VERSION ""

NS_ :

BS_:

BU_: SIDHigh IC HMIIOM ECUspare8

BO_ 2671902706 TesterFuncDiagMsg_Disp: 8 HMIIOM
 SG_ FuncDiagDataTester : 0|64@1+ (1,0) [0|0] ""  IC,SIDHigh

BO_ 2549448703 SIDHigh_TIPSITP_SIDHB_Down_H: 8 SIDHigh
 SG_ TIPSITP_SIDHeartbeat_Down_H : 0|64@1+ (1,0) [0|0] ""  HMIIOM

BO_ 2532663295 SIDHigh_TIPSITP_SIDData_Down_H5: 8 SIDHigh
 SG_ TIPSITP_SIDData_Down_H5 : 0|64@1+ (1,0) [0|0] ""  HMIIOM

BO_ 2532597759 SIDHigh_TIPSITP_SIDData_Down_H4: 8 SIDHigh
 SG_ TIPSITP_SIDData_Down_H4 : 0|64@1+ (1,0) [0|0] ""  HMIIOM

BO_ 2532532223 SIDHigh_TIPSITP_SIDData_Down_H3: 8 SIDHigh
 SG_ TIPSITP_SIDData_Down_H3 : 0|64@1+ (1,0) [0|0] ""  HMIIOM

BO_ 2532466687 SIDHigh_TIPSITP_SIDData_Down_H2: 8 SIDHigh
 SG_ TIPSITP_SIDData_Down_H2 : 0|64@1+ (1,0) [0|0] ""  HMIIOM

BO_ 2532401151 SIDHigh_TIPSITP_SIDData_Down_H1: 8 SIDHigh
 SG_ TIPSITP_SIDData_Down_H1 : 0|64@1+ (1,0) [0|0] ""  HMIIOM

BO_ 2515959807 SIDHigh_TIPSITP_SIDCtrl_Down_H: 8 SIDHigh
 SG_ TIPSITP_SIDCtrl_Down_H : 0|64@1+ (1,0) [0|0] ""  HMIIOM

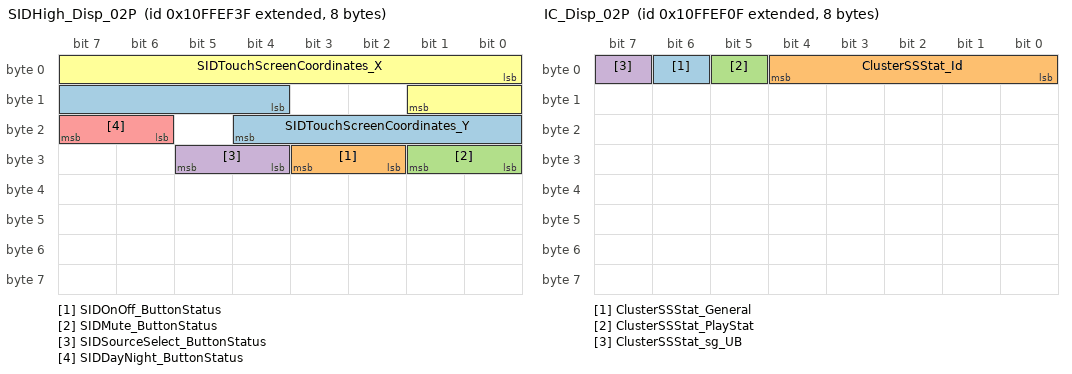
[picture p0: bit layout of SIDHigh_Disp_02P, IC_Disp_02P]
BO_ 2432692031 SIDHigh_Disp_02P: 8 SIDHigh
 SG_ SIDTouchScreenCoordinates_Y : 12|9@1+ (1,0) [0|511] ""  HMIIOM
 SG_ SIDOnOff_ButtonStatus : 26|2@1+ (1,0) [0|0] ""  HMIIOM
 SG_ SIDMute_ButtonStatus : 24|2@1+ (1,0) [0|0] ""  HMIIOM
 SG_ SIDSourceSelect_ButtonStatus : 28|2@1+ (1,0) [0|0] ""  HMIIOM
 SG_ SIDDayNight_ButtonStatus : 22|2@1+ (1,0) [0|0] ""  HMIIOM
 SG_ SIDTouchScreenCoordinates_X : 0|10@1+ (1,0) [0|1023] ""  HMIIOM

BO_ 2671833698 PhysDiagRespMsg_F2_62_Disp: 8 SIDHigh
 SG_ PhysDiagRespSig_F2_62 : 0|64@1+ (1,0) [0|0] ""  HMIIOM

BO_ 2671833697 PhysDiagRespMsg_F2_61_Disp: 8 IC
 SG_ PhysDiagRespSig_F2_61 : 0|64@1+ (1,0) [0|0] ""  HMIIOM

BO_ 2671796978 PhysDiagReqMsg_62_F2_Disp: 8 HMIIOM
 SG_ PhysDiagReqSig_62_F2 : 0|64@1+ (1,0) [0|0] ""  SIDHigh

BO_ 2671796722 PhysDiagReqMsg_61_F2_Disp: 8 HMIIOM
 SG_ PhysDiagReqSig_61_F2 : 0|64@1+ (1,0) [0|0] ""  IC

BO_ 2633990242 NmAsr_SIDHigh_Disp: 1 SIDHigh

BO_ 2633990241 NmAsr_IC_Disp: 1 IC

BO_ 2633990240 NmAsr_HMIIOM_Disp: 1 HMIIOM

BO_ 2671902708 IntTesterTGW2FuncDiagMsg_Disp: 8 HMIIOM
 SG_ FuncDiagDataIntTesterTGW2 : 0|64@1+ (1,0) [0|0] ""  SIDHigh,IC

BO_ 2549579775 IC_TIPSITP_SIDHeartbeat_Down_L: 8 IC
 SG_ TIPSITP_SIDHeartbeat_Down_L : 0|64@1+ (1,0) [0|0] ""  HMIIOM

BO_ 2532409343 IC_TIPSITP_SIDData_Down_L1: 8 IC
 SG_ TIPSITP_SIDData_Down_L1 : 0|64@1+ (1,0) [0|0] ""  HMIIOM

BO_ 2532671487 IC_TIPSITP_SIDDATA_Down_L5: 8 IC
 SG_ TIPSITP_SIDData_Down_L5 : 0|64@1+ (1,0) [0|0] ""  HMIIOM

BO_ 2532605951 IC_TIPSITP_SIDDATA_Down_L4: 8 IC
 SG_ TIPSITP_SIDData_Down_L4 : 0|64@1+ (1,0) [0|0] ""  HMIIOM

BO_ 2532540415 IC_TIPSITP_SIDDATA_Down_L3: 8 IC
 SG_ TIPSITP_SIDData_Down_L3 : 0|64@1+ (1,0) [0|0] ""  HMIIOM

BO_ 2532474879 IC_TIPSITP_SIDDATA_Down_L2: 8 IC
 SG_ TIPSITP_SIDData_Down_L2 : 0|64@1+ (1,0) [0|0] ""  HMIIOM

BO_ 2516090879 IC_TIPSITP_SIDCtrl_Down_L: 8 IC
 SG_ TIPSITP_SIDCtrl_Down_L : 0|64@1+ (1,0) [0|0] ""  HMIIOM

BO_ 2549907455 IC_TIPSITP_FDCHeartbeat_Down: 8 IC
 SG_ TIPSITP_FDCHeartbeat_Down : 0|64@1+ (1,0) [0|0] ""  HMIIOM

BO_ 2533195775 IC_TIPSITP_FDCData_Down: 8 IC
 SG_ TIPSITP_FDCData_Down : 0|64@1+ (1,0) [0|0] ""  HMIIOM

BO_ 2516221951 IC_TIPSITP_FDCCtrl_Down: 8 IC
 SG_ TIPSITP_FDCCtrl_Down : 0|64@1+ (1,0) [0|0] ""  HMIIOM

BO_ 2549841919 IC_TIPSITP_DIDHeartbeat_Down: 8 IC
 SG_ TIPSITP_DIDHeartbeat_Down : 0|64@1+ (1,0) [0|0] ""  HMIIOM

BO_ 2533130249 IC_TIPSITP_DIDData_Down6: 8 IC
 SG_ TIPSITP_DIDData_Down6 : 0|64@1+ (1,0) [0|0] ""  HMIIOM

BO_ 2533130247 IC_TIPSITP_DIDData_Down5: 8 IC
 SG_ TIPSITP_DIDData_Down5 : 0|64@1+ (1,0) [0|0] ""  HMIIOM

BO_ 2533130245 IC_TIPSITP_DIDData_Down4: 8 IC
 SG_ TIPSITP_DIDData_Down4 : 0|64@1+ (1,0) [0|0] ""  HMIIOM

BO_ 2533130243 IC_TIPSITP_DIDData_Down3: 8 IC
 SG_ TIPSITP_DIDData_Down3 : 0|64@1+ (1,0) [0|0] ""  HMIIOM

BO_ 2533130241 IC_TIPSITP_DIDData_Down2: 8 IC
 SG_ TIPSITP_DIDData_Down2 : 0|64@1+ (1,0) [0|0] ""  HMIIOM

BO_ 2533130239 IC_TIPSITP_DIDData_Down1: 8 IC
 SG_ TIPSITP_DIDData_Down1 : 0|64@1+ (1,0) [0|0] ""  HMIIOM

BO_ 2516156415 IC_TIPSITP_DIDCtrl_Down: 8 IC
 SG_ TIPSITP_DIDCtrl_Down : 0|64@1+ (1,0) [0|0] ""  HMIIOM

BO_ 2432691983 IC_Disp_02P: 8 IC
 SG_ ClusterSSStat_General : 6|1@1+ (1,0) [0|0] ""  HMIIOM
 SG_ ClusterSSStat_Id : 0|5@1+ (1,0) [0|31] ""  HMIIOM
 SG_ ClusterSSStat_PlayStat : 5|1@1+ (1,0) [0|0] ""  HMIIOM
 SG_ ClusterSSStat_sg_UB : 7|1@1+ (1,0) [0|0] ""  HMIIOM

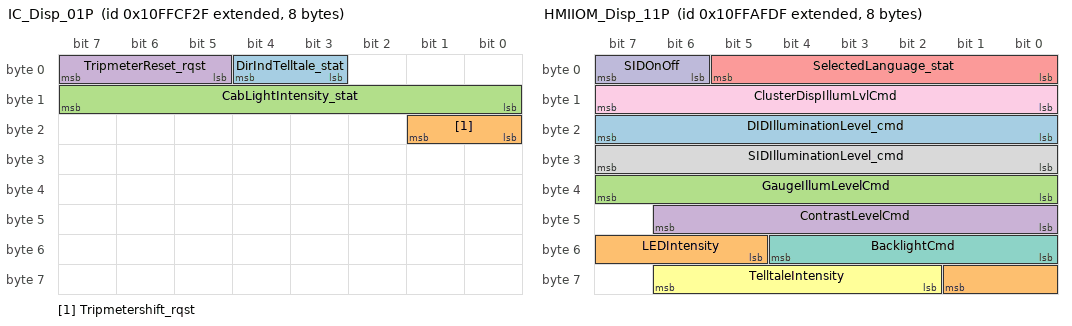
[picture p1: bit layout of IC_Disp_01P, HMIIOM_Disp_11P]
BO_ 2432683823 IC_Disp_01P: 8 IC
 SG_ DirIndTelltale_stat : 3|2@1+ (1,0) [0|0] ""  HMIIOM
 SG_ Tripmetershift_rqst : 16|2@1+ (1,0) [0|0] ""  HMIIOM
 SG_ CabLightIntensity_stat : 8|8@1+ (0.4,0) [0|102] "Percent"  HMIIOM
 SG_ TripmeterReset_rqst : 5|3@1+ (1,0) [0|0] ""  HMIIOM

BO_ 2549252095 HMIIOM_TIPSITP_SIDHeartbeat_Up: 8 HMIIOM
 SG_ TIPSITP_SIDHeartbeat_Up : 0|64@1+ (1,0) [0|0] ""  SIDHigh,IC

BO_ 2532655103 HMIIOM_TIPSITP_SIDData_Up5: 8 HMIIOM
 SG_ TIPSITP_SIDData_Up5 : 0|64@1+ (1,0) [0|0] ""  IC,SIDHigh

BO_ 2532589567 HMIIOM_TIPSITP_SIDData_Up4: 8 HMIIOM
 SG_ TIPSITP_SIDData_Up4 : 0|64@1+ (1,0) [0|0] ""  IC,SIDHigh

BO_ 2532524031 HMIIOM_TIPSITP_SIDData_Up3: 8 HMIIOM
 SG_ TIPSITP_SIDData_Up3 : 0|64@1+ (1,0) [0|0] ""  IC,SIDHigh

BO_ 2532458495 HMIIOM_TIPSITP_SIDData_Up2: 8 HMIIOM
 SG_ TIPSITP_SIDData_Up2 : 0|64@1+ (1,0) [0|0] ""  IC,SIDHigh

BO_ 2532392959 HMIIOM_TIPSITP_SIDData_Up1: 8 HMIIOM
 SG_ TIPSITP_SIDData_Up1 : 0|64@1+ (1,0) [0|0] ""  SIDHigh,IC

BO_ 2515808255 HMIIOM_TIPSITP_SIDCtrl_Up: 8 HMIIOM
 SG_ TIPSITP_SIDCtrl_Up : 0|64@1+ (1,0) [0|0] ""  IC,SIDHigh

BO_ 2549317631 HMIIOM_TIPSITP_FDCHeartbeat_Up: 8 HMIIOM
 SG_ TIPSITP_FDCHeartbeat_Up : 0|64@1+ (1,0) [0|0] ""  IC

BO_ 2533105665 HMIIOM_TIPSITP_FDCData_Up: 8 HMIIOM
 SG_ TIPSITP_FDCData_Up : 0|64@1+ (1,0) [0|0] ""  IC

BO_ 2515828735 HMIIOM_TIPSITP_FDCCtrl_Up: 8 HMIIOM
 SG_ TIPSITP_FDCCtrl_Up : 0|64@1+ (1,0) [0|0] ""  IC

BO_ 2549186559 HMIIOM_TIPSITP_DIDHeartbeat_Up: 8 HMIIOM
 SG_ TIPSITP_DIDHeartbeat_Up : 0|64@1+ (1,0) [0|0] ""  IC

BO_ 2532974598 HMIIOM_TIPSITP_DIDData_Up6: 8 HMIIOM
 SG_ TIPSITP_DIDData_Up6 : 0|64@1+ (1,0) [0|0] ""  IC

BO_ 2532974597 HMIIOM_TIPSITP_DIDData_Up5: 8 HMIIOM
 SG_ TIPSITP_DIDData_Up5 : 0|64@1+ (1,0) [0|0] ""  IC

BO_ 2532974596 HMIIOM_TIPSITP_DIDData_Up4: 8 HMIIOM
 SG_ TIPSITP_DIDData_Up4 : 0|64@1+ (1,0) [0|0] ""  IC

BO_ 2532974595 HMIIOM_TIPSITP_DIDData_Up3: 8 HMIIOM
 SG_ TIPSITP_DIDData_Up3 : 0|64@1+ (1,0) [0|0] ""  IC

BO_ 2532974594 HMIIOM_TIPSITP_DIDData_Up2: 8 HMIIOM
 SG_ TIPSITP_DIDData_Up2 : 0|64@1+ (1,0) [0|0] ""  IC

BO_ 2532974593 HMIIOM_TIPSITP_DIDData_Up1: 8 HMIIOM
 SG_ TIPSITP_DIDData_Up1 : 0|64@1+ (1,0) [0|0] ""  IC

BO_ 2515763199 HMIIOM_TIPSITP_DIDCtrl_Up: 8 HMIIOM
 SG_ TIPSITP_DIDCtrl_Up : 0|64@1+ (1,0) [0|0] ""  IC

BO_ 2449452895 HMIIOM_Disp_12P: 8 HMIIOM
 SG_ PresVal_DrivingMode : 0|24@1+ (1,0) [0|0] ""  IC

BO_ 2432675807 HMIIOM_Disp_11P: 8 HMIIOM
 SG_ DIDIlluminationLevel_cmd : 16|8@1+ (1,0) [0|255] "Percent"  IC
 SG_ LEDIntensity : 53|5@1+ (1,0) [0|0] ""  IC
 SG_ GaugeIllumLevelCmd : 32|8@1+ (1,0) [0|255] "Percent"  IC
 SG_ ContrastLevelCmd : 40|7@1+ (1,0) [0|127] "Percent"  IC
 SG_ SelectedLanguage_stat : 0|6@1+ (1,0) [0|0] ""  IC,SIDHigh
 SG_ TelltaleIntensity : 58|5@1+ (1,0) [0|0] ""  IC
 SG_ BacklightCmd : 48|5@1+ (1,0) [0|0] ""  IC,SIDHigh
 SG_ SIDIlluminationLevel_cmd : 24|8@1+ (1,0) [0|255] "Percent"  SIDHigh,IC
 SG_ ClusterDispIllumLvlCmd : 8|8@1+ (1,0) [0|255] "Percent"  IC
 SG_ SIDOnOff : 6|2@1+ (1,0) [0|0] ""  SIDHigh

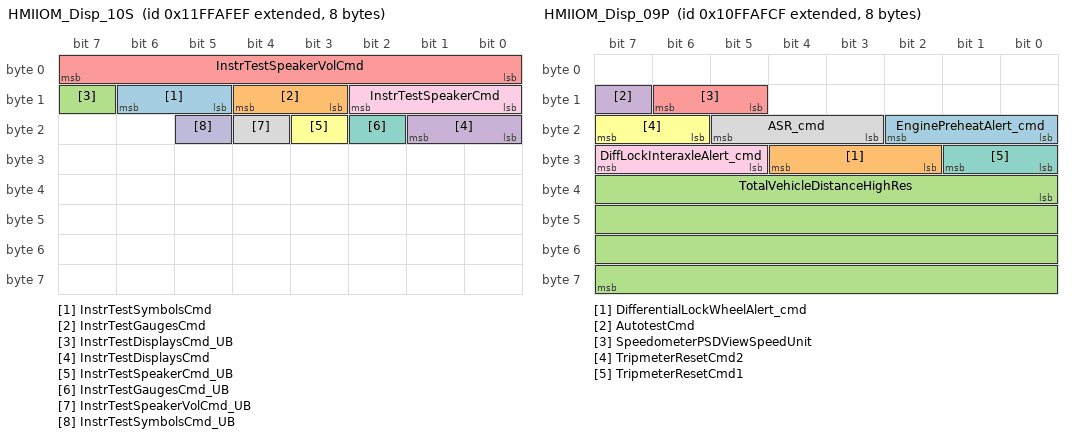
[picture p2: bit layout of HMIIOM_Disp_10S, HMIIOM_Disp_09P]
BO_ 2449453039 HMIIOM_Disp_10S: 8 HMIIOM
 SG_ InstrTestSymbolsCmd : 13|2@1+ (1,0) [0|0] ""  IC
 SG_ InstrTestGaugesCmd : 11|2@1+ (1,0) [0|0] ""  IC
 SG_ InstrTestDisplaysCmd_UB : 15|1@1+ (1,0) [0|1] ""  IC,SIDHigh
 SG_ InstrTestDisplaysCmd : 16|2@1+ (1,0) [0|0] ""  IC,SIDHigh
 SG_ InstrTestSpeakerVolCmd : 0|8@1+ (1,0) [0|255] ""  IC
 SG_ InstrTestSpeakerCmd_UB : 19|1@1+ (1,0) [0|1] ""  IC
 SG_ InstrTestGaugesCmd_UB : 18|1@1+ (1,0) [0|1] ""  IC
 SG_ InstrTestSpeakerVolCmd_UB : 20|1@1+ (1,0) [0|1] ""  IC
 SG_ InstrTestSpeakerCmd : 8|3@1+ (1,0) [0|0] ""  IC
 SG_ InstrTestSymbolsCmd_UB : 21|1@1+ (1,0) [0|1] ""  IC

BO_ 2432675791 HMIIOM_Disp_09P: 8 HMIIOM
 SG_ EnginePreheatAlert_cmd : 16|3@1+ (1,0) [0|0] ""  IC
 SG_ DifferentialLockWheelAlert_cmd : 26|3@1+ (1,0) [0|0] ""  IC
 SG_ TotalVehicleDistanceHighRes : 32|32@1+ (5,0) [0|21474836475] "m"  IC,SIDHigh
 SG_ AutotestCmd : 15|1@1+ (1,0) [0|0] ""  IC
 SG_ SpeedometerPSDViewSpeedUnit : 13|2@1+ (1,0) [0|0] ""  IC
 SG_ TripmeterResetCmd2 : 22|2@1+ (1,0) [0|0] ""  IC
 SG_ TripmeterResetCmd1 : 24|2@1+ (1,0) [0|0] ""  IC
 SG_ ASR_cmd : 19|3@1+ (1,0) [0|0] ""  IC
 SG_ DiffLockInteraxleAlert_cmd : 29|3@1+ (1,0) [0|0] ""  IC

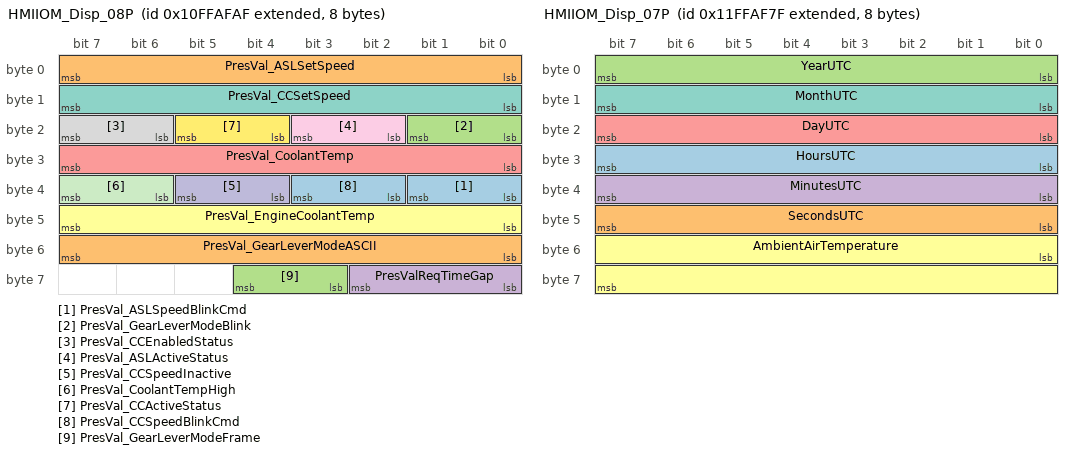
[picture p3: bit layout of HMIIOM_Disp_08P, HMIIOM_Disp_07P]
BO_ 2432675759 HMIIOM_Disp_08P: 8 HMIIOM
 SG_ PresVal_ASLSpeedBlinkCmd : 32|2@1+ (1,0) [0|0] ""  IC
 SG_ PresVal_ASLSetSpeed : 0|8@1+ (1,0) [0|255] "NotApplicable"  IC
 SG_ PresVal_GearLeverModeBlink : 16|2@1+ (1,0) [0|0] ""  IC
 SG_ PresValReqTimeGap : 56|3@1+ (1,0) [0|0] ""  IC
 SG_ PresVal_CoolantTemp : 24|8@1+ (1,-40) [-40|215] "DegreeC"  IC
 SG_ PresVal_EngineCoolantTemp : 40|8@1+ (0.4,0) [0|102] "Percent"  IC
 SG_ PresVal_CCSetSpeed : 8|8@1+ (1,0) [0|255] "NotApplicable"  IC
 SG_ PresVal_CCEnabledStatus : 22|2@1+ (1,0) [0|0] ""  IC
 SG_ PresVal_ASLActiveStatus : 18|2@1+ (1,0) [0|0] ""  IC
 SG_ PresVal_CCSpeedInactive : 36|2@1+ (1,0) [0|0] ""  IC
 SG_ PresVal_CoolantTempHigh : 38|2@1+ (1,0) [0|0] ""  IC
 SG_ PresVal_CCActiveStatus : 20|2@1+ (1,0) [0|0] ""  IC
 SG_ PresVal_CCSpeedBlinkCmd : 34|2@1+ (1,0) [0|0] ""  IC
 SG_ PresVal_GearLeverModeASCII : 48|8@1+ (1,0) [0|0] ""  IC
 SG_ PresVal_GearLeverModeFrame : 59|2@1+ (1,0) [0|0] ""  IC

BO_ 2449452927 HMIIOM_Disp_07P: 8 HMIIOM
 SG_ HoursUTC : 24|8@1+ (1,0) [0|255] "h"  SIDHigh,IC
 SG_ SecondsUTC : 40|8@1+ (0.25,0) [0|63.75] "s"  IC,SIDHigh
 SG_ YearUTC : 0|8@1+ (1,1985) [1985|2240] "Years"  SIDHigh,IC
 SG_ MinutesUTC : 32|8@1+ (1,0) [0|255] "min"  IC,SIDHigh
 SG_ DayUTC : 16|8@1+ (0.25,0) [0|63.75] "Days"  IC,SIDHigh
 SG_ AmbientAirTemperature : 48|16@1+ (0.03125,-273) [-273|1774.96875] "DegreeC"  IC,SIDHigh
 SG_ MonthUTC : 8|8@1+ (1,0) [0|255] "Months"  SIDHigh,IC

BO_ 2449452879 HMIIOM_Disp_06P: 8 HMIIOM
 SG_ PresVal_HighResTotalVehDist : 32|32@1+ (0.1,0) [0|429496729.5] ""  IC
 SG_ PresVal_HighResolutionTripDist : 0|32@1+ (0.1,0) [0|429496729.5] ""  IC

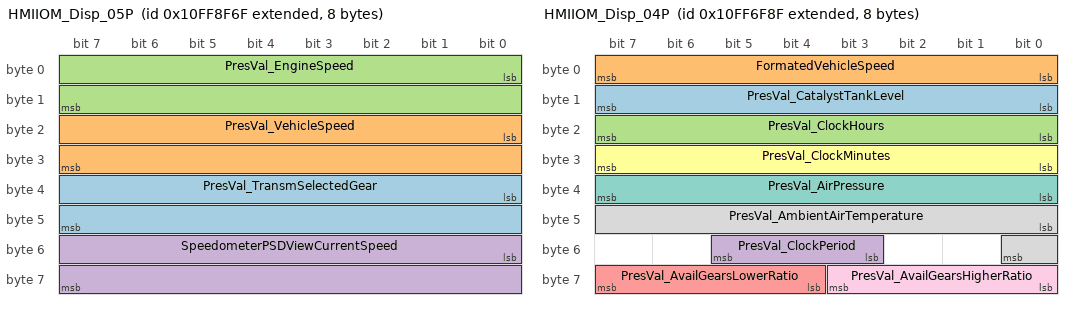
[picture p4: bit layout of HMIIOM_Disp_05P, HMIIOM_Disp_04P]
BO_ 2432667503 HMIIOM_Disp_05P: 8 HMIIOM
 SG_ PresVal_TransmSelectedGear : 32|16@1+ (1,0) [0|0] ""  IC
 SG_ PresVal_VehicleSpeed : 16|16@1+ (0.00390625,0) [0|255.99609375] "NotApplicable"  IC
 SG_ PresVal_EngineSpeed : 0|16@1+ (0.125,0) [0|8191.875] "rpm"  IC
 SG_ SpeedometerPSDViewCurrentSpeed : 48|16@1+ (0.00390625,0) [0|255.99609375] "NotApplicable"  IC

BO_ 2432659343 HMIIOM_Disp_04P: 8 HMIIOM
 SG_ PresVal_CatalystTankLevel : 8|8@1+ (0.4,0) [0|102] "Percent"  IC
 SG_ FormatedVehicleSpeed : 0|8@1+ (1,0) [0|255] "NotApplicable"  IC
 SG_ PresVal_ClockHours : 16|8@1+ (1,0) [0|255] "h"  IC
 SG_ PresVal_ClockPeriod : 51|3@1+ (1,0) [0|0] ""  IC
 SG_ PresVal_AvailGearsLowerRatio : 60|4@1+ (1,0) [0|15] "Count"  IC
 SG_ PresVal_ClockMinutes : 24|8@1+ (1,0) [0|255] "min"  IC
 SG_ PresVal_AirPressure : 32|8@1+ (8,0) [0|2040] "kPa"  IC
 SG_ PresVal_AmbientAirTemperature : 40|9@1+ (0.5,-60) [-60|195.5] "NotApplicable"  IC
 SG_ PresVal_AvailGearsHigherRatio : 56|4@1+ (1,0) [0|15] "Count"  IC

BO_ 2432651183 HMIIOM_Disp_03P: 8 HMIIOM
 SG_ PresVal_OdometerUnit : 8|2@1+ (1,0) [0|0] ""  IC
 SG_ ZoningBandsActiveBlueLEDRange2 : 47|3@1+ (1,0) [0|0] ""  IC
 SG_ ZoningBandsActiveBlueLEDRange1 : 26|3@1+ (1,0) [0|0] ""  IC
 SG_ PresVal_LowFuelLevelWrn_stat : 14|2@1+ (1,0) [0|0] ""  IC
 SG_ LCDFormattedVehSpdBlink_cmd : 29|2@1+ (1,0) [0|0] ""  IC
 SG_ PresVal_ACCReducedMode : 4|2@1+ (1,0) [0|0] ""  IC
 SG_ PresVal_FuelLevel : 56|8@1+ (0.4,0) [0|102] "Percent"  IC
 SG_ PresVal_AuxiliaryBrakesActivat : 20|2@1+ (1,0) [0|0] ""  IC
 SG_ PresVal_AmbientAirTempUnit : 24|2@1+ (1,0) [0|0] ""  IC
 SG_ PresVal_TargetDetected : 10|2@1+ (1,0) [0|0] ""  IC
 SG_ SeatBeltReminderAlert_cmd : 38|3@1+ (1,0) [0|0] ""  IC
 SG_ PresVal_CrossCountryStatus : 2|2@1+ (1,0) [0|0] ""  IC
 SG_ PresVal_TripmeterChoice : 16|2@1+ (1,0) [0|0] ""  IC
 SG_ ZoningBandsActiveGreenLEDRng2 : 44|3@1+ (1,0) [0|0] ""  IC
 SG_ SIDPresentationMode : 50|4@1+ (1,0) [0|0] ""  SIDHigh
 SG_ VehicleSpeedLCDSpeedUnitCmd : 22|2@1+ (1,0) [0|0] ""  IC
 SG_ PresVal_CatalystTankLevelLow : 18|2@1+ (1,0) [0|0] ""  IC
 SG_ PresVal_ACCStatus : 12|2@1+ (1,0) [0|0] ""  IC
 SG_ PresVal_AuxiliaryBrakesPos : 32|3@1+ (1,0) [0|0] ""  IC
 SG_ PresVal_EngSpdCtrlStatus : 54|2@1+ (1,0) [0|0] ""  IC
 SG_ ZoningBandsActiveRedLEDRange1 : 35|3@1+ (1,0) [0|0] ""  IC
 SG_ PresVal_LowAmbientTempWarning : 0|2@1+ (1,0) [0|0] ""  IC
 SG_ ZoningBandsActiveGreenLEDRng1 : 41|3@1+ (1,0) [0|0] ""  IC

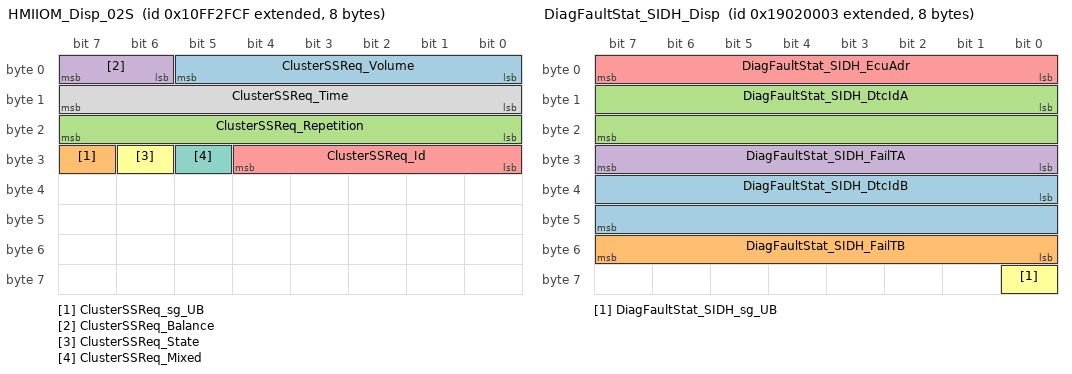
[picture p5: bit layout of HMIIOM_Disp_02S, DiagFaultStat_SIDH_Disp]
BO_ 2432643023 HMIIOM_Disp_02S: 8 HMIIOM
 SG_ ClusterSSReq_Volume : 0|6@1+ (1,0) [0|63] ""  IC
 SG_ ClusterSSReq_sg_UB : 31|1@1+ (1,0) [0|0] ""  IC
 SG_ ClusterSSReq_Repetition : 16|8@1+ (1,0) [0|255] ""  IC
 SG_ ClusterSSReq_Balance : 6|2@1+ (1,0) [0|0] ""  IC
 SG_ ClusterSSReq_Id : 24|5@1+ (1,0) [0|31] ""  IC
 SG_ ClusterSSReq_State : 30|1@1+ (1,0) [0|0] ""  IC
 SG_ ClusterSSReq_Mixed : 29|1@1+ (1,0) [0|0] ""  IC
 SG_ ClusterSSReq_Time : 8|8@1+ (0.1,0) [0|25.5] "s"  IC

BO_ 2432634863 HMIIOM_Disp_01P: 8 HMIIOM
 SG_ DippedBeamAlert_cmd : 15|3@1+ (1,0) [0|0] ""  IC
 SG_ VehicleMode : 54|4@1+ (1,0) [0|0] ""  IC,SIDHigh
 SG_ LiftAxle1Alert_cmd : 6|3@1+ (1,0) [0|0] ""  IC
 SG_ DirIndicatorRtTrailerAlert_cmd : 18|3@1+ (1,0) [0|0] ""  IC
 SG_ FogLightFrontAlert_cmd : 45|3@1+ (1,0) [0|0] ""  IC
 SG_ LiftAxle2Alert_cmd : 0|3@1+ (1,0) [0|0] ""  IC
 SG_ ExtraSpotLampsAlert_cmd : 24|3@1+ (1,0) [0|0] ""  IC
 SG_ AdBlueLevelLowAlert_cmd : 3|3@1+ (1,0) [0|0] ""  IC
 SG_ DirIndicatorLtTrailerAlert_cmd : 42|3@1+ (1,0) [0|0] ""  IC
 SG_ EngineMalFunctionAlert_cmd : 39|3@1+ (1,0) [0|0] ""  IC
 SG_ FuelLevelLowAlert_cmd : 36|3@1+ (1,0) [0|0] ""  IC
 SG_ PosLightAlert_cmd : 48|3@1+ (1,0) [0|0] ""  IC
 SG_ MainBeamAlert_cmd : 12|3@1+ (1,0) [0|0] ""  IC
 SG_ DirIndicatorRightAlert_cmd : 9|3@1+ (1,0) [0|0] ""  IC
 SG_ ParkBrakeAlert_cmd : 21|3@1+ (1,0) [0|0] ""  IC
 SG_ FogLightRearAlert_cmd : 30|3@1+ (1,0) [0|0] ""  IC
 SG_ DirIndicatorLeftAlert_cmd : 27|3@1+ (1,0) [0|0] ""  IC
 SG_ CheckAlert_cmd : 33|3@1+ (1,0) [0|0] ""  IC
 SG_ StopAlert_cmd : 51|3@1+ (1,0) [0|0] ""  IC
 SG_ VehicleMode_UB : 58|1@1+ (1,0) [0|0] ""  IC,SIDHigh

BO_ 2671964770 DiagUUDTRespMsg1_F2_62_Disp: 8 SIDHigh
 SG_ DiagUUDTRespSig_F2_62 : 0|64@1+ (1,0) [0|0] ""  HMIIOM

BO_ 2671964769 DiagUUDTRespMsg1_F2_61_Disp: 8 IC
 SG_ DiagUUDTRespSig_F2_61 : 0|64@1+ (1,0) [0|0] ""  HMIIOM

BO_ 2671834210 DiagRespMsgIntTGW2_F4_62_Disp: 8 SIDHigh
 SG_ InternalTesterDiagSig_F4_62 : 0|64@1+ (1,0) [0|0] ""  HMIIOM

BO_ 2671834209 DiagRespMsgIntTGW2_F4_61_Disp: 8 IC
 SG_ InternalTesterDiagSig_F4_61 : 0|64@1+ (1,0) [0|0] ""  HMIIOM

BO_ 2671833954 DiagRespMsgIntHMIIOM_F3_62_Disp: 8 SIDHigh
 SG_ InternalTesterDiagSig_F3_62 : 0|64@1+ (1,0) [0|0] ""  HMIIOM

BO_ 2671833953 DiagRespMsgIntHMIIOM_F3_61_Disp: 8 IC
 SG_ InternalTesterDiagSig_F3_61 : 0|64@1+ (1,0) [0|0] ""  HMIIOM

BO_ 2671796980 DiagReqMsgIntTGW2_62_F4_Disp: 8 HMIIOM
 SG_ InternalTesterDiagSig_62_F4 : 0|64@1+ (1,0) [0|0] ""  SIDHigh

BO_ 2671796724 DiagReqMsgIntTGW2_61_F4_Disp: 8 HMIIOM
 SG_ InternalTesterDiagSig_61_F4 : 0|64@1+ (1,0) [0|0] ""  IC

BO_ 2671796979 DiagReqMsgIntHMIIOM_62_F3_Disp: 8 HMIIOM
 SG_ InternalTesterDiagSig_62_F3 : 0|64@1+ (1,0) [0|0] ""  SIDHigh

BO_ 2671796723 DiagReqMsgIntHMIIOM_61_F3_Disp: 8 HMIIOM
 SG_ InternalTesterDiagSig_61_F3 : 0|64@1+ (1,0) [0|0] ""  IC

BO_ 2567045123 DiagFaultStat_SIDH_Disp: 8 SIDHigh
 SG_ DiagFaultStat_SIDH_DtcIdB : 32|16@1+ (1,0) [0|65535] ""  HMIIOM
 SG_ DiagFaultStat_SIDH_FailTB : 48|8@1+ (1,0) [0|255] ""  HMIIOM
 SG_ DiagFaultStat_SIDH_DtcIdA : 8|16@1+ (1,0) [0|65535] ""  HMIIOM
 SG_ DiagFaultStat_SIDH_FailTA : 24|8@1+ (1,0) [0|255] ""  HMIIOM
 SG_ DiagFaultStat_SIDH_EcuAdr : 0|8@1+ (1,0) [0|255] ""  HMIIOM
 SG_ DiagFaultStat_SIDH_sg_UB : 56|1@1+ (1,0) [0|0] ""  HMIIOM

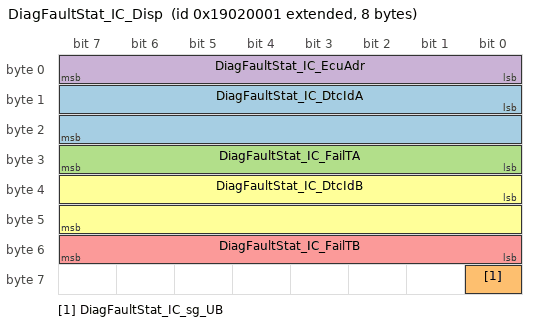
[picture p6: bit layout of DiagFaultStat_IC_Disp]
BO_ 2567045121 DiagFaultStat_IC_Disp: 8 IC
 SG_ DiagFaultStat_IC_DtcIdA : 8|16@1+ (1,0) [0|65535] ""  HMIIOM
 SG_ DiagFaultStat_IC_sg_UB : 56|1@1+ (1,0) [0|0] ""  HMIIOM
 SG_ DiagFaultStat_IC_FailTA : 24|8@1+ (1,0) [0|255] ""  HMIIOM
 SG_ DiagFaultStat_IC_EcuAdr : 0|8@1+ (1,0) [0|255] ""  HMIIOM
 SG_ DiagFaultStat_IC_FailTB : 48|8@1+ (1,0) [0|255] ""  HMIIOM
 SG_ DiagFaultStat_IC_DtcIdB : 32|16@1+ (1,0) [0|65535] ""  HMIIOM

BO_ 2634020450 Debug6_SID_Display: 8 SIDHigh
 SG_ Debug_6_SID : 0|64@1+ (1,0) [0|0] "" Vector__XXX

BO_ 2634020449 Debug6_IC_Display: 8 IC
 SG_ Debug_6_IC : 0|64@1+ (1,0) [0|0] "" Vector__XXX

BO_ 2634020194 Debug5_SID_Display: 8 SIDHigh
 SG_ Debug_5_SID : 0|64@1+ (1,0) [0|0] "" Vector__XXX

BO_ 2634020193 Debug5_IC_Display: 8 IC
 SG_ Debug_5_IC : 0|64@1+ (1,0) [0|0] "" Vector__XXX

BO_ 2634019938 Debug4_SID_Display: 8 SIDHigh
 SG_ Debug_4_SID : 0|64@1+ (1,0) [0|0] "" Vector__XXX

BO_ 2634019937 Debug4_IC_Display: 8 IC
 SG_ Debug_4_IC : 0|64@1+ (1,0) [0|0] "" Vector__XXX

BO_ 2634019682 Debug3_SID_Display: 8 SIDHigh
 SG_ Debug_3_SID : 0|64@1+ (1,0) [0|0] "" Vector__XXX

BO_ 2634019681 Debug3_IC_Display: 8 IC
 SG_ Debug_3_IC : 0|64@1+ (1,0) [0|0] "" Vector__XXX

BO_ 2634019426 Debug2_SID_Display: 8 SIDHigh
 SG_ Debug_2_SID : 0|64@1+ (1,0) [0|0] "" Vector__XXX

BO_ 2634019425 Debug2_IC_Display: 8 IC
 SG_ Debug_2_IC : 0|64@1+ (1,0) [0|0] "" Vector__XXX

BO_ 2634019170 Debug1_SID_Display: 8 Vector__XXX
 SG_ Debug_1_SID : 0|64@1+ (1,0) [0|0] ""  SIDHigh

BO_ 2634019169 Debug1_IC_Display: 8 Vector__XXX
 SG_ Debug_1_IC : 0|64@1+ (1,0) [0|0] ""  IC

BO_ 2633994289 AnmMsg_SIDHigh_DisplaySubnet: 4 SIDHigh
 SG_ AnmSig_SIDHigh_DisplaySubnet : 0|32@1+ (1,0) [0|4294967295] ""  ECUspare8,HMIIOM,IC

BO_ 2633994288 AnmMsg_IC_DisplaySubnet: 4 IC
 SG_ AnmSig_IC_DisplaySubnet : 0|32@1+ (1,0) [0|4294967295] ""  HMIIOM,ECUspare8,SIDHigh

BO_ 2633994287 AnmMsg_HMIIOM_DisplaySubnet: 4 HMIIOM
 SG_ AnmSig_HMIIOM_DisplaySubnet : 0|32@1+ (1,0) [0|4294967295] ""  IC,SIDHigh,ECUspare8

BO_ 2633994322 AnmMsg_ECUspare8_DisplaySubnet: 4 ECUspare8
 SG_ AnmSig_ECUspare8_DisplaySubnet : 0|32@1+ (1,0) [0|4294967295] ""  IC,HMIIOM,SIDHigh

CM_ "COM_MATRIX_1.1.1";
CM_ SG_ 2432683823 CabLightIntensity_stat "254 Error ; 255 Not available";
CM_ SG_ 2432675807 DIDIlluminationLevel_cmd "254 Error ; 255 Not available";
CM_ SG_ 2432675807 SIDIlluminationLevel_cmd "254 Error ; 255 Not available";
CM_ SG_ 2432675791 TotalVehicleDistanceHighRes "4261412864 - 4278190079 Error ; 4278190080 - 4294967295 Not available";
CM_ SG_ 2432675759 PresVal_ASLSetSpeed "254 Error ; 255 Not available";
CM_ SG_ 2432675759 PresVal_CoolantTemp "254 Error ; 255 Not available";
CM_ SG_ 2432675759 PresVal_EngineCoolantTemp "254 Error ; 255 Not available";
CM_ SG_ 2432675759 PresVal_CCSetSpeed "254 Error ; 255 Not available";
CM_ SG_ 2449452927 HoursUTC "254 Error ; 255 Not available";
CM_ SG_ 2449452927 SecondsUTC "254 Error ; 255 Not available";
CM_ SG_ 2449452927 YearUTC "254 Error ; 255 Not available";
CM_ SG_ 2449452927 MinutesUTC "254 Error ; 255 Not available";
CM_ SG_ 2449452927 DayUTC "254 Error ; 255 Not available";
CM_ SG_ 2449452927 AmbientAirTemperature "65024 - 65279 Error ; 65280 - 65535 Not available";
CM_ SG_ 2449452927 MonthUTC "254 Error ; 255 Not available";
CM_ SG_ 2449452879 PresVal_HighResTotalVehDist "4261412864 - 4278190079 Error ; 4278190080 - 4294967295 Not available";
CM_ SG_ 2449452879 PresVal_HighResolutionTripDist "4261412864 - 4278190079 Error ; 4278190080 - 4294967295 Not available";
CM_ SG_ 2432667503 PresVal_VehicleSpeed "65024 - 65279 Error ; 65280 - 65535 Not available";
CM_ SG_ 2432667503 PresVal_EngineSpeed "65024 - 65279 Error ; 65280 - 65535 Not available";
CM_ SG_ 2432659343 PresVal_CatalystTankLevel "254 Error ; 255 Not available";
CM_ SG_ 2432659343 FormatedVehicleSpeed "254 Error ; 255 Not available";
CM_ SG_ 2432659343 PresVal_AirPressure "254 Error ; 255 Not available";
CM_ SG_ 2432659343 PresVal_AmbientAirTemperature "510 Error ; 511 Not available";
CM_ SG_ 2432651183 PresVal_FuelLevel "254 Error ; 255 Not available";
BA_DEF_ BO_  "GenMsgStartDelayTime" INT 0 0;
BA_DEF_ BO_  "GenMsgDelayTime" INT 0 0;
BA_DEF_ BO_  "GenMsgCycleTime" INT 0 0;
BA_DEF_ BO_  "GenMsgSendType" ENUM  "Cyclic","NotUsed","NotUsed","NotUsed","NotUsed","NotUsed","NotUsed","IfActive","NoMsgSendType","NotUsed";
BA_DEF_ SG_  "GenSigStartValue" INT 0 0;
BA_DEF_ SG_  "GenSigCycleTimeActive" INT 0 0;
BA_DEF_ SG_  "GenSigCycleTime" INT 0 0;
BA_DEF_ SG_  "GenSigSendType" ENUM  "Cyclic","OnWrite","OnWriteWithRepetition","OnChange","OnChangeWithRepetition","IfActive","IfActiveWithRepetition","NoSigSendType","NotUsed","NotUsed","NotUsed","NotUsed","NotUsed";
BA_DEF_  "Baudrate" INT 0 1000000;
BA_DEF_  "BusType" STRING ;
BA_DEF_  "NmType" STRING ;
BA_DEF_  "Manufacturer" STRING ;
BA_DEF_  "VersionYear" INT 0 99;
BA_DEF_  "VersionNumber" INT 0 99;
BA_DEF_  "VersionMonth" INT 1 12;
BA_DEF_  "VersionDay" INT 1 31;
BA_DEF_ BO_  "VFrameFormat" ENUM  "StandardCAN","ExtendedCAN","reserved","J1939PG";
BA_DEF_ BU_  "TpOwnSystemEcuNumber" HEX 0 255;
BA_DEF_ SG_  "SigType" ENUM  "Default","Range","RangeSigned","ASCII","Discrete","Control","ReferencePGN","DTC","StringDelimiter","StringLength","StringLengthControl";
BA_DEF_ SG_  "SeToolVersion_SIGNAL" STRING ;
BA_DEF_ SG_  "SeToolUniqueID_SIGNAL" STRING ;
BA_DEF_ SG_  "SeToolName_SIGNAL" STRING ;
BA_DEF_ SG_  "SeToolItemID_SIGNAL" STRING ;
BA_DEF_ SG_  "SeToolAncestorID_SIGNAL" STRING ;
BA_DEF_ BU_  "NmStationAddress" INT 0 255;
BA_DEF_  "NmAsrWaitBusSleepTime" INT 0 65535;
BA_DEF_  "NmAsrTimeoutTime" INT 0 65535;
BA_DEF_  "NmAsrRepeatMessageTime" INT 0 65535;
BA_DEF_ BU_  "NmAsrNodeIdentifier" HEX 0 253;
BA_DEF_ BU_  "NmAsrNode" ENUM  "No","Yes";
BA_DEF_  "NmAsrMessageCount" INT 1 256;
BA_DEF_ BO_  "NmAsrMessage" ENUM  "No","Yes";
BA_DEF_  "NmAsrCanMsgCycleTime" INT 0 65535;
BA_DEF_  "NmAsrBaseAddress" HEX 0 536870911;
BA_DEF_ SG_  "NeedsUpdateBit" ENUM  "No","Yes";
BA_DEF_ SG_  "MmAnSignal" ENUM  "No","Yes";
BA_DEF_ SG_  "GenSigMaxLatency" INT 0 65535;
BA_DEF_ SG_  "GenSigILSupport" ENUM  "Yes","No";
BA_DEF_ BO_  "GenMsgRequestable" INT 0 1;
BA_DEF_ BO_  "GenMsgILSupport" ENUM  "No","Yes";
BA_DEF_ BU_  "DiagnosticClientAddress" HEX 0 255;
BA_DEF_ BO_  "DiagUUDTResponse" ENUM  "No","Yes";
BA_DEF_ BO_  "DiagState" ENUM  "No","Yes";
BA_DEF_ BU_  "DiagRole" ENUM  "None","OBDTester","ExternalTester","InternalTester";
BA_DEF_ BO_  "DiagResponse" ENUM  "No","Yes";
BA_DEF_ BO_  "DiagRequest" ENUM  "No","Yes";
BA_DEF_ BO_  "DiagConnection" HEX 0 65535;
BA_DEF_  "DBName" STRING ;
BA_DEF_ BO_  "CanTpSTmin" INT 0 255;
BA_DEF_ BO_  "CanTpFcFrameId" HEX 0 2147483647;
BA_DEF_ BO_  "CanTpBs" INT 0 255;
BA_DEF_REL_ BU_SG_REL_  "GenSigTimeoutTime" INT 0 65535;
BA_DEF_REL_ BU_SG_REL_  "GenSigFirstTimeoutTime" INT 0 65535;
BA_DEF_DEF_  "GenMsgStartDelayTime" 0;
BA_DEF_DEF_  "GenMsgDelayTime" 0;
BA_DEF_DEF_  "GenMsgCycleTime" 0;
BA_DEF_DEF_  "GenMsgSendType" "Cyclic";
BA_DEF_DEF_  "GenSigStartValue" 0;
BA_DEF_DEF_  "GenSigCycleTimeActive" 0;
BA_DEF_DEF_  "GenSigCycleTime" 0;
BA_DEF_DEF_  "GenSigSendType" "Cyclic";
BA_DEF_DEF_  "Baudrate" 500000;
BA_DEF_DEF_  "BusType" "";
BA_DEF_DEF_  "NmType" "";
BA_DEF_DEF_  "Manufacturer" "VOLVO_AB";
BA_DEF_DEF_  "VersionYear" 0;
BA_DEF_DEF_  "VersionNumber" 0;
BA_DEF_DEF_  "VersionMonth" 1;
BA_DEF_DEF_  "VersionDay" 1;
BA_DEF_DEF_  "VFrameFormat" "ExtendedCAN";
BA_DEF_DEF_  "TpOwnSystemEcuNumber" 0;
BA_DEF_DEF_  "SigType" "Default";
BA_DEF_DEF_  "SeToolVersion_SIGNAL" "";
BA_DEF_DEF_  "SeToolUniqueID_SIGNAL" "";
BA_DEF_DEF_  "SeToolName_SIGNAL" "";
BA_DEF_DEF_  "SeToolItemID_SIGNAL" "";
BA_DEF_DEF_  "SeToolAncestorID_SIGNAL" "";
BA_DEF_DEF_  "NmStationAddress" 254;
BA_DEF_DEF_  "NmAsrWaitBusSleepTime" 750;
BA_DEF_DEF_  "NmAsrTimeoutTime" 5000;
BA_DEF_DEF_  "NmAsrRepeatMessageTime" 300;
BA_DEF_DEF_  "NmAsrNodeIdentifier" 0;
BA_DEF_DEF_  "NmAsrNode" "Yes";
BA_DEF_DEF_  "NmAsrMessageCount" 256;
BA_DEF_DEF_  "NmAsrMessage" "No";
BA_DEF_DEF_  "NmAsrCanMsgCycleTime" 200;
BA_DEF_DEF_  "NmAsrBaseAddress" 486506496;
BA_DEF_DEF_  "NeedsUpdateBit" "No";
BA_DEF_DEF_  "MmAnSignal" "No";
BA_DEF_DEF_  "GenSigMaxLatency" 0;
BA_DEF_DEF_  "GenSigILSupport" "Yes";
BA_DEF_DEF_  "GenMsgRequestable" 1;
BA_DEF_DEF_  "GenMsgILSupport" "Yes";
BA_DEF_DEF_  "DiagnosticClientAddress" 0;
BA_DEF_DEF_  "DiagUUDTResponse" "No";
BA_DEF_DEF_  "DiagState" "No";
BA_DEF_DEF_  "DiagRole" "None";
BA_DEF_DEF_  "DiagResponse" "No";
BA_DEF_DEF_  "DiagRequest" "No";
BA_DEF_DEF_  "DiagConnection" 0;
BA_DEF_DEF_  "DBName" "";
BA_DEF_DEF_  "CanTpSTmin" 0;
BA_DEF_DEF_  "CanTpFcFrameId" 2147483647;
BA_DEF_DEF_  "CanTpBs" 255;
BA_DEF_DEF_REL_ "GenSigTimeoutTime" 0;
BA_DEF_DEF_REL_ "GenSigFirstTimeoutTime" 0;
BA_ "VersionYear" 11;
BA_ "VersionNumber" 1;
BA_ "VersionMonth" 9;
BA_ "VersionDay" 30;
BA_ "BusType" "CAN";
BA_ "NmType" "NmAsr";
BA_ "DBName" "DisplaySubnet";
BA_ "NmAsrNodeIdentifier" BU_ SIDHigh 98;
BA_ "TpOwnSystemEcuNumber" BU_ SIDHigh 98;
BA_ "NmAsrNodeIdentifier" BU_ IC 97;
BA_ "TpOwnSystemEcuNumber" BU_ IC 97;
BA_ "NmAsrNodeIdentifier" BU_ HMIIOM 96;
BA_ "TpOwnSystemEcuNumber" BU_ HMIIOM 96;
BA_ "DiagnosticClientAddress" BU_ HMIIOM 243;
BA_ "DiagRole" BU_ HMIIOM 3;
BA_ "GenMsgSendType" BO_ 2671902706 8;
BA_ "GenMsgILSupport" BO_ 2671902706 0;
BA_ "DiagState" BO_ 2671902706 1;
BA_ "DiagConnection" BO_ 2671902706 62049;
BA_ "GenMsgSendType" BO_ 2549448703 8;
BA_ "GenMsgSendType" BO_ 2532663295 8;
BA_ "GenMsgSendType" BO_ 2532597759 8;
BA_ "GenMsgSendType" BO_ 2532532223 8;
BA_ "GenMsgSendType" BO_ 2532466687 8;
BA_ "GenMsgSendType" BO_ 2532401151 8;
BA_ "GenMsgSendType" BO_ 2515959807 8;
BA_ "GenMsgCycleTime" BO_ 2432692031 30;
BA_ "GenMsgSendType" BO_ 2671833698 8;
BA_ "GenMsgILSupport" BO_ 2671833698 0;
BA_ "DiagResponse" BO_ 2671833698 1;
BA_ "DiagConnection" BO_ 2671833698 62050;
BA_ "GenMsgSendType" BO_ 2671833697 8;
BA_ "GenMsgILSupport" BO_ 2671833697 0;
BA_ "DiagResponse" BO_ 2671833697 1;
BA_ "DiagConnection" BO_ 2671833697 62049;
BA_ "GenMsgSendType" BO_ 2671796978 8;
BA_ "GenMsgILSupport" BO_ 2671796978 0;
BA_ "DiagRequest" BO_ 2671796978 1;
BA_ "DiagConnection" BO_ 2671796978 62050;
BA_ "GenMsgSendType" BO_ 2671796722 8;
BA_ "GenMsgILSupport" BO_ 2671796722 0;
BA_ "DiagRequest" BO_ 2671796722 1;
BA_ "DiagConnection" BO_ 2671796722 62049;
BA_ "GenMsgSendType" BO_ 2633990242 8;
BA_ "NmAsrMessage" BO_ 2633990242 1;
BA_ "GenMsgILSupport" BO_ 2633990242 0;
BA_ "GenMsgSendType" BO_ 2633990241 8;
BA_ "NmAsrMessage" BO_ 2633990241 1;
BA_ "GenMsgILSupport" BO_ 2633990241 0;
BA_ "GenMsgSendType" BO_ 2633990240 8;
BA_ "NmAsrMessage" BO_ 2633990240 1;
BA_ "GenMsgILSupport" BO_ 2633990240 0;
BA_ "GenMsgSendType" BO_ 2671902708 8;
BA_ "GenMsgILSupport" BO_ 2671902708 0;
BA_ "DiagState" BO_ 2671902708 1;
BA_ "DiagConnection" BO_ 2671902708 62719;
BA_ "GenMsgSendType" BO_ 2549579775 8;
BA_ "GenMsgSendType" BO_ 2532409343 8;
BA_ "GenMsgSendType" BO_ 2532671487 8;
BA_ "GenMsgSendType" BO_ 2532605951 8;
BA_ "GenMsgSendType" BO_ 2532540415 8;
BA_ "GenMsgSendType" BO_ 2532474879 8;
BA_ "GenMsgSendType" BO_ 2516090879 8;
BA_ "GenMsgSendType" BO_ 2549907455 8;
BA_ "GenMsgSendType" BO_ 2533195775 8;
BA_ "GenMsgSendType" BO_ 2516221951 8;
BA_ "GenMsgSendType" BO_ 2549841919 8;
BA_ "GenMsgSendType" BO_ 2533130249 8;
BA_ "GenMsgSendType" BO_ 2533130247 8;
BA_ "GenMsgSendType" BO_ 2533130245 8;
BA_ "GenMsgSendType" BO_ 2533130243 8;
BA_ "GenMsgSendType" BO_ 2533130241 8;
BA_ "GenMsgSendType" BO_ 2533130239 8;
BA_ "GenMsgSendType" BO_ 2516156415 8;
BA_ "GenMsgDelayTime" BO_ 2432691983 30;
BA_ "GenMsgCycleTime" BO_ 2432691983 200;
BA_ "GenMsgCycleTime" BO_ 2432683823 35;
BA_ "GenMsgSendType" BO_ 2549252095 8;
BA_ "GenMsgSendType" BO_ 2532655103 8;
BA_ "GenMsgSendType" BO_ 2532589567 8;
BA_ "GenMsgSendType" BO_ 2532524031 8;
BA_ "GenMsgSendType" BO_ 2532458495 8;
BA_ "GenMsgSendType" BO_ 2532392959 8;
BA_ "GenMsgSendType" BO_ 2515808255 8;
BA_ "GenMsgSendType" BO_ 2549317631 8;
BA_ "GenMsgSendType" BO_ 2533105665 8;
BA_ "GenMsgSendType" BO_ 2515828735 8;
BA_ "GenMsgSendType" BO_ 2549186559 8;
BA_ "GenMsgSendType" BO_ 2532974598 8;
BA_ "GenMsgSendType" BO_ 2532974597 8;
BA_ "GenMsgSendType" BO_ 2532974596 8;
BA_ "GenMsgSendType" BO_ 2532974595 8;
BA_ "GenMsgSendType" BO_ 2532974594 8;
BA_ "GenMsgSendType" BO_ 2532974593 8;
BA_ "GenMsgSendType" BO_ 2515763199 8;
BA_ "GenMsgCycleTime" BO_ 2449452895 100;
BA_ "GenMsgStartDelayTime" BO_ 2432675807 30;
BA_ "GenMsgCycleTime" BO_ 2432675807 50;
BA_ "GenMsgDelayTime" BO_ 2449453039 50;
BA_ "GenMsgSendType" BO_ 2449453039 8;
BA_ "GenMsgStartDelayTime" BO_ 2432675791 10;
BA_ "GenMsgCycleTime" BO_ 2432675791 60;
BA_ "GenMsgStartDelayTime" BO_ 2432675759 45;
BA_ "GenMsgCycleTime" BO_ 2432675759 30;
BA_ "GenMsgStartDelayTime" BO_ 2449452927 20;
BA_ "GenMsgCycleTime" BO_ 2449452927 100;
BA_ "GenMsgStartDelayTime" BO_ 2449452879 35;
BA_ "GenMsgCycleTime" BO_ 2449452879 100;
BA_ "GenMsgStartDelayTime" BO_ 2432667503 25;
BA_ "GenMsgCycleTime" BO_ 2432667503 30;
BA_ "GenMsgStartDelayTime" BO_ 2432659343 15;
BA_ "GenMsgCycleTime" BO_ 2432659343 30;
BA_ "GenMsgStartDelayTime" BO_ 2432651183 5;
BA_ "GenMsgCycleTime" BO_ 2432651183 30;
BA_ "GenMsgDelayTime" BO_ 2432643023 30;
BA_ "GenMsgSendType" BO_ 2432643023 8;
BA_ "GenMsgCycleTime" BO_ 2432634863 10;
BA_ "GenMsgSendType" BO_ 2671964770 8;
BA_ "GenMsgILSupport" BO_ 2671964770 0;
BA_ "DiagUUDTResponse" BO_ 2671964770 1;
BA_ "DiagConnection" BO_ 2671964770 62050;
BA_ "GenMsgSendType" BO_ 2671964769 8;
BA_ "GenMsgILSupport" BO_ 2671964769 0;
BA_ "DiagUUDTResponse" BO_ 2671964769 1;
BA_ "DiagConnection" BO_ 2671964769 62049;
BA_ "GenMsgSendType" BO_ 2671834210 8;
BA_ "GenMsgILSupport" BO_ 2671834210 0;
BA_ "DiagResponse" BO_ 2671834210 1;
BA_ "DiagConnection" BO_ 2671834210 62562;
BA_ "GenMsgSendType" BO_ 2671834209 8;
BA_ "GenMsgILSupport" BO_ 2671834209 0;
BA_ "DiagResponse" BO_ 2671834209 1;
BA_ "DiagConnection" BO_ 2671834209 62561;
BA_ "GenMsgSendType" BO_ 2671833954 8;
BA_ "GenMsgILSupport" BO_ 2671833954 0;
BA_ "DiagResponse" BO_ 2671833954 1;
BA_ "DiagConnection" BO_ 2671833954 62306;
BA_ "GenMsgSendType" BO_ 2671833953 8;
BA_ "GenMsgILSupport" BO_ 2671833953 0;
BA_ "DiagResponse" BO_ 2671833953 1;
BA_ "DiagConnection" BO_ 2671833953 62305;
BA_ "GenMsgSendType" BO_ 2671796980 8;
BA_ "GenMsgILSupport" BO_ 2671796980 0;
BA_ "DiagRequest" BO_ 2671796980 1;
BA_ "DiagConnection" BO_ 2671796980 62562;
BA_ "GenMsgSendType" BO_ 2671796724 8;
BA_ "GenMsgILSupport" BO_ 2671796724 0;
BA_ "DiagRequest" BO_ 2671796724 1;
BA_ "DiagConnection" BO_ 2671796724 62561;
BA_ "GenMsgSendType" BO_ 2671796979 8;
BA_ "GenMsgILSupport" BO_ 2671796979 0;
BA_ "DiagRequest" BO_ 2671796979 1;
BA_ "DiagConnection" BO_ 2671796979 62306;
BA_ "GenMsgSendType" BO_ 2671796723 8;
BA_ "GenMsgILSupport" BO_ 2671796723 0;
BA_ "DiagRequest" BO_ 2671796723 1;
BA_ "DiagConnection" BO_ 2671796723 62305;
BA_ "GenMsgDelayTime" BO_ 2567045123 90;
BA_ "GenMsgCycleTime" BO_ 2567045123 1000;
BA_ "GenMsgDelayTime" BO_ 2567045121 90;
BA_ "GenMsgCycleTime" BO_ 2567045121 1000;
BA_ "GenMsgStartDelayTime" BO_ 2634020450 50;
BA_ "GenMsgDelayTime" BO_ 2634020450 50;
BA_ "GenMsgSendType" BO_ 2634020450 8;
BA_ "GenMsgStartDelayTime" BO_ 2634020449 50;
BA_ "GenMsgDelayTime" BO_ 2634020449 50;
BA_ "GenMsgSendType" BO_ 2634020449 8;
BA_ "GenMsgStartDelayTime" BO_ 2634020194 50;
BA_ "GenMsgDelayTime" BO_ 2634020194 50;
BA_ "GenMsgSendType" BO_ 2634020194 8;
BA_ "GenMsgStartDelayTime" BO_ 2634020193 50;
BA_ "GenMsgDelayTime" BO_ 2634020193 50;
BA_ "GenMsgSendType" BO_ 2634020193 8;
BA_ "GenMsgStartDelayTime" BO_ 2634019938 50;
BA_ "GenMsgDelayTime" BO_ 2634019938 50;
BA_ "GenMsgSendType" BO_ 2634019938 8;
BA_ "GenMsgStartDelayTime" BO_ 2634019937 50;
BA_ "GenMsgDelayTime" BO_ 2634019937 50;
BA_ "GenMsgSendType" BO_ 2634019937 8;
BA_ "GenMsgStartDelayTime" BO_ 2634019682 50;
BA_ "GenMsgDelayTime" BO_ 2634019682 50;
BA_ "GenMsgSendType" BO_ 2634019682 8;
BA_ "GenMsgStartDelayTime" BO_ 2634019681 50;
BA_ "GenMsgDelayTime" BO_ 2634019681 50;
BA_ "GenMsgSendType" BO_ 2634019681 8;
BA_ "GenMsgStartDelayTime" BO_ 2634019426 50;
BA_ "GenMsgDelayTime" BO_ 2634019426 50;
BA_ "GenMsgSendType" BO_ 2634019426 8;
BA_ "GenMsgStartDelayTime" BO_ 2634019425 50;
BA_ "GenMsgDelayTime" BO_ 2634019425 50;
BA_ "GenMsgSendType" BO_ 2634019425 8;
BA_ "GenMsgCycleTime" BO_ 2633994289 100;
BA_ "GenMsgCycleTime" BO_ 2633994288 100;
BA_ "GenMsgStartDelayTime" BO_ 2633994287 10;
BA_ "GenMsgCycleTime" BO_ 2633994287 100;
BA_ "GenMsgCycleTime" BO_ 2633994322 100;
BA_ "GenSigSendType" SG_ 2671902706 FuncDiagDataTester 7;
BA_ "SeToolVersion_SIGNAL" SG_ 2549448703 TIPSITP_SIDHeartbeat_Down_H "2";
BA_ "SeToolName_SIGNAL" SG_ 2549448703 TIPSITP_SIDHeartbeat_Down_H "TIPSITP_SIDHeartbeat_Down_H";
BA_ "SeToolItemID_SIGNAL" SG_ 2549448703 TIPSITP_SIDHeartbeat_Down_H "x0000001D04328124";
BA_ "SeToolAncestorID_SIGNAL" SG_ 2549448703 TIPSITP_SIDHeartbeat_Down_H "x0000001D042961CC";
BA_ "GenSigMaxLatency" SG_ 2549448703 TIPSITP_SIDHeartbeat_Down_H 501;
BA_ "GenSigCycleTimeActive" SG_ 2549448703 TIPSITP_SIDHeartbeat_Down_H 100;
BA_ "GenSigCycleTime" SG_ 2549448703 TIPSITP_SIDHeartbeat_Down_H 100;
BA_ "GenSigSendType" SG_ 2549448703 TIPSITP_SIDHeartbeat_Down_H 1;
BA_ "GenSigSendType" SG_ 2532663295 TIPSITP_SIDData_Down_H5 1;
BA_ "GenSigSendType" SG_ 2532597759 TIPSITP_SIDData_Down_H4 1;
BA_ "GenSigSendType" SG_ 2532532223 TIPSITP_SIDData_Down_H3 1;
BA_ "GenSigSendType" SG_ 2532466687 TIPSITP_SIDData_Down_H2 1;
BA_ "SeToolVersion_SIGNAL" SG_ 2532401151 TIPSITP_SIDData_Down_H1 "2";
BA_ "SeToolName_SIGNAL" SG_ 2532401151 TIPSITP_SIDData_Down_H1 "TIPSITP_SIDData_Down_H";
BA_ "SeToolItemID_SIGNAL" SG_ 2532401151 TIPSITP_SIDData_Down_H1 "x0000001D0432810F";
BA_ "SeToolAncestorID_SIGNAL" SG_ 2532401151 TIPSITP_SIDData_Down_H1 "x0000001D042961D4";
BA_ "GenSigMaxLatency" SG_ 2532401151 TIPSITP_SIDData_Down_H1 501;
BA_ "GenSigCycleTimeActive" SG_ 2532401151 TIPSITP_SIDData_Down_H1 100;
BA_ "GenSigCycleTime" SG_ 2532401151 TIPSITP_SIDData_Down_H1 100;
BA_ "GenSigSendType" SG_ 2532401151 TIPSITP_SIDData_Down_H1 1;
BA_ "SeToolVersion_SIGNAL" SG_ 2515959807 TIPSITP_SIDCtrl_Down_H "2";
BA_ "SeToolName_SIGNAL" SG_ 2515959807 TIPSITP_SIDCtrl_Down_H "TIPSITP_SIDCtrl_Down_H";
BA_ "SeToolItemID_SIGNAL" SG_ 2515959807 TIPSITP_SIDCtrl_Down_H "x0000001D04328106";
BA_ "SeToolAncestorID_SIGNAL" SG_ 2515959807 TIPSITP_SIDCtrl_Down_H "x0000001D042606FB";
BA_ "GenSigMaxLatency" SG_ 2515959807 TIPSITP_SIDCtrl_Down_H 501;
BA_ "GenSigCycleTimeActive" SG_ 2515959807 TIPSITP_SIDCtrl_Down_H 100;
BA_ "GenSigCycleTime" SG_ 2515959807 TIPSITP_SIDCtrl_Down_H 100;
BA_ "GenSigSendType" SG_ 2515959807 TIPSITP_SIDCtrl_Down_H 1;
BA_ "GenSigStartValue" SG_ 2432692031 SIDTouchScreenCoordinates_Y 511;
BA_ "GenSigCycleTimeActive" SG_ 2432692031 SIDTouchScreenCoordinates_Y 100;
BA_ "GenSigCycleTime" SG_ 2432692031 SIDTouchScreenCoordinates_Y 100;
BA_ "GenSigStartValue" SG_ 2432692031 SIDOnOff_ButtonStatus 3;
BA_ "GenSigCycleTimeActive" SG_ 2432692031 SIDOnOff_ButtonStatus 100;
BA_ "GenSigCycleTime" SG_ 2432692031 SIDOnOff_ButtonStatus 100;
BA_ "GenSigStartValue" SG_ 2432692031 SIDMute_ButtonStatus 3;
BA_ "GenSigCycleTimeActive" SG_ 2432692031 SIDMute_ButtonStatus 100;
BA_ "GenSigCycleTime" SG_ 2432692031 SIDMute_ButtonStatus 100;
BA_ "GenSigStartValue" SG_ 2432692031 SIDSourceSelect_ButtonStatus 3;
BA_ "GenSigCycleTimeActive" SG_ 2432692031 SIDSourceSelect_ButtonStatus 100;
BA_ "GenSigCycleTime" SG_ 2432692031 SIDSourceSelect_ButtonStatus 100;
BA_ "GenSigStartValue" SG_ 2432692031 SIDDayNight_ButtonStatus 3;
BA_ "GenSigCycleTimeActive" SG_ 2432692031 SIDDayNight_ButtonStatus 100;
BA_ "GenSigCycleTime" SG_ 2432692031 SIDDayNight_ButtonStatus 100;
BA_ "GenSigStartValue" SG_ 2432692031 SIDTouchScreenCoordinates_X 1023;
BA_ "GenSigCycleTimeActive" SG_ 2432692031 SIDTouchScreenCoordinates_X 100;
BA_ "GenSigCycleTime" SG_ 2432692031 SIDTouchScreenCoordinates_X 100;
BA_ "GenSigSendType" SG_ 2671833698 PhysDiagRespSig_F2_62 7;
BA_ "GenSigSendType" SG_ 2671833697 PhysDiagRespSig_F2_61 7;
BA_ "GenSigSendType" SG_ 2671796978 PhysDiagReqSig_62_F2 7;
BA_ "GenSigSendType" SG_ 2671796722 PhysDiagReqSig_61_F2 7;
BA_ "GenSigSendType" SG_ 2671902708 FuncDiagDataIntTesterTGW2 7;
BA_ "SeToolVersion_SIGNAL" SG_ 2549579775 TIPSITP_SIDHeartbeat_Down_L "2";
BA_ "SeToolName_SIGNAL" SG_ 2549579775 TIPSITP_SIDHeartbeat_Down_L "TIPSITP_SIDHeartbeat_Down_L";
BA_ "SeToolItemID_SIGNAL" SG_ 2549579775 TIPSITP_SIDHeartbeat_Down_L "x0000001D04328124";
BA_ "SeToolAncestorID_SIGNAL" SG_ 2549579775 TIPSITP_SIDHeartbeat_Down_L "x0000001D042961CC";
BA_ "GenSigMaxLatency" SG_ 2549579775 TIPSITP_SIDHeartbeat_Down_L 501;
BA_ "GenSigCycleTimeActive" SG_ 2549579775 TIPSITP_SIDHeartbeat_Down_L 100;
BA_ "GenSigCycleTime" SG_ 2549579775 TIPSITP_SIDHeartbeat_Down_L 100;
BA_ "GenSigSendType" SG_ 2549579775 TIPSITP_SIDHeartbeat_Down_L 1;
BA_ "SeToolVersion_SIGNAL" SG_ 2532409343 TIPSITP_SIDData_Down_L1 "2";
BA_ "SeToolName_SIGNAL" SG_ 2532409343 TIPSITP_SIDData_Down_L1 "TIPSITP_SIDData_Down_L";
BA_ "SeToolItemID_SIGNAL" SG_ 2532409343 TIPSITP_SIDData_Down_L1 "x0000001D0432810F";
BA_ "SeToolAncestorID_SIGNAL" SG_ 2532409343 TIPSITP_SIDData_Down_L1 "x0000001D042961D4";
BA_ "GenSigMaxLatency" SG_ 2532409343 TIPSITP_SIDData_Down_L1 501;
BA_ "GenSigCycleTimeActive" SG_ 2532409343 TIPSITP_SIDData_Down_L1 100;
BA_ "GenSigCycleTime" SG_ 2532409343 TIPSITP_SIDData_Down_L1 100;
BA_ "GenSigSendType" SG_ 2532409343 TIPSITP_SIDData_Down_L1 1;
BA_ "GenSigSendType" SG_ 2532671487 TIPSITP_SIDData_Down_L5 1;
BA_ "GenSigSendType" SG_ 2532605951 TIPSITP_SIDData_Down_L4 1;
BA_ "GenSigSendType" SG_ 2532540415 TIPSITP_SIDData_Down_L3 1;
BA_ "GenSigSendType" SG_ 2532474879 TIPSITP_SIDData_Down_L2 1;
BA_ "SeToolVersion_SIGNAL" SG_ 2516090879 TIPSITP_SIDCtrl_Down_L "2";
BA_ "SeToolName_SIGNAL" SG_ 2516090879 TIPSITP_SIDCtrl_Down_L "TIPSITP_SIDCtrl_Down_L";
BA_ "SeToolItemID_SIGNAL" SG_ 2516090879 TIPSITP_SIDCtrl_Down_L "x0000001D04328106";
BA_ "SeToolAncestorID_SIGNAL" SG_ 2516090879 TIPSITP_SIDCtrl_Down_L "x0000001D042606FB";
BA_ "GenSigMaxLatency" SG_ 2516090879 TIPSITP_SIDCtrl_Down_L 501;
BA_ "GenSigCycleTimeActive" SG_ 2516090879 TIPSITP_SIDCtrl_Down_L 100;
BA_ "GenSigCycleTime" SG_ 2516090879 TIPSITP_SIDCtrl_Down_L 100;
BA_ "GenSigSendType" SG_ 2516090879 TIPSITP_SIDCtrl_Down_L 1;
BA_ "GenSigCycleTimeActive" SG_ 2549907455 TIPSITP_FDCHeartbeat_Down 100;
BA_ "GenSigCycleTime" SG_ 2549907455 TIPSITP_FDCHeartbeat_Down 100;
BA_ "GenSigSendType" SG_ 2549907455 TIPSITP_FDCHeartbeat_Down 1;
BA_ "GenSigCycleTimeActive" SG_ 2533195775 TIPSITP_FDCData_Down 100;
BA_ "GenSigCycleTime" SG_ 2533195775 TIPSITP_FDCData_Down 100;
BA_ "GenSigSendType" SG_ 2533195775 TIPSITP_FDCData_Down 1;
BA_ "GenSigCycleTimeActive" SG_ 2516221951 TIPSITP_FDCCtrl_Down 100;
BA_ "GenSigCycleTime" SG_ 2516221951 TIPSITP_FDCCtrl_Down 100;
BA_ "GenSigSendType" SG_ 2516221951 TIPSITP_FDCCtrl_Down 1;
BA_ "SeToolVersion_SIGNAL" SG_ 2549841919 TIPSITP_DIDHeartbeat_Down "1";
BA_ "SeToolName_SIGNAL" SG_ 2549841919 TIPSITP_DIDHeartbeat_Down "TIPSITP_DIDHeartbeat_Down";
BA_ "SeToolItemID_SIGNAL" SG_ 2549841919 TIPSITP_DIDHeartbeat_Down "x0000001D04296439";
BA_ "SeToolAncestorID_SIGNAL" SG_ 2549841919 TIPSITP_DIDHeartbeat_Down "x0000001D04296439";
BA_ "GenSigMaxLatency" SG_ 2549841919 TIPSITP_DIDHeartbeat_Down 501;
BA_ "GenSigCycleTimeActive" SG_ 2549841919 TIPSITP_DIDHeartbeat_Down 100;
BA_ "GenSigCycleTime" SG_ 2549841919 TIPSITP_DIDHeartbeat_Down 100;
BA_ "GenSigSendType" SG_ 2549841919 TIPSITP_DIDHeartbeat_Down 1;
BA_ "GenSigSendType" SG_ 2533130249 TIPSITP_DIDData_Down6 1;
BA_ "GenSigCycleTimeActive" SG_ 2533130247 TIPSITP_DIDData_Down5 100;
BA_ "GenSigCycleTime" SG_ 2533130247 TIPSITP_DIDData_Down5 100;
BA_ "GenSigSendType" SG_ 2533130247 TIPSITP_DIDData_Down5 1;
BA_ "GenSigCycleTimeActive" SG_ 2533130245 TIPSITP_DIDData_Down4 100;
BA_ "GenSigCycleTime" SG_ 2533130245 TIPSITP_DIDData_Down4 100;
BA_ "GenSigSendType" SG_ 2533130245 TIPSITP_DIDData_Down4 1;
BA_ "GenSigCycleTimeActive" SG_ 2533130243 TIPSITP_DIDData_Down3 100;
BA_ "GenSigCycleTime" SG_ 2533130243 TIPSITP_DIDData_Down3 100;
BA_ "GenSigSendType" SG_ 2533130243 TIPSITP_DIDData_Down3 1;
BA_ "GenSigCycleTimeActive" SG_ 2533130241 TIPSITP_DIDData_Down2 100;
BA_ "GenSigCycleTime" SG_ 2533130241 TIPSITP_DIDData_Down2 100;
BA_ "GenSigSendType" SG_ 2533130241 TIPSITP_DIDData_Down2 1;
BA_ "GenSigCycleTimeActive" SG_ 2533130239 TIPSITP_DIDData_Down1 100;
BA_ "GenSigCycleTime" SG_ 2533130239 TIPSITP_DIDData_Down1 100;
BA_ "GenSigSendType" SG_ 2533130239 TIPSITP_DIDData_Down1 1;
BA_ "SeToolVersion_SIGNAL" SG_ 2516156415 TIPSITP_DIDCtrl_Down "1";
BA_ "SeToolName_SIGNAL" SG_ 2516156415 TIPSITP_DIDCtrl_Down "TIPSITP_DIDCtrl_Down";
BA_ "SeToolItemID_SIGNAL" SG_ 2516156415 TIPSITP_DIDCtrl_Down "x0000001D04296431";
BA_ "SeToolAncestorID_SIGNAL" SG_ 2516156415 TIPSITP_DIDCtrl_Down "x0000001D04296431";
BA_ "GenSigMaxLatency" SG_ 2516156415 TIPSITP_DIDCtrl_Down 501;
BA_ "GenSigCycleTimeActive" SG_ 2516156415 TIPSITP_DIDCtrl_Down 100;
BA_ "GenSigCycleTime" SG_ 2516156415 TIPSITP_DIDCtrl_Down 100;
BA_ "GenSigSendType" SG_ 2516156415 TIPSITP_DIDCtrl_Down 1;
BA_ "NeedsUpdateBit" SG_ 2432691983 ClusterSSStat_General 1;
BA_ "GenSigMaxLatency" SG_ 2432691983 ClusterSSStat_General 31;
BA_ "GenSigSendType" SG_ 2432691983 ClusterSSStat_General 1;
BA_ "NeedsUpdateBit" SG_ 2432691983 ClusterSSStat_Id 1;
BA_ "GenSigMaxLatency" SG_ 2432691983 ClusterSSStat_Id 31;
BA_ "GenSigSendType" SG_ 2432691983 ClusterSSStat_Id 1;
BA_ "NeedsUpdateBit" SG_ 2432691983 ClusterSSStat_PlayStat 1;
BA_ "GenSigMaxLatency" SG_ 2432691983 ClusterSSStat_PlayStat 31;
BA_ "GenSigSendType" SG_ 2432691983 ClusterSSStat_PlayStat 1;
BA_ "GenSigMaxLatency" SG_ 2432691983 ClusterSSStat_sg_UB 31;
BA_ "GenSigSendType" SG_ 2432691983 ClusterSSStat_sg_UB 7;
BA_ "GenSigStartValue" SG_ 2432683823 DirIndTelltale_stat 3;
BA_ "GenSigCycleTimeActive" SG_ 2432683823 DirIndTelltale_stat 100;
BA_ "GenSigCycleTime" SG_ 2432683823 DirIndTelltale_stat 100;
BA_ "SeToolVersion_SIGNAL" SG_ 2432683823 Tripmetershift_rqst "3";
BA_ "SeToolName_SIGNAL" SG_ 2432683823 Tripmetershift_rqst "Tripmetershift_rqst";
BA_ "SeToolItemID_SIGNAL" SG_ 2432683823 Tripmetershift_rqst "x0000001D0435825E";
BA_ "SeToolAncestorID_SIGNAL" SG_ 2432683823 Tripmetershift_rqst "x0000001D041E8DA0";
BA_ "GenSigMaxLatency" SG_ 2432683823 Tripmetershift_rqst 41;
BA_ "GenSigStartValue" SG_ 2432683823 Tripmetershift_rqst 3;
BA_ "GenSigCycleTimeActive" SG_ 2432683823 Tripmetershift_rqst 100;
BA_ "GenSigCycleTime" SG_ 2432683823 Tripmetershift_rqst 100;
BA_ "SeToolVersion_SIGNAL" SG_ 2432683823 CabLightIntensity_stat "2";
BA_ "SeToolName_SIGNAL" SG_ 2432683823 CabLightIntensity_stat "LightSensor_Data";
BA_ "SeToolItemID_SIGNAL" SG_ 2432683823 CabLightIntensity_stat "x0000001D0433F018";
BA_ "SeToolAncestorID_SIGNAL" SG_ 2432683823 CabLightIntensity_stat "x0000001D041AFE81";
BA_ "GenSigStartValue" SG_ 2432683823 CabLightIntensity_stat 255;
BA_ "GenSigCycleTimeActive" SG_ 2432683823 CabLightIntensity_stat 100;
BA_ "GenSigCycleTime" SG_ 2432683823 CabLightIntensity_stat 100;
BA_ "SeToolVersion_SIGNAL" SG_ 2432683823 TripmeterReset_rqst "3";
BA_ "SeToolName_SIGNAL" SG_ 2432683823 TripmeterReset_rqst "TripmeterReset_rqst";
BA_ "SeToolItemID_SIGNAL" SG_ 2432683823 TripmeterReset_rqst "x0000001D0435826E";
BA_ "SeToolAncestorID_SIGNAL" SG_ 2432683823 TripmeterReset_rqst "x0000001D04172B22";
BA_ "GenSigMaxLatency" SG_ 2432683823 TripmeterReset_rqst 41;
BA_ "GenSigStartValue" SG_ 2432683823 TripmeterReset_rqst 7;
BA_ "GenSigCycleTimeActive" SG_ 2432683823 TripmeterReset_rqst 100;
BA_ "GenSigCycleTime" SG_ 2432683823 TripmeterReset_rqst 100;
BA_ "SeToolVersion_SIGNAL" SG_ 2549252095 TIPSITP_SIDHeartbeat_Up "1";
BA_ "SeToolName_SIGNAL" SG_ 2549252095 TIPSITP_SIDHeartbeat_Up "TIPSITP_SIDHeartbeat_Up";
BA_ "SeToolItemID_SIGNAL" SG_ 2549252095 TIPSITP_SIDHeartbeat_Up "x0000001D042961D6";
BA_ "SeToolAncestorID_SIGNAL" SG_ 2549252095 TIPSITP_SIDHeartbeat_Up "x0000001D042961D6";
BA_ "GenSigMaxLatency" SG_ 2549252095 TIPSITP_SIDHeartbeat_Up 501;
BA_ "GenSigCycleTimeActive" SG_ 2549252095 TIPSITP_SIDHeartbeat_Up 100;
BA_ "GenSigCycleTime" SG_ 2549252095 TIPSITP_SIDHeartbeat_Up 100;
BA_ "GenSigSendType" SG_ 2549252095 TIPSITP_SIDHeartbeat_Up 1;
BA_ "GenSigSendType" SG_ 2532655103 TIPSITP_SIDData_Up5 1;
BA_ "GenSigSendType" SG_ 2532589567 TIPSITP_SIDData_Up4 1;
BA_ "GenSigSendType" SG_ 2532524031 TIPSITP_SIDData_Up3 1;
BA_ "GenSigSendType" SG_ 2532458495 TIPSITP_SIDData_Up2 1;
BA_ "SeToolVersion_SIGNAL" SG_ 2532392959 TIPSITP_SIDData_Up1 "1";
BA_ "SeToolName_SIGNAL" SG_ 2532392959 TIPSITP_SIDData_Up1 "TIPSITP_SIDData_Up";
BA_ "SeToolItemID_SIGNAL" SG_ 2532392959 TIPSITP_SIDData_Up1 "x0000001D042961CE";
BA_ "SeToolAncestorID_SIGNAL" SG_ 2532392959 TIPSITP_SIDData_Up1 "x0000001D042961CE";
BA_ "GenSigMaxLatency" SG_ 2532392959 TIPSITP_SIDData_Up1 501;
BA_ "GenSigCycleTimeActive" SG_ 2532392959 TIPSITP_SIDData_Up1 100;
BA_ "GenSigCycleTime" SG_ 2532392959 TIPSITP_SIDData_Up1 100;
BA_ "GenSigSendType" SG_ 2532392959 TIPSITP_SIDData_Up1 1;
BA_ "SeToolVersion_SIGNAL" SG_ 2515808255 TIPSITP_SIDCtrl_Up "1";
BA_ "SeToolName_SIGNAL" SG_ 2515808255 TIPSITP_SIDCtrl_Up "TIPSITP_SIDCtrl_Up";
BA_ "SeToolItemID_SIGNAL" SG_ 2515808255 TIPSITP_SIDCtrl_Up "x0000001D042606F8";
BA_ "SeToolAncestorID_SIGNAL" SG_ 2515808255 TIPSITP_SIDCtrl_Up "x0000001D042606F8";
BA_ "GenSigMaxLatency" SG_ 2515808255 TIPSITP_SIDCtrl_Up 501;
BA_ "GenSigCycleTimeActive" SG_ 2515808255 TIPSITP_SIDCtrl_Up 100;
BA_ "GenSigCycleTime" SG_ 2515808255 TIPSITP_SIDCtrl_Up 100;
BA_ "GenSigSendType" SG_ 2515808255 TIPSITP_SIDCtrl_Up 1;
BA_ "GenSigCycleTimeActive" SG_ 2549317631 TIPSITP_FDCHeartbeat_Up 100;
BA_ "GenSigCycleTime" SG_ 2549317631 TIPSITP_FDCHeartbeat_Up 100;
BA_ "GenSigSendType" SG_ 2549317631 TIPSITP_FDCHeartbeat_Up 1;
BA_ "GenSigCycleTimeActive" SG_ 2533105665 TIPSITP_FDCData_Up 100;
BA_ "GenSigCycleTime" SG_ 2533105665 TIPSITP_FDCData_Up 100;
BA_ "GenSigSendType" SG_ 2533105665 TIPSITP_FDCData_Up 1;
BA_ "GenSigCycleTimeActive" SG_ 2515828735 TIPSITP_FDCCtrl_Up 100;
BA_ "GenSigCycleTime" SG_ 2515828735 TIPSITP_FDCCtrl_Up 100;
BA_ "GenSigSendType" SG_ 2515828735 TIPSITP_FDCCtrl_Up 1;
BA_ "SeToolVersion_SIGNAL" SG_ 2549186559 TIPSITP_DIDHeartbeat_Up "1";
BA_ "SeToolName_SIGNAL" SG_ 2549186559 TIPSITP_DIDHeartbeat_Up "TIPSITP_DIDHeartbeat_Up";
BA_ "SeToolItemID_SIGNAL" SG_ 2549186559 TIPSITP_DIDHeartbeat_Up "x0000001D0429643B";
BA_ "SeToolAncestorID_SIGNAL" SG_ 2549186559 TIPSITP_DIDHeartbeat_Up "x0000001D0429643B";
BA_ "GenSigMaxLatency" SG_ 2549186559 TIPSITP_DIDHeartbeat_Up 501;
BA_ "GenSigCycleTimeActive" SG_ 2549186559 TIPSITP_DIDHeartbeat_Up 100;
BA_ "GenSigCycleTime" SG_ 2549186559 TIPSITP_DIDHeartbeat_Up 100;
BA_ "GenSigSendType" SG_ 2549186559 TIPSITP_DIDHeartbeat_Up 1;
BA_ "GenSigSendType" SG_ 2532974598 TIPSITP_DIDData_Up6 1;
BA_ "GenSigCycleTimeActive" SG_ 2532974597 TIPSITP_DIDData_Up5 100;
BA_ "GenSigCycleTime" SG_ 2532974597 TIPSITP_DIDData_Up5 100;
BA_ "GenSigSendType" SG_ 2532974597 TIPSITP_DIDData_Up5 1;
BA_ "GenSigCycleTimeActive" SG_ 2532974596 TIPSITP_DIDData_Up4 100;
BA_ "GenSigCycleTime" SG_ 2532974596 TIPSITP_DIDData_Up4 100;
BA_ "GenSigSendType" SG_ 2532974596 TIPSITP_DIDData_Up4 1;
BA_ "GenSigCycleTimeActive" SG_ 2532974595 TIPSITP_DIDData_Up3 100;
BA_ "GenSigCycleTime" SG_ 2532974595 TIPSITP_DIDData_Up3 100;
BA_ "GenSigSendType" SG_ 2532974595 TIPSITP_DIDData_Up3 1;
BA_ "GenSigCycleTimeActive" SG_ 2532974594 TIPSITP_DIDData_Up2 100;
BA_ "GenSigCycleTime" SG_ 2532974594 TIPSITP_DIDData_Up2 100;
BA_ "GenSigSendType" SG_ 2532974594 TIPSITP_DIDData_Up2 1;
BA_ "GenSigCycleTimeActive" SG_ 2532974593 TIPSITP_DIDData_Up1 100;
BA_ "GenSigCycleTime" SG_ 2532974593 TIPSITP_DIDData_Up1 100;
BA_ "GenSigSendType" SG_ 2532974593 TIPSITP_DIDData_Up1 1;
BA_ "SeToolVersion_SIGNAL" SG_ 2515763199 TIPSITP_DIDCtrl_Up "1";
BA_ "SeToolName_SIGNAL" SG_ 2515763199 TIPSITP_DIDCtrl_Up "TIPSITP_DIDCtrl_Up";
BA_ "SeToolItemID_SIGNAL" SG_ 2515763199 TIPSITP_DIDCtrl_Up "x0000001D04296433";
BA_ "SeToolAncestorID_SIGNAL" SG_ 2515763199 TIPSITP_DIDCtrl_Up "x0000001D04296433";
BA_ "GenSigMaxLatency" SG_ 2515763199 TIPSITP_DIDCtrl_Up 501;
BA_ "GenSigCycleTimeActive" SG_ 2515763199 TIPSITP_DIDCtrl_Up 100;
BA_ "GenSigCycleTime" SG_ 2515763199 TIPSITP_DIDCtrl_Up 100;
BA_ "GenSigSendType" SG_ 2515763199 TIPSITP_DIDCtrl_Up 1;
BA_ "GenSigCycleTimeActive" SG_ 2449452895 PresVal_DrivingMode 100;
BA_ "GenSigCycleTime" SG_ 2449452895 PresVal_DrivingMode 100;
BA_ "GenSigStartValue" SG_ 2432675807 DIDIlluminationLevel_cmd 255;
BA_ "GenSigCycleTimeActive" SG_ 2432675807 DIDIlluminationLevel_cmd 100;
BA_ "GenSigCycleTime" SG_ 2432675807 DIDIlluminationLevel_cmd 100;
BA_ "GenSigCycleTimeActive" SG_ 2432675807 LEDIntensity 100;
BA_ "GenSigCycleTime" SG_ 2432675807 LEDIntensity 100;
BA_ "GenSigCycleTimeActive" SG_ 2432675807 GaugeIllumLevelCmd 100;
BA_ "GenSigCycleTime" SG_ 2432675807 GaugeIllumLevelCmd 100;
BA_ "GenSigStartValue" SG_ 2432675807 ContrastLevelCmd 127;
BA_ "GenSigCycleTimeActive" SG_ 2432675807 ContrastLevelCmd 100;
BA_ "GenSigCycleTime" SG_ 2432675807 ContrastLevelCmd 100;
BA_ "GenSigStartValue" SG_ 2432675807 SelectedLanguage_stat 63;
BA_ "GenSigCycleTimeActive" SG_ 2432675807 SelectedLanguage_stat 100;
BA_ "GenSigCycleTime" SG_ 2432675807 SelectedLanguage_stat 100;
BA_ "GenSigCycleTimeActive" SG_ 2432675807 TelltaleIntensity 100;
BA_ "GenSigCycleTime" SG_ 2432675807 TelltaleIntensity 100;
BA_ "SeToolVersion_SIGNAL" SG_ 2432675807 BacklightCmd "2";
BA_ "SeToolName_SIGNAL" SG_ 2432675807 BacklightCmd "BacklightCmd";
BA_ "SeToolItemID_SIGNAL" SG_ 2432675807 BacklightCmd "x0000001D043A84D3";
BA_ "SeToolAncestorID_SIGNAL" SG_ 2432675807 BacklightCmd "x0000001D0439DDD1";
BA_ "GenSigCycleTimeActive" SG_ 2432675807 BacklightCmd 100;
BA_ "GenSigCycleTime" SG_ 2432675807 BacklightCmd 100;
BA_ "GenSigStartValue" SG_ 2432675807 SIDIlluminationLevel_cmd 255;
BA_ "GenSigCycleTimeActive" SG_ 2432675807 SIDIlluminationLevel_cmd 100;
BA_ "GenSigCycleTime" SG_ 2432675807 SIDIlluminationLevel_cmd 100;
BA_ "GenSigCycleTimeActive" SG_ 2432675807 ClusterDispIllumLvlCmd 100;
BA_ "GenSigCycleTime" SG_ 2432675807 ClusterDispIllumLvlCmd 100;
BA_ "GenSigStartValue" SG_ 2432675807 SIDOnOff 3;
BA_ "GenSigCycleTimeActive" SG_ 2432675807 SIDOnOff 100;
BA_ "GenSigCycleTime" SG_ 2432675807 SIDOnOff 100;
BA_ "NeedsUpdateBit" SG_ 2449453039 InstrTestSymbolsCmd 1;
BA_ "GenSigStartValue" SG_ 2449453039 InstrTestSymbolsCmd 3;
BA_ "GenSigCycleTimeActive" SG_ 2449453039 InstrTestSymbolsCmd 100;
BA_ "GenSigCycleTime" SG_ 2449453039 InstrTestSymbolsCmd 100;
BA_ "GenSigSendType" SG_ 2449453039 InstrTestSymbolsCmd 1;
BA_ "NeedsUpdateBit" SG_ 2449453039 InstrTestGaugesCmd 1;
BA_ "GenSigStartValue" SG_ 2449453039 InstrTestGaugesCmd 3;
BA_ "GenSigCycleTimeActive" SG_ 2449453039 InstrTestGaugesCmd 100;
BA_ "GenSigCycleTime" SG_ 2449453039 InstrTestGaugesCmd 100;
BA_ "GenSigSendType" SG_ 2449453039 InstrTestGaugesCmd 1;
BA_ "GenSigSendType" SG_ 2449453039 InstrTestDisplaysCmd_UB 7;
BA_ "NeedsUpdateBit" SG_ 2449453039 InstrTestDisplaysCmd 1;
BA_ "GenSigStartValue" SG_ 2449453039 InstrTestDisplaysCmd 3;
BA_ "GenSigCycleTimeActive" SG_ 2449453039 InstrTestDisplaysCmd 100;
BA_ "GenSigCycleTime" SG_ 2449453039 InstrTestDisplaysCmd 100;
BA_ "GenSigSendType" SG_ 2449453039 InstrTestDisplaysCmd 1;
BA_ "NeedsUpdateBit" SG_ 2449453039 InstrTestSpeakerVolCmd 1;
BA_ "GenSigCycleTimeActive" SG_ 2449453039 InstrTestSpeakerVolCmd 100;
BA_ "GenSigCycleTime" SG_ 2449453039 InstrTestSpeakerVolCmd 100;
BA_ "GenSigSendType" SG_ 2449453039 InstrTestSpeakerVolCmd 1;
BA_ "GenSigSendType" SG_ 2449453039 InstrTestSpeakerCmd_UB 7;
BA_ "GenSigSendType" SG_ 2449453039 InstrTestGaugesCmd_UB 7;
BA_ "GenSigSendType" SG_ 2449453039 InstrTestSpeakerVolCmd_UB 7;
BA_ "NeedsUpdateBit" SG_ 2449453039 InstrTestSpeakerCmd 1;
BA_ "GenSigStartValue" SG_ 2449453039 InstrTestSpeakerCmd 7;
BA_ "GenSigCycleTimeActive" SG_ 2449453039 InstrTestSpeakerCmd 100;
BA_ "GenSigCycleTime" SG_ 2449453039 InstrTestSpeakerCmd 100;
BA_ "GenSigSendType" SG_ 2449453039 InstrTestSpeakerCmd 1;
BA_ "GenSigSendType" SG_ 2449453039 InstrTestSymbolsCmd_UB 7;
BA_ "GenSigStartValue" SG_ 2432675791 EnginePreheatAlert_cmd 7;
BA_ "GenSigCycleTimeActive" SG_ 2432675791 EnginePreheatAlert_cmd 100;
BA_ "GenSigCycleTime" SG_ 2432675791 EnginePreheatAlert_cmd 100;
BA_ "GenSigStartValue" SG_ 2432675791 DifferentialLockWheelAlert_cmd 7;
BA_ "GenSigCycleTimeActive" SG_ 2432675791 DifferentialLockWheelAlert_cmd 100;
BA_ "GenSigCycleTime" SG_ 2432675791 DifferentialLockWheelAlert_cmd 100;
BA_ "SeToolVersion_SIGNAL" SG_ 2432675791 TotalVehicleDistanceHighRes "1";
BA_ "SeToolName_SIGNAL" SG_ 2432675791 TotalVehicleDistanceHighRes "HighResolutionTotalVehicleDistance";
BA_ "SeToolItemID_SIGNAL" SG_ 2432675791 TotalVehicleDistanceHighRes "x0000001D04109E2B";
BA_ "SeToolAncestorID_SIGNAL" SG_ 2432675791 TotalVehicleDistanceHighRes "x0000001D04109E2B";
BA_ "GenSigStartValue" SG_ 2432675791 TotalVehicleDistanceHighRes 4294967295;
BA_ "GenSigCycleTimeActive" SG_ 2432675791 TotalVehicleDistanceHighRes 100;
BA_ "GenSigCycleTime" SG_ 2432675791 TotalVehicleDistanceHighRes 100;
BA_ "GenSigCycleTimeActive" SG_ 2432675791 AutotestCmd 100;
BA_ "GenSigCycleTime" SG_ 2432675791 AutotestCmd 100;
BA_ "GenSigStartValue" SG_ 2432675791 SpeedometerPSDViewSpeedUnit 3;
BA_ "GenSigCycleTimeActive" SG_ 2432675791 SpeedometerPSDViewSpeedUnit 100;
BA_ "GenSigCycleTime" SG_ 2432675791 SpeedometerPSDViewSpeedUnit 100;
BA_ "GenSigStartValue" SG_ 2432675791 TripmeterResetCmd2 3;
BA_ "GenSigCycleTimeActive" SG_ 2432675791 TripmeterResetCmd2 100;
BA_ "GenSigCycleTime" SG_ 2432675791 TripmeterResetCmd2 100;
BA_ "GenSigStartValue" SG_ 2432675791 TripmeterResetCmd1 3;
BA_ "GenSigCycleTimeActive" SG_ 2432675791 TripmeterResetCmd1 100;
BA_ "GenSigCycleTime" SG_ 2432675791 TripmeterResetCmd1 100;
BA_ "GenSigStartValue" SG_ 2432675791 ASR_cmd 7;
BA_ "GenSigCycleTimeActive" SG_ 2432675791 ASR_cmd 100;
BA_ "GenSigCycleTime" SG_ 2432675791 ASR_cmd 100;
BA_ "GenSigStartValue" SG_ 2432675791 DiffLockInteraxleAlert_cmd 7;
BA_ "GenSigCycleTimeActive" SG_ 2432675791 DiffLockInteraxleAlert_cmd 100;
BA_ "GenSigCycleTime" SG_ 2432675791 DiffLockInteraxleAlert_cmd 100;
BA_ "GenSigStartValue" SG_ 2432675759 PresVal_ASLSpeedBlinkCmd 3;
BA_ "GenSigCycleTimeActive" SG_ 2432675759 PresVal_ASLSpeedBlinkCmd 100;
BA_ "GenSigCycleTime" SG_ 2432675759 PresVal_ASLSpeedBlinkCmd 100;
BA_ "GenSigStartValue" SG_ 2432675759 PresVal_ASLSetSpeed 255;
BA_ "GenSigCycleTimeActive" SG_ 2432675759 PresVal_ASLSetSpeed 100;
BA_ "GenSigCycleTime" SG_ 2432675759 PresVal_ASLSetSpeed 100;
BA_ "GenSigStartValue" SG_ 2432675759 PresVal_GearLeverModeBlink 3;
BA_ "GenSigCycleTimeActive" SG_ 2432675759 PresVal_GearLeverModeBlink 100;
BA_ "GenSigCycleTime" SG_ 2432675759 PresVal_GearLeverModeBlink 100;
BA_ "GenSigStartValue" SG_ 2432675759 PresValReqTimeGap 7;
BA_ "GenSigCycleTimeActive" SG_ 2432675759 PresValReqTimeGap 100;
BA_ "GenSigCycleTime" SG_ 2432675759 PresValReqTimeGap 100;
BA_ "GenSigStartValue" SG_ 2432675759 PresVal_CoolantTemp 255;
BA_ "GenSigCycleTimeActive" SG_ 2432675759 PresVal_CoolantTemp 100;
BA_ "GenSigCycleTime" SG_ 2432675759 PresVal_CoolantTemp 100;
BA_ "GenSigStartValue" SG_ 2432675759 PresVal_EngineCoolantTemp 255;
BA_ "GenSigCycleTimeActive" SG_ 2432675759 PresVal_EngineCoolantTemp 100;
BA_ "GenSigCycleTime" SG_ 2432675759 PresVal_EngineCoolantTemp 100;
BA_ "GenSigStartValue" SG_ 2432675759 PresVal_CCSetSpeed 255;
BA_ "GenSigCycleTimeActive" SG_ 2432675759 PresVal_CCSetSpeed 100;
BA_ "GenSigCycleTime" SG_ 2432675759 PresVal_CCSetSpeed 100;
BA_ "GenSigStartValue" SG_ 2432675759 PresVal_CCEnabledStatus 3;
BA_ "GenSigCycleTimeActive" SG_ 2432675759 PresVal_CCEnabledStatus 100;
BA_ "GenSigCycleTime" SG_ 2432675759 PresVal_CCEnabledStatus 100;
BA_ "GenSigStartValue" SG_ 2432675759 PresVal_ASLActiveStatus 3;
BA_ "GenSigCycleTimeActive" SG_ 2432675759 PresVal_ASLActiveStatus 100;
BA_ "GenSigCycleTime" SG_ 2432675759 PresVal_ASLActiveStatus 100;
BA_ "GenSigStartValue" SG_ 2432675759 PresVal_CCSpeedInactive 3;
BA_ "GenSigCycleTimeActive" SG_ 2432675759 PresVal_CCSpeedInactive 100;
BA_ "GenSigCycleTime" SG_ 2432675759 PresVal_CCSpeedInactive 100;
BA_ "GenSigStartValue" SG_ 2432675759 PresVal_CoolantTempHigh 3;
BA_ "GenSigCycleTimeActive" SG_ 2432675759 PresVal_CoolantTempHigh 100;
BA_ "GenSigCycleTime" SG_ 2432675759 PresVal_CoolantTempHigh 100;
BA_ "GenSigStartValue" SG_ 2432675759 PresVal_CCActiveStatus 3;
BA_ "GenSigCycleTimeActive" SG_ 2432675759 PresVal_CCActiveStatus 100;
BA_ "GenSigCycleTime" SG_ 2432675759 PresVal_CCActiveStatus 100;
BA_ "GenSigStartValue" SG_ 2432675759 PresVal_CCSpeedBlinkCmd 3;
BA_ "GenSigCycleTimeActive" SG_ 2432675759 PresVal_CCSpeedBlinkCmd 100;
BA_ "GenSigCycleTime" SG_ 2432675759 PresVal_CCSpeedBlinkCmd 100;
BA_ "GenSigCycleTimeActive" SG_ 2432675759 PresVal_GearLeverModeASCII 100;
BA_ "GenSigCycleTime" SG_ 2432675759 PresVal_GearLeverModeASCII 100;
BA_ "GenSigStartValue" SG_ 2432675759 PresVal_GearLeverModeFrame 3;
BA_ "GenSigCycleTimeActive" SG_ 2432675759 PresVal_GearLeverModeFrame 100;
BA_ "GenSigCycleTime" SG_ 2432675759 PresVal_GearLeverModeFrame 100;
BA_ "SeToolVersion_SIGNAL" SG_ 2449452927 HoursUTC "2";
BA_ "SeToolName_SIGNAL" SG_ 2449452927 HoursUTC "HoursUTC";
BA_ "SeToolItemID_SIGNAL" SG_ 2449452927 HoursUTC "x0000001D041EBD20";
BA_ "SeToolAncestorID_SIGNAL" SG_ 2449452927 HoursUTC "x0000001D0412FAC2";
BA_ "GenSigStartValue" SG_ 2449452927 HoursUTC 255;
BA_ "GenSigCycleTimeActive" SG_ 2449452927 HoursUTC 100;
BA_ "GenSigCycleTime" SG_ 2449452927 HoursUTC 100;
BA_ "SeToolVersion_SIGNAL" SG_ 2449452927 SecondsUTC "2";
BA_ "SeToolName_SIGNAL" SG_ 2449452927 SecondsUTC "SecondsUTC";
BA_ "SeToolItemID_SIGNAL" SG_ 2449452927 SecondsUTC "x0000001D041EBD32";
BA_ "SeToolAncestorID_SIGNAL" SG_ 2449452927 SecondsUTC "x0000001D0412FABE";
BA_ "GenSigStartValue" SG_ 2449452927 SecondsUTC 255;
BA_ "GenSigCycleTimeActive" SG_ 2449452927 SecondsUTC 100;
BA_ "GenSigCycleTime" SG_ 2449452927 SecondsUTC 100;
BA_ "SeToolVersion_SIGNAL" SG_ 2449452927 YearUTC "2";
BA_ "SeToolName_SIGNAL" SG_ 2449452927 YearUTC "YearUTC";
BA_ "SeToolItemID_SIGNAL" SG_ 2449452927 YearUTC "x0000001D041EBCEF";
BA_ "SeToolAncestorID_SIGNAL" SG_ 2449452927 YearUTC "x0000001D0412FACB";
BA_ "GenSigStartValue" SG_ 2449452927 YearUTC 255;
BA_ "GenSigCycleTimeActive" SG_ 2449452927 YearUTC 100;
BA_ "GenSigCycleTime" SG_ 2449452927 YearUTC 100;
BA_ "SeToolVersion_SIGNAL" SG_ 2449452927 MinutesUTC "2";
BA_ "SeToolName_SIGNAL" SG_ 2449452927 MinutesUTC "MinutesUTC";
BA_ "SeToolItemID_SIGNAL" SG_ 2449452927 MinutesUTC "x0000001D041EBD29";
BA_ "SeToolAncestorID_SIGNAL" SG_ 2449452927 MinutesUTC "x0000001D0412FAC0";
BA_ "GenSigStartValue" SG_ 2449452927 MinutesUTC 255;
BA_ "GenSigCycleTimeActive" SG_ 2449452927 MinutesUTC 100;
BA_ "GenSigCycleTime" SG_ 2449452927 MinutesUTC 100;
BA_ "SeToolVersion_SIGNAL" SG_ 2449452927 DayUTC "2";
BA_ "SeToolName_SIGNAL" SG_ 2449452927 DayUTC "DayUTC";
BA_ "SeToolItemID_SIGNAL" SG_ 2449452927 DayUTC "x0000001D041EBD81";
BA_ "SeToolAncestorID_SIGNAL" SG_ 2449452927 DayUTC "x0000001D0412FAC4";
BA_ "GenSigStartValue" SG_ 2449452927 DayUTC 255;
BA_ "GenSigCycleTimeActive" SG_ 2449452927 DayUTC 100;
BA_ "GenSigCycleTime" SG_ 2449452927 DayUTC 100;
BA_ "SeToolVersion_SIGNAL" SG_ 2449452927 AmbientAirTemperature "1";
BA_ "SeToolName_SIGNAL" SG_ 2449452927 AmbientAirTemperature "AmbientAirTemperature";
BA_ "SeToolItemID_SIGNAL" SG_ 2449452927 AmbientAirTemperature "x0000001D040FEBC8";
BA_ "SeToolAncestorID_SIGNAL" SG_ 2449452927 AmbientAirTemperature "x0000001D040FEBC8";
BA_ "GenSigStartValue" SG_ 2449452927 AmbientAirTemperature 65535;
BA_ "GenSigCycleTimeActive" SG_ 2449452927 AmbientAirTemperature 100;
BA_ "GenSigCycleTime" SG_ 2449452927 AmbientAirTemperature 100;
BA_ "SeToolVersion_SIGNAL" SG_ 2449452927 MonthUTC "2";
BA_ "SeToolName_SIGNAL" SG_ 2449452927 MonthUTC "MonthUTC";
BA_ "SeToolItemID_SIGNAL" SG_ 2449452927 MonthUTC "x0000001D041EBD16";
BA_ "SeToolAncestorID_SIGNAL" SG_ 2449452927 MonthUTC "x0000001D0412FAC9";
BA_ "GenSigStartValue" SG_ 2449452927 MonthUTC 255;
BA_ "GenSigCycleTimeActive" SG_ 2449452927 MonthUTC 100;
BA_ "GenSigCycleTime" SG_ 2449452927 MonthUTC 100;
BA_ "SeToolVersion_SIGNAL" SG_ 2449452879 PresVal_HighResTotalVehDist "2";
BA_ "SeToolName_SIGNAL" SG_ 2449452879 PresVal_HighResTotalVehDist "PresVal_HighResolutionTotalVehicleDistance";
BA_ "SeToolItemID_SIGNAL" SG_ 2449452879 PresVal_HighResTotalVehDist "x0000001D042983FF";
BA_ "SeToolAncestorID_SIGNAL" SG_ 2449452879 PresVal_HighResTotalVehDist "x0000001D041F9D1F";
BA_ "GenSigMaxLatency" SG_ 2449452879 PresVal_HighResTotalVehDist 41;
BA_ "GenSigStartValue" SG_ 2449452879 PresVal_HighResTotalVehDist 4294967295;
BA_ "GenSigCycleTimeActive" SG_ 2449452879 PresVal_HighResTotalVehDist 100;
BA_ "GenSigCycleTime" SG_ 2449452879 PresVal_HighResTotalVehDist 100;
BA_ "SeToolVersion_SIGNAL" SG_ 2449452879 PresVal_HighResolutionTripDist "1";
BA_ "SeToolName_SIGNAL" SG_ 2449452879 PresVal_HighResolutionTripDist "PresVal_HighResolutionTripDistance";
BA_ "SeToolItemID_SIGNAL" SG_ 2449452879 PresVal_HighResolutionTripDist "x0000001D042C8E0C";
BA_ "SeToolAncestorID_SIGNAL" SG_ 2449452879 PresVal_HighResolutionTripDist "x0000001D042C8E0C";
BA_ "GenSigMaxLatency" SG_ 2449452879 PresVal_HighResolutionTripDist 41;
BA_ "GenSigStartValue" SG_ 2449452879 PresVal_HighResolutionTripDist 4294967295;
BA_ "GenSigCycleTimeActive" SG_ 2449452879 PresVal_HighResolutionTripDist 100;
BA_ "GenSigCycleTime" SG_ 2449452879 PresVal_HighResolutionTripDist 100;
BA_ "SeToolVersion_SIGNAL" SG_ 2432667503 PresVal_TransmSelectedGear "2";
BA_ "SeToolName_SIGNAL" SG_ 2432667503 PresVal_TransmSelectedGear "PresVal_TransmissionSelectedGear";
BA_ "SeToolItemID_SIGNAL" SG_ 2432667503 PresVal_TransmSelectedGear "x0000001D0429523C";
BA_ "SeToolAncestorID_SIGNAL" SG_ 2432667503 PresVal_TransmSelectedGear "x0000001D041FA095";
BA_ "GenSigMaxLatency" SG_ 2432667503 PresVal_TransmSelectedGear 41;
BA_ "GenSigCycleTimeActive" SG_ 2432667503 PresVal_TransmSelectedGear 100;
BA_ "GenSigCycleTime" SG_ 2432667503 PresVal_TransmSelectedGear 100;
BA_ "SeToolVersion_SIGNAL" SG_ 2432667503 PresVal_VehicleSpeed "3";
BA_ "SeToolName_SIGNAL" SG_ 2432667503 PresVal_VehicleSpeed "PresVal_VehicleSpeed";
BA_ "SeToolItemID_SIGNAL" SG_ 2432667503 PresVal_VehicleSpeed "x0000001D0428F077";
BA_ "SeToolAncestorID_SIGNAL" SG_ 2432667503 PresVal_VehicleSpeed "x0000001D0419A44C";
BA_ "GenSigMaxLatency" SG_ 2432667503 PresVal_VehicleSpeed 41;
BA_ "GenSigStartValue" SG_ 2432667503 PresVal_VehicleSpeed 65535;
BA_ "GenSigCycleTimeActive" SG_ 2432667503 PresVal_VehicleSpeed 100;
BA_ "GenSigCycleTime" SG_ 2432667503 PresVal_VehicleSpeed 100;
BA_ "SeToolVersion_SIGNAL" SG_ 2432667503 PresVal_EngineSpeed "3";
BA_ "SeToolName_SIGNAL" SG_ 2432667503 PresVal_EngineSpeed "PresVal_EngineSpeed";
BA_ "SeToolItemID_SIGNAL" SG_ 2432667503 PresVal_EngineSpeed "x0000001D0428F074";
BA_ "SeToolAncestorID_SIGNAL" SG_ 2432667503 PresVal_EngineSpeed "x0000001D0419A3C4";
BA_ "GenSigMaxLatency" SG_ 2432667503 PresVal_EngineSpeed 41;
BA_ "GenSigStartValue" SG_ 2432667503 PresVal_EngineSpeed 65535;
BA_ "GenSigCycleTimeActive" SG_ 2432667503 PresVal_EngineSpeed 100;
BA_ "GenSigCycleTime" SG_ 2432667503 PresVal_EngineSpeed 100;
BA_ "GenSigStartValue" SG_ 2432667503 SpeedometerPSDViewCurrentSpeed 65535;
BA_ "GenSigCycleTimeActive" SG_ 2432667503 SpeedometerPSDViewCurrentSpeed 100;
BA_ "GenSigCycleTime" SG_ 2432667503 SpeedometerPSDViewCurrentSpeed 100;
BA_ "SeToolVersion_SIGNAL" SG_ 2432659343 PresVal_CatalystTankLevel "3";
BA_ "SeToolName_SIGNAL" SG_ 2432659343 PresVal_CatalystTankLevel "PresVal_CatalystTankLevel";
BA_ "SeToolItemID_SIGNAL" SG_ 2432659343 PresVal_CatalystTankLevel "x0000001D0429C4F9";
BA_ "SeToolAncestorID_SIGNAL" SG_ 2432659343 PresVal_CatalystTankLevel "x0000001D041F9D24";
BA_ "GenSigMaxLatency" SG_ 2432659343 PresVal_CatalystTankLevel 41;
BA_ "GenSigStartValue" SG_ 2432659343 PresVal_CatalystTankLevel 255;
BA_ "GenSigCycleTimeActive" SG_ 2432659343 PresVal_CatalystTankLevel 100;
BA_ "GenSigCycleTime" SG_ 2432659343 PresVal_CatalystTankLevel 100;
BA_ "SeToolVersion_SIGNAL" SG_ 2432659343 FormatedVehicleSpeed "5";
BA_ "SeToolName_SIGNAL" SG_ 2432659343 FormatedVehicleSpeed "FormatedVehicleSpeed";
BA_ "SeToolItemID_SIGNAL" SG_ 2432659343 FormatedVehicleSpeed "x0000001D0430212D";
BA_ "SeToolAncestorID_SIGNAL" SG_ 2432659343 FormatedVehicleSpeed "x0000001D04172345";
BA_ "GenSigMaxLatency" SG_ 2432659343 FormatedVehicleSpeed 41;
BA_ "GenSigStartValue" SG_ 2432659343 FormatedVehicleSpeed 255;
BA_ "GenSigCycleTimeActive" SG_ 2432659343 FormatedVehicleSpeed 100;
BA_ "GenSigCycleTime" SG_ 2432659343 FormatedVehicleSpeed 100;
BA_ "GenSigCycleTimeActive" SG_ 2432659343 PresVal_ClockHours 100;
BA_ "GenSigCycleTime" SG_ 2432659343 PresVal_ClockHours 100;
BA_ "GenSigStartValue" SG_ 2432659343 PresVal_ClockPeriod 7;
BA_ "GenSigCycleTimeActive" SG_ 2432659343 PresVal_ClockPeriod 100;
BA_ "GenSigCycleTime" SG_ 2432659343 PresVal_ClockPeriod 100;
BA_ "GenSigStartValue" SG_ 2432659343 PresVal_AvailGearsLowerRatio 15;
BA_ "GenSigCycleTimeActive" SG_ 2432659343 PresVal_AvailGearsLowerRatio 100;
BA_ "GenSigCycleTime" SG_ 2432659343 PresVal_AvailGearsLowerRatio 100;
BA_ "GenSigCycleTimeActive" SG_ 2432659343 PresVal_ClockMinutes 100;
BA_ "GenSigCycleTime" SG_ 2432659343 PresVal_ClockMinutes 100;
BA_ "SeToolVersion_SIGNAL" SG_ 2432659343 PresVal_AirPressure "1";
BA_ "SeToolName_SIGNAL" SG_ 2432659343 PresVal_AirPressure "PresVal_AirPressure";
BA_ "SeToolItemID_SIGNAL" SG_ 2432659343 PresVal_AirPressure "x0000001D04282742";
BA_ "SeToolAncestorID_SIGNAL" SG_ 2432659343 PresVal_AirPressure "x0000001D04282742";
BA_ "GenSigMaxLatency" SG_ 2432659343 PresVal_AirPressure 41;
BA_ "GenSigStartValue" SG_ 2432659343 PresVal_AirPressure 255;
BA_ "GenSigCycleTimeActive" SG_ 2432659343 PresVal_AirPressure 100;
BA_ "GenSigCycleTime" SG_ 2432659343 PresVal_AirPressure 100;
BA_ "SeToolVersion_SIGNAL" SG_ 2432659343 PresVal_AmbientAirTemperature "4";
BA_ "SeToolName_SIGNAL" SG_ 2432659343 PresVal_AmbientAirTemperature "PresVal_AmbientAirTemperature";
BA_ "SeToolItemID_SIGNAL" SG_ 2432659343 PresVal_AmbientAirTemperature "x0000001D043E931E";
BA_ "SeToolAncestorID_SIGNAL" SG_ 2432659343 PresVal_AmbientAirTemperature "x0000001D041F9D1D";
BA_ "GenSigMaxLatency" SG_ 2432659343 PresVal_AmbientAirTemperature 41;
BA_ "GenSigStartValue" SG_ 2432659343 PresVal_AmbientAirTemperature 511;
BA_ "GenSigCycleTimeActive" SG_ 2432659343 PresVal_AmbientAirTemperature 100;
BA_ "GenSigCycleTime" SG_ 2432659343 PresVal_AmbientAirTemperature 100;
BA_ "GenSigStartValue" SG_ 2432659343 PresVal_AvailGearsHigherRatio 15;
BA_ "GenSigCycleTimeActive" SG_ 2432659343 PresVal_AvailGearsHigherRatio 100;
BA_ "GenSigCycleTime" SG_ 2432659343 PresVal_AvailGearsHigherRatio 100;
BA_ "SeToolVersion_SIGNAL" SG_ 2432651183 PresVal_OdometerUnit "1";
BA_ "SeToolName_SIGNAL" SG_ 2432651183 PresVal_OdometerUnit "PresVal_OdometerUnit";
BA_ "SeToolItemID_SIGNAL" SG_ 2432651183 PresVal_OdometerUnit "x0000001D042C8DA1";
BA_ "SeToolAncestorID_SIGNAL" SG_ 2432651183 PresVal_OdometerUnit "x0000001D042C8DA1";
BA_ "GenSigMaxLatency" SG_ 2432651183 PresVal_OdometerUnit 41;
BA_ "GenSigStartValue" SG_ 2432651183 PresVal_OdometerUnit 3;
BA_ "GenSigCycleTimeActive" SG_ 2432651183 PresVal_OdometerUnit 100;
BA_ "GenSigCycleTime" SG_ 2432651183 PresVal_OdometerUnit 100;
BA_ "SeToolVersion_SIGNAL" SG_ 2432651183 ZoningBandsActiveBlueLEDRange2 "1";
BA_ "SeToolName_SIGNAL" SG_ 2432651183 ZoningBandsActiveBlueLEDRange2 "ZoningBandsActiveBlueLEDRange2";
BA_ "SeToolItemID_SIGNAL" SG_ 2432651183 ZoningBandsActiveBlueLEDRange2 "x0000001D042D14E3";
BA_ "SeToolAncestorID_SIGNAL" SG_ 2432651183 ZoningBandsActiveBlueLEDRange2 "x0000001D042D14E3";
BA_ "GenSigMaxLatency" SG_ 2432651183 ZoningBandsActiveBlueLEDRange2 41;
BA_ "GenSigStartValue" SG_ 2432651183 ZoningBandsActiveBlueLEDRange2 7;
BA_ "GenSigCycleTimeActive" SG_ 2432651183 ZoningBandsActiveBlueLEDRange2 100;
BA_ "GenSigCycleTime" SG_ 2432651183 ZoningBandsActiveBlueLEDRange2 100;
BA_ "SeToolVersion_SIGNAL" SG_ 2432651183 ZoningBandsActiveBlueLEDRange1 "1";
BA_ "SeToolName_SIGNAL" SG_ 2432651183 ZoningBandsActiveBlueLEDRange1 "ZoningBandsActiveBlueLEDRange1";
BA_ "SeToolItemID_SIGNAL" SG_ 2432651183 ZoningBandsActiveBlueLEDRange1 "x0000001D042D14E1";
BA_ "SeToolAncestorID_SIGNAL" SG_ 2432651183 ZoningBandsActiveBlueLEDRange1 "x0000001D042D14E1";
BA_ "GenSigMaxLatency" SG_ 2432651183 ZoningBandsActiveBlueLEDRange1 41;
BA_ "GenSigStartValue" SG_ 2432651183 ZoningBandsActiveBlueLEDRange1 7;
BA_ "SeToolVersion_SIGNAL" SG_ 2432651183 PresVal_LowFuelLevelWrn_stat "2";
BA_ "SeToolName_SIGNAL" SG_ 2432651183 PresVal_LowFuelLevelWrn_stat "PresVal_LowFuelLevelWarning_stat";
BA_ "SeToolItemID_SIGNAL" SG_ 2432651183 PresVal_LowFuelLevelWrn_stat "x0000001D04294629";
BA_ "SeToolAncestorID_SIGNAL" SG_ 2432651183 PresVal_LowFuelLevelWrn_stat "x0000001D041F9D26";
BA_ "GenSigMaxLatency" SG_ 2432651183 PresVal_LowFuelLevelWrn_stat 41;
BA_ "GenSigStartValue" SG_ 2432651183 PresVal_LowFuelLevelWrn_stat 3;
BA_ "GenSigCycleTimeActive" SG_ 2432651183 PresVal_LowFuelLevelWrn_stat 100;
BA_ "GenSigCycleTime" SG_ 2432651183 PresVal_LowFuelLevelWrn_stat 100;
BA_ "SeToolVersion_SIGNAL" SG_ 2432651183 LCDFormattedVehSpdBlink_cmd "6";
BA_ "SeToolName_SIGNAL" SG_ 2432651183 LCDFormattedVehSpdBlink_cmd "VehicleSpeedLCDFormatedVehicleSpeedBlinkCmd";
BA_ "SeToolItemID_SIGNAL" SG_ 2432651183 LCDFormattedVehSpdBlink_cmd "x0000001D042BE51E";
BA_ "SeToolAncestorID_SIGNAL" SG_ 2432651183 LCDFormattedVehSpdBlink_cmd "x0000001D0417234B";
BA_ "GenSigMaxLatency" SG_ 2432651183 LCDFormattedVehSpdBlink_cmd 41;
BA_ "GenSigStartValue" SG_ 2432651183 LCDFormattedVehSpdBlink_cmd 3;
BA_ "GenSigCycleTimeActive" SG_ 2432651183 LCDFormattedVehSpdBlink_cmd 100;
BA_ "GenSigCycleTime" SG_ 2432651183 LCDFormattedVehSpdBlink_cmd 100;
BA_ "GenSigStartValue" SG_ 2432651183 PresVal_ACCReducedMode 3;
BA_ "GenSigCycleTimeActive" SG_ 2432651183 PresVal_ACCReducedMode 100;
BA_ "GenSigCycleTime" SG_ 2432651183 PresVal_ACCReducedMode 100;
BA_ "SeToolVersion_SIGNAL" SG_ 2432651183 PresVal_FuelLevel "2";
BA_ "SeToolName_SIGNAL" SG_ 2432651183 PresVal_FuelLevel "PresVal_FuelLevel";
BA_ "SeToolItemID_SIGNAL" SG_ 2432651183 PresVal_FuelLevel "x0000001D0429463B";
BA_ "SeToolAncestorID_SIGNAL" SG_ 2432651183 PresVal_FuelLevel "x0000001D041F9D14";
BA_ "GenSigMaxLatency" SG_ 2432651183 PresVal_FuelLevel 41;
BA_ "GenSigStartValue" SG_ 2432651183 PresVal_FuelLevel 255;
BA_ "GenSigCycleTimeActive" SG_ 2432651183 PresVal_FuelLevel 100;
BA_ "GenSigCycleTime" SG_ 2432651183 PresVal_FuelLevel 100;
BA_ "SeToolVersion_SIGNAL" SG_ 2432651183 PresVal_AuxiliaryBrakesActivat "1";
BA_ "SeToolName_SIGNAL" SG_ 2432651183 PresVal_AuxiliaryBrakesActivat "PresVal_AuxiliaryBrakesActivat";
BA_ "SeToolItemID_SIGNAL" SG_ 2432651183 PresVal_AuxiliaryBrakesActivat "x0000001D042C94C6";
BA_ "SeToolAncestorID_SIGNAL" SG_ 2432651183 PresVal_AuxiliaryBrakesActivat "x0000001D042C94C6";
BA_ "GenSigMaxLatency" SG_ 2432651183 PresVal_AuxiliaryBrakesActivat 41;
BA_ "GenSigStartValue" SG_ 2432651183 PresVal_AuxiliaryBrakesActivat 3;
BA_ "GenSigCycleTimeActive" SG_ 2432651183 PresVal_AuxiliaryBrakesActivat 100;
BA_ "GenSigCycleTime" SG_ 2432651183 PresVal_AuxiliaryBrakesActivat 100;
BA_ "SeToolVersion_SIGNAL" SG_ 2432651183 PresVal_AmbientAirTempUnit "1";
BA_ "SeToolName_SIGNAL" SG_ 2432651183 PresVal_AmbientAirTempUnit "PresVal_AmbientAirTempUnit";
BA_ "SeToolItemID_SIGNAL" SG_ 2432651183 PresVal_AmbientAirTempUnit "x0000001D04295E84";
BA_ "SeToolAncestorID_SIGNAL" SG_ 2432651183 PresVal_AmbientAirTempUnit "x0000001D04295E84";
BA_ "GenSigMaxLatency" SG_ 2432651183 PresVal_AmbientAirTempUnit 41;
BA_ "GenSigStartValue" SG_ 2432651183 PresVal_AmbientAirTempUnit 3;
BA_ "GenSigCycleTimeActive" SG_ 2432651183 PresVal_AmbientAirTempUnit 100;
BA_ "GenSigCycleTime" SG_ 2432651183 PresVal_AmbientAirTempUnit 100;
BA_ "SeToolVersion_SIGNAL" SG_ 2432651183 PresVal_TargetDetected "1";
BA_ "SeToolName_SIGNAL" SG_ 2432651183 PresVal_TargetDetected "PresVal_TargetDetected";
BA_ "SeToolItemID_SIGNAL" SG_ 2432651183 PresVal_TargetDetected "x0000001D043684D7";
BA_ "SeToolAncestorID_SIGNAL" SG_ 2432651183 PresVal_TargetDetected "x0000001D043684D7";
BA_ "GenSigMaxLatency" SG_ 2432651183 PresVal_TargetDetected 41;
BA_ "GenSigStartValue" SG_ 2432651183 PresVal_TargetDetected 3;
BA_ "GenSigCycleTimeActive" SG_ 2432651183 PresVal_TargetDetected 100;
BA_ "GenSigCycleTime" SG_ 2432651183 PresVal_TargetDetected 100;
BA_ "SeToolVersion_SIGNAL" SG_ 2432651183 SeatBeltReminderAlert_cmd "4";
BA_ "SeToolName_SIGNAL" SG_ 2432651183 SeatBeltReminderAlert_cmd "SeatBeltReminderAlert_cmd";
BA_ "SeToolItemID_SIGNAL" SG_ 2432651183 SeatBeltReminderAlert_cmd "x0000001D04295469";
BA_ "SeToolAncestorID_SIGNAL" SG_ 2432651183 SeatBeltReminderAlert_cmd "x0000001D04182F7F";
BA_ "GenSigMaxLatency" SG_ 2432651183 SeatBeltReminderAlert_cmd 41;
BA_ "GenSigStartValue" SG_ 2432651183 SeatBeltReminderAlert_cmd 7;
BA_ "GenSigCycleTimeActive" SG_ 2432651183 SeatBeltReminderAlert_cmd 100;
BA_ "GenSigCycleTime" SG_ 2432651183 SeatBeltReminderAlert_cmd 100;
BA_ "GenSigStartValue" SG_ 2432651183 PresVal_CrossCountryStatus 3;
BA_ "GenSigCycleTimeActive" SG_ 2432651183 PresVal_CrossCountryStatus 100;
BA_ "GenSigCycleTime" SG_ 2432651183 PresVal_CrossCountryStatus 100;
BA_ "SeToolVersion_SIGNAL" SG_ 2432651183 PresVal_TripmeterChoice "1";
BA_ "SeToolName_SIGNAL" SG_ 2432651183 PresVal_TripmeterChoice "PresVal_TripmeterChoice";
BA_ "SeToolItemID_SIGNAL" SG_ 2432651183 PresVal_TripmeterChoice "x0000001D042C8E5C";
BA_ "SeToolAncestorID_SIGNAL" SG_ 2432651183 PresVal_TripmeterChoice "x0000001D042C8E5C";
BA_ "GenSigMaxLatency" SG_ 2432651183 PresVal_TripmeterChoice 41;
BA_ "GenSigStartValue" SG_ 2432651183 PresVal_TripmeterChoice 3;
BA_ "GenSigCycleTimeActive" SG_ 2432651183 PresVal_TripmeterChoice 100;
BA_ "GenSigCycleTime" SG_ 2432651183 PresVal_TripmeterChoice 100;
BA_ "SeToolVersion_SIGNAL" SG_ 2432651183 ZoningBandsActiveGreenLEDRng2 "1";
BA_ "SeToolName_SIGNAL" SG_ 2432651183 ZoningBandsActiveGreenLEDRng2 "ZoningBandsActiveGreenLEDRange2";
BA_ "SeToolItemID_SIGNAL" SG_ 2432651183 ZoningBandsActiveGreenLEDRng2 "x0000001D042D14DF";
BA_ "SeToolAncestorID_SIGNAL" SG_ 2432651183 ZoningBandsActiveGreenLEDRng2 "x0000001D042D14DF";
BA_ "GenSigMaxLatency" SG_ 2432651183 ZoningBandsActiveGreenLEDRng2 41;
BA_ "GenSigStartValue" SG_ 2432651183 ZoningBandsActiveGreenLEDRng2 7;
BA_ "GenSigCycleTimeActive" SG_ 2432651183 ZoningBandsActiveGreenLEDRng2 100;
BA_ "GenSigCycleTime" SG_ 2432651183 ZoningBandsActiveGreenLEDRng2 100;
BA_ "GenSigStartValue" SG_ 2432651183 SIDPresentationMode 15;
BA_ "GenSigCycleTimeActive" SG_ 2432651183 SIDPresentationMode 100;
BA_ "GenSigCycleTime" SG_ 2432651183 SIDPresentationMode 100;
BA_ "SeToolVersion_SIGNAL" SG_ 2432651183 VehicleSpeedLCDSpeedUnitCmd "3";
BA_ "SeToolName_SIGNAL" SG_ 2432651183 VehicleSpeedLCDSpeedUnitCmd "VehicleSpeedLCDSpeedUnitCmd";
BA_ "SeToolItemID_SIGNAL" SG_ 2432651183 VehicleSpeedLCDSpeedUnitCmd "x0000001D0428EADE";
BA_ "SeToolAncestorID_SIGNAL" SG_ 2432651183 VehicleSpeedLCDSpeedUnitCmd "x0000001D0422D67A";
BA_ "GenSigMaxLatency" SG_ 2432651183 VehicleSpeedLCDSpeedUnitCmd 41;
BA_ "GenSigStartValue" SG_ 2432651183 VehicleSpeedLCDSpeedUnitCmd 3;
BA_ "GenSigCycleTimeActive" SG_ 2432651183 VehicleSpeedLCDSpeedUnitCmd 100;
BA_ "GenSigCycleTime" SG_ 2432651183 VehicleSpeedLCDSpeedUnitCmd 100;
BA_ "SeToolVersion_SIGNAL" SG_ 2432651183 PresVal_CatalystTankLevelLow "3";
BA_ "SeToolName_SIGNAL" SG_ 2432651183 PresVal_CatalystTankLevelLow "PresVal_CatalystTankLevelLow";
BA_ "SeToolItemID_SIGNAL" SG_ 2432651183 PresVal_CatalystTankLevelLow "x0000001D0434206C";
BA_ "SeToolAncestorID_SIGNAL" SG_ 2432651183 PresVal_CatalystTankLevelLow "x0000001D041F9D1B";
BA_ "GenSigMaxLatency" SG_ 2432651183 PresVal_CatalystTankLevelLow 41;
BA_ "GenSigStartValue" SG_ 2432651183 PresVal_CatalystTankLevelLow 3;
BA_ "GenSigCycleTimeActive" SG_ 2432651183 PresVal_CatalystTankLevelLow 100;
BA_ "GenSigCycleTime" SG_ 2432651183 PresVal_CatalystTankLevelLow 100;
BA_ "SeToolVersion_SIGNAL" SG_ 2432651183 PresVal_ACCStatus "1";
BA_ "SeToolName_SIGNAL" SG_ 2432651183 PresVal_ACCStatus "PresVal_ACCStatus";
BA_ "SeToolItemID_SIGNAL" SG_ 2432651183 PresVal_ACCStatus "x0000001D043684E0";
BA_ "SeToolAncestorID_SIGNAL" SG_ 2432651183 PresVal_ACCStatus "x0000001D043684E0";
BA_ "GenSigMaxLatency" SG_ 2432651183 PresVal_ACCStatus 41;
BA_ "GenSigStartValue" SG_ 2432651183 PresVal_ACCStatus 3;
BA_ "GenSigCycleTimeActive" SG_ 2432651183 PresVal_ACCStatus 100;
BA_ "GenSigCycleTime" SG_ 2432651183 PresVal_ACCStatus 100;
BA_ "SeToolVersion_SIGNAL" SG_ 2432651183 PresVal_AuxiliaryBrakesPos "1";
BA_ "SeToolName_SIGNAL" SG_ 2432651183 PresVal_AuxiliaryBrakesPos "PresVal_AuxiliaryBrakesPosition";
BA_ "SeToolItemID_SIGNAL" SG_ 2432651183 PresVal_AuxiliaryBrakesPos "x0000001D042C94D0";
BA_ "SeToolAncestorID_SIGNAL" SG_ 2432651183 PresVal_AuxiliaryBrakesPos "x0000001D042C94D0";
BA_ "GenSigMaxLatency" SG_ 2432651183 PresVal_AuxiliaryBrakesPos 41;
BA_ "GenSigStartValue" SG_ 2432651183 PresVal_AuxiliaryBrakesPos 7;
BA_ "GenSigCycleTimeActive" SG_ 2432651183 PresVal_AuxiliaryBrakesPos 100;
BA_ "GenSigCycleTime" SG_ 2432651183 PresVal_AuxiliaryBrakesPos 100;
BA_ "GenSigStartValue" SG_ 2432651183 PresVal_EngSpdCtrlStatus 3;
BA_ "GenSigCycleTimeActive" SG_ 2432651183 PresVal_EngSpdCtrlStatus 100;
BA_ "GenSigCycleTime" SG_ 2432651183 PresVal_EngSpdCtrlStatus 100;
BA_ "SeToolVersion_SIGNAL" SG_ 2432651183 ZoningBandsActiveRedLEDRange1 "1";
BA_ "SeToolName_SIGNAL" SG_ 2432651183 ZoningBandsActiveRedLEDRange1 "ZoningBandsActiveRedLEDRange1";
BA_ "SeToolItemID_SIGNAL" SG_ 2432651183 ZoningBandsActiveRedLEDRange1 "x0000001D042D14E5";
BA_ "SeToolAncestorID_SIGNAL" SG_ 2432651183 ZoningBandsActiveRedLEDRange1 "x0000001D042D14E5";
BA_ "GenSigMaxLatency" SG_ 2432651183 ZoningBandsActiveRedLEDRange1 41;
BA_ "GenSigStartValue" SG_ 2432651183 ZoningBandsActiveRedLEDRange1 7;
BA_ "GenSigCycleTimeActive" SG_ 2432651183 ZoningBandsActiveRedLEDRange1 100;
BA_ "GenSigCycleTime" SG_ 2432651183 ZoningBandsActiveRedLEDRange1 100;
BA_ "SeToolVersion_SIGNAL" SG_ 2432651183 PresVal_LowAmbientTempWarning "3";
BA_ "SeToolName_SIGNAL" SG_ 2432651183 PresVal_LowAmbientTempWarning "PresVal_LowAmbientTemperatureWarning";
BA_ "SeToolItemID_SIGNAL" SG_ 2432651183 PresVal_LowAmbientTempWarning "x0000001D04311061";
BA_ "SeToolAncestorID_SIGNAL" SG_ 2432651183 PresVal_LowAmbientTempWarning "x0000001D0421E72F";
BA_ "GenSigMaxLatency" SG_ 2432651183 PresVal_LowAmbientTempWarning 41;
BA_ "GenSigStartValue" SG_ 2432651183 PresVal_LowAmbientTempWarning 3;
BA_ "GenSigCycleTimeActive" SG_ 2432651183 PresVal_LowAmbientTempWarning 100;
BA_ "GenSigCycleTime" SG_ 2432651183 PresVal_LowAmbientTempWarning 100;
BA_ "SeToolVersion_SIGNAL" SG_ 2432651183 ZoningBandsActiveGreenLEDRng1 "1";
BA_ "SeToolName_SIGNAL" SG_ 2432651183 ZoningBandsActiveGreenLEDRng1 "ZoningBandsActiveGreenLEDRange1";
BA_ "SeToolItemID_SIGNAL" SG_ 2432651183 ZoningBandsActiveGreenLEDRng1 "x0000001D042CFA7C";
BA_ "SeToolAncestorID_SIGNAL" SG_ 2432651183 ZoningBandsActiveGreenLEDRng1 "x0000001D042CFA7C";
BA_ "GenSigMaxLatency" SG_ 2432651183 ZoningBandsActiveGreenLEDRng1 41;
BA_ "GenSigStartValue" SG_ 2432651183 ZoningBandsActiveGreenLEDRng1 7;
BA_ "GenSigCycleTimeActive" SG_ 2432651183 ZoningBandsActiveGreenLEDRng1 100;
BA_ "GenSigCycleTime" SG_ 2432651183 ZoningBandsActiveGreenLEDRng1 100;
BA_ "NeedsUpdateBit" SG_ 2432643023 ClusterSSReq_Volume 1;
BA_ "GenSigMaxLatency" SG_ 2432643023 ClusterSSReq_Volume 31;
BA_ "GenSigSendType" SG_ 2432643023 ClusterSSReq_Volume 1;
BA_ "GenSigSendType" SG_ 2432643023 ClusterSSReq_sg_UB 7;
BA_ "NeedsUpdateBit" SG_ 2432643023 ClusterSSReq_Repetition 1;
BA_ "GenSigMaxLatency" SG_ 2432643023 ClusterSSReq_Repetition 31;
BA_ "GenSigSendType" SG_ 2432643023 ClusterSSReq_Repetition 1;
BA_ "NeedsUpdateBit" SG_ 2432643023 ClusterSSReq_Balance 1;
BA_ "GenSigMaxLatency" SG_ 2432643023 ClusterSSReq_Balance 31;
BA_ "GenSigSendType" SG_ 2432643023 ClusterSSReq_Balance 1;
BA_ "NeedsUpdateBit" SG_ 2432643023 ClusterSSReq_Id 1;
BA_ "GenSigMaxLatency" SG_ 2432643023 ClusterSSReq_Id 31;
BA_ "GenSigSendType" SG_ 2432643023 ClusterSSReq_Id 1;
BA_ "NeedsUpdateBit" SG_ 2432643023 ClusterSSReq_State 1;
BA_ "GenSigMaxLatency" SG_ 2432643023 ClusterSSReq_State 31;
BA_ "GenSigSendType" SG_ 2432643023 ClusterSSReq_State 1;
BA_ "NeedsUpdateBit" SG_ 2432643023 ClusterSSReq_Mixed 1;
BA_ "GenSigMaxLatency" SG_ 2432643023 ClusterSSReq_Mixed 31;
BA_ "GenSigSendType" SG_ 2432643023 ClusterSSReq_Mixed 1;
BA_ "NeedsUpdateBit" SG_ 2432643023 ClusterSSReq_Time 1;
BA_ "GenSigMaxLatency" SG_ 2432643023 ClusterSSReq_Time 31;
BA_ "GenSigSendType" SG_ 2432643023 ClusterSSReq_Time 1;
BA_ "SeToolVersion_SIGNAL" SG_ 2432634863 DippedBeamAlert_cmd "4";
BA_ "SeToolName_SIGNAL" SG_ 2432634863 DippedBeamAlert_cmd "HeadLightDippedBeamAlert_cmd";
BA_ "SeToolItemID_SIGNAL" SG_ 2432634863 DippedBeamAlert_cmd "x0000001D04295469";
BA_ "SeToolAncestorID_SIGNAL" SG_ 2432634863 DippedBeamAlert_cmd "x0000001D04182F7F";
BA_ "GenSigMaxLatency" SG_ 2432634863 DippedBeamAlert_cmd 26;
BA_ "GenSigStartValue" SG_ 2432634863 DippedBeamAlert_cmd 7;
BA_ "GenSigCycleTimeActive" SG_ 2432634863 DippedBeamAlert_cmd 100;
BA_ "GenSigCycleTime" SG_ 2432634863 DippedBeamAlert_cmd 100;
BA_ "NeedsUpdateBit" SG_ 2432634863 VehicleMode 1;
BA_ "GenSigStartValue" SG_ 2432634863 VehicleMode 15;
BA_ "GenSigCycleTimeActive" SG_ 2432634863 VehicleMode 100;
BA_ "GenSigCycleTime" SG_ 2432634863 VehicleMode 100;
BA_ "SeToolVersion_SIGNAL" SG_ 2432634863 LiftAxle1Alert_cmd "4";
BA_ "SeToolName_SIGNAL" SG_ 2432634863 LiftAxle1Alert_cmd "LiftAxle1Alert_cmd";
BA_ "SeToolItemID_SIGNAL" SG_ 2432634863 LiftAxle1Alert_cmd "x0000001D04295469";
BA_ "SeToolAncestorID_SIGNAL" SG_ 2432634863 LiftAxle1Alert_cmd "x0000001D04182F7F";
BA_ "GenSigMaxLatency" SG_ 2432634863 LiftAxle1Alert_cmd 26;
BA_ "GenSigStartValue" SG_ 2432634863 LiftAxle1Alert_cmd 7;
BA_ "GenSigCycleTimeActive" SG_ 2432634863 LiftAxle1Alert_cmd 100;
BA_ "GenSigCycleTime" SG_ 2432634863 LiftAxle1Alert_cmd 100;
BA_ "SeToolVersion_SIGNAL" SG_ 2432634863 DirIndicatorRtTrailerAlert_cmd "4";
BA_ "SeToolName_SIGNAL" SG_ 2432634863 DirIndicatorRtTrailerAlert_cmd "DirectionIndicatorRightTrailorAlert_cmd";
BA_ "SeToolItemID_SIGNAL" SG_ 2432634863 DirIndicatorRtTrailerAlert_cmd "x0000001D04295469";
BA_ "SeToolAncestorID_SIGNAL" SG_ 2432634863 DirIndicatorRtTrailerAlert_cmd "x0000001D04182F7F";
BA_ "GenSigMaxLatency" SG_ 2432634863 DirIndicatorRtTrailerAlert_cmd 26;
BA_ "GenSigStartValue" SG_ 2432634863 DirIndicatorRtTrailerAlert_cmd 7;
BA_ "GenSigCycleTimeActive" SG_ 2432634863 DirIndicatorRtTrailerAlert_cmd 100;
BA_ "GenSigCycleTime" SG_ 2432634863 DirIndicatorRtTrailerAlert_cmd 100;
BA_ "SeToolVersion_SIGNAL" SG_ 2432634863 FogLightFrontAlert_cmd "4";
BA_ "SeToolName_SIGNAL" SG_ 2432634863 FogLightFrontAlert_cmd "FogLightFrontAlert_cmd";
BA_ "SeToolItemID_SIGNAL" SG_ 2432634863 FogLightFrontAlert_cmd "x0000001D04295469";
BA_ "SeToolAncestorID_SIGNAL" SG_ 2432634863 FogLightFrontAlert_cmd "x0000001D04182F7F";
BA_ "GenSigMaxLatency" SG_ 2432634863 FogLightFrontAlert_cmd 26;
BA_ "GenSigStartValue" SG_ 2432634863 FogLightFrontAlert_cmd 7;
BA_ "GenSigCycleTimeActive" SG_ 2432634863 FogLightFrontAlert_cmd 100;
BA_ "GenSigCycleTime" SG_ 2432634863 FogLightFrontAlert_cmd 100;
BA_ "SeToolVersion_SIGNAL" SG_ 2432634863 LiftAxle2Alert_cmd "4";
BA_ "SeToolName_SIGNAL" SG_ 2432634863 LiftAxle2Alert_cmd "LiftAxle2Alert_cmd";
BA_ "SeToolItemID_SIGNAL" SG_ 2432634863 LiftAxle2Alert_cmd "x0000001D04295469";
BA_ "SeToolAncestorID_SIGNAL" SG_ 2432634863 LiftAxle2Alert_cmd "x0000001D04182F7F";
BA_ "GenSigMaxLatency" SG_ 2432634863 LiftAxle2Alert_cmd 26;
BA_ "GenSigStartValue" SG_ 2432634863 LiftAxle2Alert_cmd 7;
BA_ "GenSigCycleTimeActive" SG_ 2432634863 LiftAxle2Alert_cmd 100;
BA_ "GenSigCycleTime" SG_ 2432634863 LiftAxle2Alert_cmd 100;
BA_ "SeToolVersion_SIGNAL" SG_ 2432634863 ExtraSpotLampsAlert_cmd "4";
BA_ "SeToolName_SIGNAL" SG_ 2432634863 ExtraSpotLampsAlert_cmd "HeadLightExtraSpotLampsAlert_cmd";
BA_ "SeToolItemID_SIGNAL" SG_ 2432634863 ExtraSpotLampsAlert_cmd "x0000001D04295469";
BA_ "SeToolAncestorID_SIGNAL" SG_ 2432634863 ExtraSpotLampsAlert_cmd "x0000001D04182F7F";
BA_ "GenSigMaxLatency" SG_ 2432634863 ExtraSpotLampsAlert_cmd 26;
BA_ "GenSigStartValue" SG_ 2432634863 ExtraSpotLampsAlert_cmd 7;
BA_ "GenSigCycleTimeActive" SG_ 2432634863 ExtraSpotLampsAlert_cmd 100;
BA_ "GenSigCycleTime" SG_ 2432634863 ExtraSpotLampsAlert_cmd 100;
BA_ "SeToolVersion_SIGNAL" SG_ 2432634863 AdBlueLevelLowAlert_cmd "4";
BA_ "SeToolName_SIGNAL" SG_ 2432634863 AdBlueLevelLowAlert_cmd "AdBlueLevelLowAlert_cmd";
BA_ "SeToolItemID_SIGNAL" SG_ 2432634863 AdBlueLevelLowAlert_cmd "x0000001D04295469";
BA_ "SeToolAncestorID_SIGNAL" SG_ 2432634863 AdBlueLevelLowAlert_cmd "x0000001D04182F7F";
BA_ "GenSigMaxLatency" SG_ 2432634863 AdBlueLevelLowAlert_cmd 26;
BA_ "GenSigStartValue" SG_ 2432634863 AdBlueLevelLowAlert_cmd 7;
BA_ "GenSigCycleTimeActive" SG_ 2432634863 AdBlueLevelLowAlert_cmd 100;
BA_ "GenSigCycleTime" SG_ 2432634863 AdBlueLevelLowAlert_cmd 100;
BA_ "SeToolVersion_SIGNAL" SG_ 2432634863 DirIndicatorLtTrailerAlert_cmd "4";
BA_ "SeToolName_SIGNAL" SG_ 2432634863 DirIndicatorLtTrailerAlert_cmd "DirectionIndicatorLeftTrailorAlert_cmd";
BA_ "SeToolItemID_SIGNAL" SG_ 2432634863 DirIndicatorLtTrailerAlert_cmd "x0000001D04295469";
BA_ "SeToolAncestorID_SIGNAL" SG_ 2432634863 DirIndicatorLtTrailerAlert_cmd "x0000001D04182F7F";
BA_ "GenSigMaxLatency" SG_ 2432634863 DirIndicatorLtTrailerAlert_cmd 26;
BA_ "GenSigStartValue" SG_ 2432634863 DirIndicatorLtTrailerAlert_cmd 7;
BA_ "GenSigCycleTimeActive" SG_ 2432634863 DirIndicatorLtTrailerAlert_cmd 100;
BA_ "GenSigCycleTime" SG_ 2432634863 DirIndicatorLtTrailerAlert_cmd 100;
BA_ "SeToolVersion_SIGNAL" SG_ 2432634863 EngineMalFunctionAlert_cmd "4";
BA_ "SeToolName_SIGNAL" SG_ 2432634863 EngineMalFunctionAlert_cmd "EngineMalFunctionAlert_cmd";
BA_ "SeToolItemID_SIGNAL" SG_ 2432634863 EngineMalFunctionAlert_cmd "x0000001D04295469";
BA_ "SeToolAncestorID_SIGNAL" SG_ 2432634863 EngineMalFunctionAlert_cmd "x0000001D04182F7F";
BA_ "GenSigMaxLatency" SG_ 2432634863 EngineMalFunctionAlert_cmd 26;
BA_ "GenSigStartValue" SG_ 2432634863 EngineMalFunctionAlert_cmd 7;
BA_ "GenSigCycleTimeActive" SG_ 2432634863 EngineMalFunctionAlert_cmd 100;
BA_ "GenSigCycleTime" SG_ 2432634863 EngineMalFunctionAlert_cmd 100;
BA_ "SeToolVersion_SIGNAL" SG_ 2432634863 FuelLevelLowAlert_cmd "4";
BA_ "SeToolName_SIGNAL" SG_ 2432634863 FuelLevelLowAlert_cmd "FuelLevelLowAlert_cmd";
BA_ "SeToolItemID_SIGNAL" SG_ 2432634863 FuelLevelLowAlert_cmd "x0000001D04295469";
BA_ "SeToolAncestorID_SIGNAL" SG_ 2432634863 FuelLevelLowAlert_cmd "x0000001D04182F7F";
BA_ "GenSigMaxLatency" SG_ 2432634863 FuelLevelLowAlert_cmd 26;
BA_ "GenSigStartValue" SG_ 2432634863 FuelLevelLowAlert_cmd 7;
BA_ "GenSigCycleTimeActive" SG_ 2432634863 FuelLevelLowAlert_cmd 100;
BA_ "GenSigCycleTime" SG_ 2432634863 FuelLevelLowAlert_cmd 100;
BA_ "SeToolVersion_SIGNAL" SG_ 2432634863 PosLightAlert_cmd "4";
BA_ "SeToolName_SIGNAL" SG_ 2432634863 PosLightAlert_cmd "PosLightAlert_cmd";
BA_ "SeToolItemID_SIGNAL" SG_ 2432634863 PosLightAlert_cmd "x0000001D04295469";
BA_ "SeToolAncestorID_SIGNAL" SG_ 2432634863 PosLightAlert_cmd "x0000001D04182F7F";
BA_ "GenSigMaxLatency" SG_ 2432634863 PosLightAlert_cmd 26;
BA_ "GenSigStartValue" SG_ 2432634863 PosLightAlert_cmd 7;
BA_ "GenSigCycleTimeActive" SG_ 2432634863 PosLightAlert_cmd 100;
BA_ "GenSigCycleTime" SG_ 2432634863 PosLightAlert_cmd 100;
BA_ "SeToolVersion_SIGNAL" SG_ 2432634863 MainBeamAlert_cmd "4";
BA_ "SeToolName_SIGNAL" SG_ 2432634863 MainBeamAlert_cmd "HeadLightMainBeamAlert_cmd";
BA_ "SeToolItemID_SIGNAL" SG_ 2432634863 MainBeamAlert_cmd "x0000001D04295469";
BA_ "SeToolAncestorID_SIGNAL" SG_ 2432634863 MainBeamAlert_cmd "x0000001D04182F7F";
BA_ "GenSigMaxLatency" SG_ 2432634863 MainBeamAlert_cmd 26;
BA_ "GenSigStartValue" SG_ 2432634863 MainBeamAlert_cmd 7;
BA_ "GenSigCycleTimeActive" SG_ 2432634863 MainBeamAlert_cmd 100;
BA_ "GenSigCycleTime" SG_ 2432634863 MainBeamAlert_cmd 100;
BA_ "SeToolVersion_SIGNAL" SG_ 2432634863 DirIndicatorRightAlert_cmd "4";
BA_ "SeToolName_SIGNAL" SG_ 2432634863 DirIndicatorRightAlert_cmd "DirectionIndicatorRightAlert_cmd";
BA_ "SeToolItemID_SIGNAL" SG_ 2432634863 DirIndicatorRightAlert_cmd "x0000001D04295469";
BA_ "SeToolAncestorID_SIGNAL" SG_ 2432634863 DirIndicatorRightAlert_cmd "x0000001D04182F7F";
BA_ "GenSigMaxLatency" SG_ 2432634863 DirIndicatorRightAlert_cmd 26;
BA_ "GenSigStartValue" SG_ 2432634863 DirIndicatorRightAlert_cmd 7;
BA_ "GenSigCycleTimeActive" SG_ 2432634863 DirIndicatorRightAlert_cmd 100;
BA_ "GenSigCycleTime" SG_ 2432634863 DirIndicatorRightAlert_cmd 100;
BA_ "SeToolVersion_SIGNAL" SG_ 2432634863 ParkBrakeAlert_cmd "4";
BA_ "SeToolName_SIGNAL" SG_ 2432634863 ParkBrakeAlert_cmd "ParkBrakeAlert_cmd";
BA_ "SeToolItemID_SIGNAL" SG_ 2432634863 ParkBrakeAlert_cmd "x0000001D04295469";
BA_ "SeToolAncestorID_SIGNAL" SG_ 2432634863 ParkBrakeAlert_cmd "x0000001D04182F7F";
BA_ "GenSigMaxLatency" SG_ 2432634863 ParkBrakeAlert_cmd 26;
BA_ "GenSigStartValue" SG_ 2432634863 ParkBrakeAlert_cmd 7;
BA_ "GenSigCycleTimeActive" SG_ 2432634863 ParkBrakeAlert_cmd 100;
BA_ "GenSigCycleTime" SG_ 2432634863 ParkBrakeAlert_cmd 100;
BA_ "SeToolVersion_SIGNAL" SG_ 2432634863 FogLightRearAlert_cmd "4";
BA_ "SeToolName_SIGNAL" SG_ 2432634863 FogLightRearAlert_cmd "FogLightRearAlert_cmd";
BA_ "SeToolItemID_SIGNAL" SG_ 2432634863 FogLightRearAlert_cmd "x0000001D04295469";
BA_ "SeToolAncestorID_SIGNAL" SG_ 2432634863 FogLightRearAlert_cmd "x0000001D04182F7F";
BA_ "GenSigMaxLatency" SG_ 2432634863 FogLightRearAlert_cmd 26;
BA_ "GenSigStartValue" SG_ 2432634863 FogLightRearAlert_cmd 7;
BA_ "GenSigCycleTimeActive" SG_ 2432634863 FogLightRearAlert_cmd 100;
BA_ "GenSigCycleTime" SG_ 2432634863 FogLightRearAlert_cmd 100;
BA_ "SeToolVersion_SIGNAL" SG_ 2432634863 DirIndicatorLeftAlert_cmd "4";
BA_ "SeToolName_SIGNAL" SG_ 2432634863 DirIndicatorLeftAlert_cmd "DirectionIndicatorLeftAlert_cmd";
BA_ "SeToolItemID_SIGNAL" SG_ 2432634863 DirIndicatorLeftAlert_cmd "x0000001D04295469";
BA_ "SeToolAncestorID_SIGNAL" SG_ 2432634863 DirIndicatorLeftAlert_cmd "x0000001D04182F7F";
BA_ "GenSigMaxLatency" SG_ 2432634863 DirIndicatorLeftAlert_cmd 26;
BA_ "GenSigStartValue" SG_ 2432634863 DirIndicatorLeftAlert_cmd 7;
BA_ "GenSigCycleTimeActive" SG_ 2432634863 DirIndicatorLeftAlert_cmd 100;
BA_ "GenSigCycleTime" SG_ 2432634863 DirIndicatorLeftAlert_cmd 100;
BA_ "SeToolVersion_SIGNAL" SG_ 2432634863 CheckAlert_cmd "4";
BA_ "SeToolName_SIGNAL" SG_ 2432634863 CheckAlert_cmd "CheckAlert_cmd";
BA_ "SeToolItemID_SIGNAL" SG_ 2432634863 CheckAlert_cmd "x0000001D04295469";
BA_ "SeToolAncestorID_SIGNAL" SG_ 2432634863 CheckAlert_cmd "x0000001D04182F7F";
BA_ "GenSigMaxLatency" SG_ 2432634863 CheckAlert_cmd 26;
BA_ "GenSigStartValue" SG_ 2432634863 CheckAlert_cmd 7;
BA_ "GenSigCycleTimeActive" SG_ 2432634863 CheckAlert_cmd 100;
BA_ "GenSigCycleTime" SG_ 2432634863 CheckAlert_cmd 100;
BA_ "SeToolVersion_SIGNAL" SG_ 2432634863 StopAlert_cmd "4";
BA_ "SeToolName_SIGNAL" SG_ 2432634863 StopAlert_cmd "StopAlert_cmd";
BA_ "SeToolItemID_SIGNAL" SG_ 2432634863 StopAlert_cmd "x0000001D04295469";
BA_ "SeToolAncestorID_SIGNAL" SG_ 2432634863 StopAlert_cmd "x0000001D04182F7F";
BA_ "GenSigMaxLatency" SG_ 2432634863 StopAlert_cmd 26;
BA_ "GenSigStartValue" SG_ 2432634863 StopAlert_cmd 7;
BA_ "GenSigCycleTimeActive" SG_ 2432634863 StopAlert_cmd 100;
BA_ "GenSigCycleTime" SG_ 2432634863 StopAlert_cmd 100;
BA_ "GenSigSendType" SG_ 2432634863 VehicleMode_UB 7;
BA_ "GenSigSendType" SG_ 2671964770 DiagUUDTRespSig_F2_62 7;
BA_ "GenSigSendType" SG_ 2671964769 DiagUUDTRespSig_F2_61 7;
BA_ "GenSigSendType" SG_ 2671834210 InternalTesterDiagSig_F4_62 7;
BA_ "GenSigSendType" SG_ 2671834209 InternalTesterDiagSig_F4_61 7;
BA_ "GenSigSendType" SG_ 2671833954 InternalTesterDiagSig_F3_62 7;
BA_ "GenSigSendType" SG_ 2671833953 InternalTesterDiagSig_F3_61 7;
BA_ "GenSigSendType" SG_ 2671796980 InternalTesterDiagSig_62_F4 7;
BA_ "GenSigSendType" SG_ 2671796724 InternalTesterDiagSig_61_F4 7;
BA_ "GenSigSendType" SG_ 2671796979 InternalTesterDiagSig_62_F3 7;
BA_ "GenSigSendType" SG_ 2671796723 InternalTesterDiagSig_61_F3 7;
BA_ "NeedsUpdateBit" SG_ 2567045123 DiagFaultStat_SIDH_DtcIdB 1;
BA_ "GenSigSendType" SG_ 2567045123 DiagFaultStat_SIDH_DtcIdB 3;
BA_ "NeedsUpdateBit" SG_ 2567045123 DiagFaultStat_SIDH_FailTB 1;
BA_ "GenSigSendType" SG_ 2567045123 DiagFaultStat_SIDH_FailTB 3;
BA_ "NeedsUpdateBit" SG_ 2567045123 DiagFaultStat_SIDH_DtcIdA 1;
BA_ "GenSigSendType" SG_ 2567045123 DiagFaultStat_SIDH_DtcIdA 3;
BA_ "NeedsUpdateBit" SG_ 2567045123 DiagFaultStat_SIDH_FailTA 1;
BA_ "GenSigSendType" SG_ 2567045123 DiagFaultStat_SIDH_FailTA 3;
BA_ "NeedsUpdateBit" SG_ 2567045123 DiagFaultStat_SIDH_EcuAdr 1;
BA_ "GenSigStartValue" SG_ 2567045123 DiagFaultStat_SIDH_EcuAdr 255;
BA_ "GenSigSendType" SG_ 2567045123 DiagFaultStat_SIDH_EcuAdr 3;
BA_ "GenSigSendType" SG_ 2567045123 DiagFaultStat_SIDH_sg_UB 7;
BA_ "NeedsUpdateBit" SG_ 2567045121 DiagFaultStat_IC_DtcIdA 1;
BA_ "GenSigSendType" SG_ 2567045121 DiagFaultStat_IC_DtcIdA 3;
BA_ "GenSigSendType" SG_ 2567045121 DiagFaultStat_IC_sg_UB 7;
BA_ "NeedsUpdateBit" SG_ 2567045121 DiagFaultStat_IC_FailTA 1;
BA_ "GenSigSendType" SG_ 2567045121 DiagFaultStat_IC_FailTA 3;
BA_ "NeedsUpdateBit" SG_ 2567045121 DiagFaultStat_IC_EcuAdr 1;
BA_ "GenSigStartValue" SG_ 2567045121 DiagFaultStat_IC_EcuAdr 255;
BA_ "GenSigSendType" SG_ 2567045121 DiagFaultStat_IC_EcuAdr 3;
BA_ "NeedsUpdateBit" SG_ 2567045121 DiagFaultStat_IC_FailTB 1;
BA_ "GenSigSendType" SG_ 2567045121 DiagFaultStat_IC_FailTB 3;
BA_ "NeedsUpdateBit" SG_ 2567045121 DiagFaultStat_IC_DtcIdB 1;
BA_ "GenSigSendType" SG_ 2567045121 DiagFaultStat_IC_DtcIdB 3;
BA_ "GenSigMaxLatency" SG_ 2634020450 Debug_6_SID 59;
BA_ "GenSigSendType" SG_ 2634020450 Debug_6_SID 1;
BA_ "GenSigMaxLatency" SG_ 2634020449 Debug_6_IC 59;
BA_ "GenSigSendType" SG_ 2634020449 Debug_6_IC 1;
BA_ "GenSigMaxLatency" SG_ 2634020194 Debug_5_SID 59;
BA_ "GenSigSendType" SG_ 2634020194 Debug_5_SID 1;
BA_ "GenSigMaxLatency" SG_ 2634020193 Debug_5_IC 59;
BA_ "GenSigSendType" SG_ 2634020193 Debug_5_IC 1;
BA_ "GenSigMaxLatency" SG_ 2634019938 Debug_4_SID 59;
BA_ "GenSigSendType" SG_ 2634019938 Debug_4_SID 1;
BA_ "GenSigMaxLatency" SG_ 2634019937 Debug_4_IC 59;
BA_ "GenSigSendType" SG_ 2634019937 Debug_4_IC 1;
BA_ "GenSigMaxLatency" SG_ 2634019682 Debug_3_SID 59;
BA_ "GenSigSendType" SG_ 2634019682 Debug_3_SID 1;
BA_ "GenSigMaxLatency" SG_ 2634019681 Debug_3_IC 59;
BA_ "GenSigSendType" SG_ 2634019681 Debug_3_IC 1;
BA_ "GenSigMaxLatency" SG_ 2634019426 Debug_2_SID 59;
BA_ "GenSigSendType" SG_ 2634019426 Debug_2_SID 1;
BA_ "GenSigMaxLatency" SG_ 2634019425 Debug_2_IC 59;
BA_ "GenSigSendType" SG_ 2634019425 Debug_2_IC 1;
BA_ "GenSigSendType" SG_ 2634019170 Debug_1_SID 1;
BA_ "GenSigSendType" SG_ 2634019169 Debug_1_IC 1;
BA_ "MmAnSignal" SG_ 2633994289 AnmSig_SIDHigh_DisplaySubnet 1;
BA_ "GenSigCycleTimeActive" SG_ 2633994289 AnmSig_SIDHigh_DisplaySubnet 100;
BA_ "GenSigCycleTime" SG_ 2633994289 AnmSig_SIDHigh_DisplaySubnet 100;
BA_ "GenSigSendType" SG_ 2633994289 AnmSig_SIDHigh_DisplaySubnet 1;
BA_ "MmAnSignal" SG_ 2633994288 AnmSig_IC_DisplaySubnet 1;
BA_ "GenSigCycleTimeActive" SG_ 2633994288 AnmSig_IC_DisplaySubnet 100;
BA_ "GenSigCycleTime" SG_ 2633994288 AnmSig_IC_DisplaySubnet 100;
BA_ "GenSigSendType" SG_ 2633994288 AnmSig_IC_DisplaySubnet 1;
BA_ "MmAnSignal" SG_ 2633994287 AnmSig_HMIIOM_DisplaySubnet 1;
BA_ "GenSigCycleTimeActive" SG_ 2633994287 AnmSig_HMIIOM_DisplaySubnet 100;
BA_ "GenSigCycleTime" SG_ 2633994287 AnmSig_HMIIOM_DisplaySubnet 100;
BA_ "GenSigSendType" SG_ 2633994287 AnmSig_HMIIOM_DisplaySubnet 1;
BA_ "MmAnSignal" SG_ 2633994322 AnmSig_ECUspare8_DisplaySubnet 1;
BA_ "GenSigCycleTimeActive" SG_ 2633994322 AnmSig_ECUspare8_DisplaySubnet 100;
BA_ "GenSigCycleTime" SG_ 2633994322 AnmSig_ECUspare8_DisplaySubnet 100;
BA_ "GenSigSendType" SG_ 2633994322 AnmSig_ECUspare8_DisplaySubnet 1;
BA_REL_ "GenSigTimeoutTime" BU_SG_REL_ HMIIOM SG_ 2432692031 SIDTouchScreenCoordinates_Y 180;
BA_REL_ "GenSigFirstTimeoutTime" BU_SG_REL_ HMIIOM SG_ 2432692031 SIDTouchScreenCoordinates_Y 3000;
BA_REL_ "GenSigTimeoutTime" BU_SG_REL_ HMIIOM SG_ 2432692031 SIDOnOff_ButtonStatus 180;
BA_REL_ "GenSigFirstTimeoutTime" BU_SG_REL_ HMIIOM SG_ 2432692031 SIDOnOff_ButtonStatus 3000;
BA_REL_ "GenSigTimeoutTime" BU_SG_REL_ HMIIOM SG_ 2432692031 SIDMute_ButtonStatus 180;
BA_REL_ "GenSigFirstTimeoutTime" BU_SG_REL_ HMIIOM SG_ 2432692031 SIDMute_ButtonStatus 3000;
BA_REL_ "GenSigTimeoutTime" BU_SG_REL_ HMIIOM SG_ 2432692031 SIDSourceSelect_ButtonStatus 180;
BA_REL_ "GenSigFirstTimeoutTime" BU_SG_REL_ HMIIOM SG_ 2432692031 SIDSourceSelect_ButtonStatus 3000;
BA_REL_ "GenSigTimeoutTime" BU_SG_REL_ HMIIOM SG_ 2432692031 SIDDayNight_ButtonStatus 180;
BA_REL_ "GenSigFirstTimeoutTime" BU_SG_REL_ HMIIOM SG_ 2432692031 SIDDayNight_ButtonStatus 3000;
BA_REL_ "GenSigTimeoutTime" BU_SG_REL_ HMIIOM SG_ 2432692031 SIDTouchScreenCoordinates_X 180;
BA_REL_ "GenSigFirstTimeoutTime" BU_SG_REL_ HMIIOM SG_ 2432692031 SIDTouchScreenCoordinates_X 3000;
BA_REL_ "GenSigTimeoutTime" BU_SG_REL_ HMIIOM SG_ 2432691983 ClusterSSStat_General 1200;
BA_REL_ "GenSigFirstTimeoutTime" BU_SG_REL_ HMIIOM SG_ 2432691983 ClusterSSStat_General 4800;
BA_REL_ "GenSigTimeoutTime" BU_SG_REL_ HMIIOM SG_ 2432691983 ClusterSSStat_Id 1200;
BA_REL_ "GenSigFirstTimeoutTime" BU_SG_REL_ HMIIOM SG_ 2432691983 ClusterSSStat_Id 4800;
BA_REL_ "GenSigTimeoutTime" BU_SG_REL_ HMIIOM SG_ 2432691983 ClusterSSStat_PlayStat 1200;
BA_REL_ "GenSigFirstTimeoutTime" BU_SG_REL_ HMIIOM SG_ 2432691983 ClusterSSStat_PlayStat 4800;
BA_REL_ "GenSigTimeoutTime" BU_SG_REL_ HMIIOM SG_ 2432683823 DirIndTelltale_stat 210;
BA_REL_ "GenSigFirstTimeoutTime" BU_SG_REL_ HMIIOM SG_ 2432683823 DirIndTelltale_stat 3000;
BA_REL_ "GenSigTimeoutTime" BU_SG_REL_ HMIIOM SG_ 2432683823 Tripmetershift_rqst 210;
BA_REL_ "GenSigFirstTimeoutTime" BU_SG_REL_ HMIIOM SG_ 2432683823 Tripmetershift_rqst 3000;
BA_REL_ "GenSigTimeoutTime" BU_SG_REL_ HMIIOM SG_ 2432683823 CabLightIntensity_stat 210;
BA_REL_ "GenSigFirstTimeoutTime" BU_SG_REL_ HMIIOM SG_ 2432683823 CabLightIntensity_stat 3000;
BA_REL_ "GenSigTimeoutTime" BU_SG_REL_ HMIIOM SG_ 2432683823 TripmeterReset_rqst 210;
BA_REL_ "GenSigFirstTimeoutTime" BU_SG_REL_ HMIIOM SG_ 2432683823 TripmeterReset_rqst 3000;
BA_REL_ "GenSigTimeoutTime" BU_SG_REL_ IC SG_ 2449452895 PresVal_DrivingMode 600;
BA_REL_ "GenSigFirstTimeoutTime" BU_SG_REL_ IC SG_ 2449452895 PresVal_DrivingMode 3000;
BA_REL_ "GenSigTimeoutTime" BU_SG_REL_ IC SG_ 2432675807 DIDIlluminationLevel_cmd 600;
BA_REL_ "GenSigFirstTimeoutTime" BU_SG_REL_ IC SG_ 2432675807 DIDIlluminationLevel_cmd 3000;
BA_REL_ "GenSigTimeoutTime" BU_SG_REL_ IC SG_ 2432675807 LEDIntensity 600;
BA_REL_ "GenSigFirstTimeoutTime" BU_SG_REL_ IC SG_ 2432675807 LEDIntensity 3000;
BA_REL_ "GenSigTimeoutTime" BU_SG_REL_ IC SG_ 2432675807 GaugeIllumLevelCmd 600;
BA_REL_ "GenSigFirstTimeoutTime" BU_SG_REL_ IC SG_ 2432675807 GaugeIllumLevelCmd 3000;
BA_REL_ "GenSigTimeoutTime" BU_SG_REL_ IC SG_ 2432675807 ContrastLevelCmd 600;
BA_REL_ "GenSigFirstTimeoutTime" BU_SG_REL_ IC SG_ 2432675807 ContrastLevelCmd 3000;
BA_REL_ "GenSigTimeoutTime" BU_SG_REL_ IC SG_ 2432675807 SelectedLanguage_stat 600;
BA_REL_ "GenSigFirstTimeoutTime" BU_SG_REL_ IC SG_ 2432675807 SelectedLanguage_stat 3000;
BA_REL_ "GenSigTimeoutTime" BU_SG_REL_ SIDHigh SG_ 2432675807 SelectedLanguage_stat 600;
BA_REL_ "GenSigFirstTimeoutTime" BU_SG_REL_ SIDHigh SG_ 2432675807 SelectedLanguage_stat 3000;
BA_REL_ "GenSigTimeoutTime" BU_SG_REL_ IC SG_ 2432675807 TelltaleIntensity 600;
BA_REL_ "GenSigFirstTimeoutTime" BU_SG_REL_ IC SG_ 2432675807 TelltaleIntensity 3000;
BA_REL_ "GenSigTimeoutTime" BU_SG_REL_ IC SG_ 2432675807 BacklightCmd 600;
BA_REL_ "GenSigFirstTimeoutTime" BU_SG_REL_ IC SG_ 2432675807 BacklightCmd 3000;
BA_REL_ "GenSigTimeoutTime" BU_SG_REL_ SIDHigh SG_ 2432675807 BacklightCmd 600;
BA_REL_ "GenSigFirstTimeoutTime" BU_SG_REL_ SIDHigh SG_ 2432675807 BacklightCmd 3000;
BA_REL_ "GenSigTimeoutTime" BU_SG_REL_ SIDHigh SG_ 2432675807 SIDIlluminationLevel_cmd 600;
BA_REL_ "GenSigFirstTimeoutTime" BU_SG_REL_ SIDHigh SG_ 2432675807 SIDIlluminationLevel_cmd 3000;
BA_REL_ "GenSigTimeoutTime" BU_SG_REL_ IC SG_ 2432675807 SIDIlluminationLevel_cmd 600;
BA_REL_ "GenSigFirstTimeoutTime" BU_SG_REL_ IC SG_ 2432675807 SIDIlluminationLevel_cmd 3000;
BA_REL_ "GenSigTimeoutTime" BU_SG_REL_ IC SG_ 2432675807 ClusterDispIllumLvlCmd 600;
BA_REL_ "GenSigFirstTimeoutTime" BU_SG_REL_ IC SG_ 2432675807 ClusterDispIllumLvlCmd 3000;
BA_REL_ "GenSigTimeoutTime" BU_SG_REL_ SIDHigh SG_ 2432675807 SIDOnOff 300;
BA_REL_ "GenSigFirstTimeoutTime" BU_SG_REL_ SIDHigh SG_ 2432675807 SIDOnOff 3000;
BA_REL_ "GenSigTimeoutTime" BU_SG_REL_ IC SG_ 2432675791 EnginePreheatAlert_cmd 360;
BA_REL_ "GenSigFirstTimeoutTime" BU_SG_REL_ IC SG_ 2432675791 EnginePreheatAlert_cmd 3000;
BA_REL_ "GenSigTimeoutTime" BU_SG_REL_ IC SG_ 2432675791 DifferentialLockWheelAlert_cmd 360;
BA_REL_ "GenSigFirstTimeoutTime" BU_SG_REL_ IC SG_ 2432675791 DifferentialLockWheelAlert_cmd 3000;
BA_REL_ "GenSigTimeoutTime" BU_SG_REL_ IC SG_ 2432675791 TotalVehicleDistanceHighRes 360;
BA_REL_ "GenSigFirstTimeoutTime" BU_SG_REL_ IC SG_ 2432675791 TotalVehicleDistanceHighRes 3000;
BA_REL_ "GenSigTimeoutTime" BU_SG_REL_ SIDHigh SG_ 2432675791 TotalVehicleDistanceHighRes 360;
BA_REL_ "GenSigFirstTimeoutTime" BU_SG_REL_ SIDHigh SG_ 2432675791 TotalVehicleDistanceHighRes 3000;
BA_REL_ "GenSigTimeoutTime" BU_SG_REL_ IC SG_ 2432675791 AutotestCmd 360;
BA_REL_ "GenSigFirstTimeoutTime" BU_SG_REL_ IC SG_ 2432675791 AutotestCmd 3000;
BA_REL_ "GenSigTimeoutTime" BU_SG_REL_ IC SG_ 2432675791 SpeedometerPSDViewSpeedUnit 360;
BA_REL_ "GenSigFirstTimeoutTime" BU_SG_REL_ IC SG_ 2432675791 SpeedometerPSDViewSpeedUnit 3000;
BA_REL_ "GenSigTimeoutTime" BU_SG_REL_ IC SG_ 2432675791 TripmeterResetCmd2 360;
BA_REL_ "GenSigFirstTimeoutTime" BU_SG_REL_ IC SG_ 2432675791 TripmeterResetCmd2 3000;
BA_REL_ "GenSigTimeoutTime" BU_SG_REL_ IC SG_ 2432675791 TripmeterResetCmd1 360;
BA_REL_ "GenSigFirstTimeoutTime" BU_SG_REL_ IC SG_ 2432675791 TripmeterResetCmd1 3000;
BA_REL_ "GenSigTimeoutTime" BU_SG_REL_ IC SG_ 2432675791 ASR_cmd 360;
BA_REL_ "GenSigFirstTimeoutTime" BU_SG_REL_ IC SG_ 2432675791 ASR_cmd 3000;
BA_REL_ "GenSigTimeoutTime" BU_SG_REL_ IC SG_ 2432675791 DiffLockInteraxleAlert_cmd 360;
BA_REL_ "GenSigFirstTimeoutTime" BU_SG_REL_ IC SG_ 2432675791 DiffLockInteraxleAlert_cmd 3000;
BA_REL_ "GenSigTimeoutTime" BU_SG_REL_ IC SG_ 2432675759 PresVal_ASLSpeedBlinkCmd 180;
BA_REL_ "GenSigFirstTimeoutTime" BU_SG_REL_ IC SG_ 2432675759 PresVal_ASLSpeedBlinkCmd 3000;
BA_REL_ "GenSigTimeoutTime" BU_SG_REL_ IC SG_ 2432675759 PresVal_ASLSetSpeed 180;
BA_REL_ "GenSigFirstTimeoutTime" BU_SG_REL_ IC SG_ 2432675759 PresVal_ASLSetSpeed 3000;
BA_REL_ "GenSigTimeoutTime" BU_SG_REL_ IC SG_ 2432675759 PresVal_GearLeverModeBlink 180;
BA_REL_ "GenSigFirstTimeoutTime" BU_SG_REL_ IC SG_ 2432675759 PresVal_GearLeverModeBlink 3000;
BA_REL_ "GenSigTimeoutTime" BU_SG_REL_ IC SG_ 2432675759 PresValReqTimeGap 180;
BA_REL_ "GenSigFirstTimeoutTime" BU_SG_REL_ IC SG_ 2432675759 PresValReqTimeGap 3000;
BA_REL_ "GenSigTimeoutTime" BU_SG_REL_ IC SG_ 2432675759 PresVal_CoolantTemp 180;
BA_REL_ "GenSigFirstTimeoutTime" BU_SG_REL_ IC SG_ 2432675759 PresVal_CoolantTemp 3000;
BA_REL_ "GenSigTimeoutTime" BU_SG_REL_ IC SG_ 2432675759 PresVal_EngineCoolantTemp 180;
BA_REL_ "GenSigFirstTimeoutTime" BU_SG_REL_ IC SG_ 2432675759 PresVal_EngineCoolantTemp 3000;
BA_REL_ "GenSigTimeoutTime" BU_SG_REL_ IC SG_ 2432675759 PresVal_CCSetSpeed 180;
BA_REL_ "GenSigFirstTimeoutTime" BU_SG_REL_ IC SG_ 2432675759 PresVal_CCSetSpeed 3000;
BA_REL_ "GenSigTimeoutTime" BU_SG_REL_ IC SG_ 2432675759 PresVal_CCEnabledStatus 180;
BA_REL_ "GenSigFirstTimeoutTime" BU_SG_REL_ IC SG_ 2432675759 PresVal_CCEnabledStatus 3000;
BA_REL_ "GenSigTimeoutTime" BU_SG_REL_ IC SG_ 2432675759 PresVal_ASLActiveStatus 180;
BA_REL_ "GenSigFirstTimeoutTime" BU_SG_REL_ IC SG_ 2432675759 PresVal_ASLActiveStatus 3000;
BA_REL_ "GenSigTimeoutTime" BU_SG_REL_ IC SG_ 2432675759 PresVal_CCSpeedInactive 180;
BA_REL_ "GenSigFirstTimeoutTime" BU_SG_REL_ IC SG_ 2432675759 PresVal_CCSpeedInactive 3000;
BA_REL_ "GenSigTimeoutTime" BU_SG_REL_ IC SG_ 2432675759 PresVal_CoolantTempHigh 180;
BA_REL_ "GenSigFirstTimeoutTime" BU_SG_REL_ IC SG_ 2432675759 PresVal_CoolantTempHigh 3000;
BA_REL_ "GenSigTimeoutTime" BU_SG_REL_ IC SG_ 2432675759 PresVal_CCActiveStatus 180;
BA_REL_ "GenSigFirstTimeoutTime" BU_SG_REL_ IC SG_ 2432675759 PresVal_CCActiveStatus 3000;
BA_REL_ "GenSigTimeoutTime" BU_SG_REL_ IC SG_ 2432675759 PresVal_CCSpeedBlinkCmd 180;
BA_REL_ "GenSigFirstTimeoutTime" BU_SG_REL_ IC SG_ 2432675759 PresVal_CCSpeedBlinkCmd 3000;
BA_REL_ "GenSigTimeoutTime" BU_SG_REL_ IC SG_ 2432675759 PresVal_GearLeverModeASCII 180;
BA_REL_ "GenSigFirstTimeoutTime" BU_SG_REL_ IC SG_ 2432675759 PresVal_GearLeverModeASCII 3000;
BA_REL_ "GenSigTimeoutTime" BU_SG_REL_ IC SG_ 2432675759 PresVal_GearLeverModeFrame 180;
BA_REL_ "GenSigFirstTimeoutTime" BU_SG_REL_ IC SG_ 2432675759 PresVal_GearLeverModeFrame 3000;
BA_REL_ "GenSigTimeoutTime" BU_SG_REL_ SIDHigh SG_ 2449452927 HoursUTC 600;
BA_REL_ "GenSigFirstTimeoutTime" BU_SG_REL_ SIDHigh SG_ 2449452927 HoursUTC 3000;
BA_REL_ "GenSigTimeoutTime" BU_SG_REL_ IC SG_ 2449452927 HoursUTC 600;
BA_REL_ "GenSigFirstTimeoutTime" BU_SG_REL_ IC SG_ 2449452927 HoursUTC 3000;
BA_REL_ "GenSigTimeoutTime" BU_SG_REL_ IC SG_ 2449452927 SecondsUTC 600;
BA_REL_ "GenSigFirstTimeoutTime" BU_SG_REL_ IC SG_ 2449452927 SecondsUTC 3000;
BA_REL_ "GenSigTimeoutTime" BU_SG_REL_ SIDHigh SG_ 2449452927 SecondsUTC 600;
BA_REL_ "GenSigFirstTimeoutTime" BU_SG_REL_ SIDHigh SG_ 2449452927 SecondsUTC 3000;
BA_REL_ "GenSigTimeoutTime" BU_SG_REL_ SIDHigh SG_ 2449452927 YearUTC 600;
BA_REL_ "GenSigFirstTimeoutTime" BU_SG_REL_ SIDHigh SG_ 2449452927 YearUTC 3000;
BA_REL_ "GenSigTimeoutTime" BU_SG_REL_ IC SG_ 2449452927 YearUTC 600;
BA_REL_ "GenSigFirstTimeoutTime" BU_SG_REL_ IC SG_ 2449452927 YearUTC 3000;
BA_REL_ "GenSigTimeoutTime" BU_SG_REL_ IC SG_ 2449452927 MinutesUTC 600;
BA_REL_ "GenSigFirstTimeoutTime" BU_SG_REL_ IC SG_ 2449452927 MinutesUTC 3000;
BA_REL_ "GenSigTimeoutTime" BU_SG_REL_ SIDHigh SG_ 2449452927 MinutesUTC 600;
BA_REL_ "GenSigFirstTimeoutTime" BU_SG_REL_ SIDHigh SG_ 2449452927 MinutesUTC 3000;
BA_REL_ "GenSigTimeoutTime" BU_SG_REL_ IC SG_ 2449452927 DayUTC 600;
BA_REL_ "GenSigFirstTimeoutTime" BU_SG_REL_ IC SG_ 2449452927 DayUTC 3000;
BA_REL_ "GenSigTimeoutTime" BU_SG_REL_ SIDHigh SG_ 2449452927 DayUTC 600;
BA_REL_ "GenSigFirstTimeoutTime" BU_SG_REL_ SIDHigh SG_ 2449452927 DayUTC 3000;
BA_REL_ "GenSigTimeoutTime" BU_SG_REL_ IC SG_ 2449452927 AmbientAirTemperature 600;
BA_REL_ "GenSigFirstTimeoutTime" BU_SG_REL_ IC SG_ 2449452927 AmbientAirTemperature 3000;
BA_REL_ "GenSigTimeoutTime" BU_SG_REL_ SIDHigh SG_ 2449452927 AmbientAirTemperature 600;
BA_REL_ "GenSigFirstTimeoutTime" BU_SG_REL_ SIDHigh SG_ 2449452927 AmbientAirTemperature 3000;
BA_REL_ "GenSigTimeoutTime" BU_SG_REL_ SIDHigh SG_ 2449452927 MonthUTC 600;
BA_REL_ "GenSigFirstTimeoutTime" BU_SG_REL_ SIDHigh SG_ 2449452927 MonthUTC 3000;
BA_REL_ "GenSigTimeoutTime" BU_SG_REL_ IC SG_ 2449452927 MonthUTC 600;
BA_REL_ "GenSigFirstTimeoutTime" BU_SG_REL_ IC SG_ 2449452927 MonthUTC 3000;
BA_REL_ "GenSigTimeoutTime" BU_SG_REL_ IC SG_ 2449452879 PresVal_HighResTotalVehDist 600;
BA_REL_ "GenSigFirstTimeoutTime" BU_SG_REL_ IC SG_ 2449452879 PresVal_HighResTotalVehDist 3000;
BA_REL_ "GenSigTimeoutTime" BU_SG_REL_ IC SG_ 2449452879 PresVal_HighResolutionTripDist 600;
BA_REL_ "GenSigFirstTimeoutTime" BU_SG_REL_ IC SG_ 2449452879 PresVal_HighResolutionTripDist 3000;
BA_REL_ "GenSigTimeoutTime" BU_SG_REL_ IC SG_ 2432667503 PresVal_TransmSelectedGear 180;
BA_REL_ "GenSigFirstTimeoutTime" BU_SG_REL_ IC SG_ 2432667503 PresVal_TransmSelectedGear 3000;
BA_REL_ "GenSigTimeoutTime" BU_SG_REL_ IC SG_ 2432667503 PresVal_VehicleSpeed 180;
BA_REL_ "GenSigFirstTimeoutTime" BU_SG_REL_ IC SG_ 2432667503 PresVal_VehicleSpeed 3000;
BA_REL_ "GenSigTimeoutTime" BU_SG_REL_ IC SG_ 2432667503 PresVal_EngineSpeed 180;
BA_REL_ "GenSigFirstTimeoutTime" BU_SG_REL_ IC SG_ 2432667503 PresVal_EngineSpeed 3000;
BA_REL_ "GenSigTimeoutTime" BU_SG_REL_ IC SG_ 2432667503 SpeedometerPSDViewCurrentSpeed 180;
BA_REL_ "GenSigFirstTimeoutTime" BU_SG_REL_ IC SG_ 2432667503 SpeedometerPSDViewCurrentSpeed 3000;
BA_REL_ "GenSigTimeoutTime" BU_SG_REL_ IC SG_ 2432659343 PresVal_CatalystTankLevel 180;
BA_REL_ "GenSigFirstTimeoutTime" BU_SG_REL_ IC SG_ 2432659343 PresVal_CatalystTankLevel 3000;
BA_REL_ "GenSigTimeoutTime" BU_SG_REL_ IC SG_ 2432659343 FormatedVehicleSpeed 180;
BA_REL_ "GenSigFirstTimeoutTime" BU_SG_REL_ IC SG_ 2432659343 FormatedVehicleSpeed 3000;
BA_REL_ "GenSigTimeoutTime" BU_SG_REL_ IC SG_ 2432659343 PresVal_ClockHours 180;
BA_REL_ "GenSigFirstTimeoutTime" BU_SG_REL_ IC SG_ 2432659343 PresVal_ClockHours 3000;
BA_REL_ "GenSigTimeoutTime" BU_SG_REL_ IC SG_ 2432659343 PresVal_ClockPeriod 180;
BA_REL_ "GenSigFirstTimeoutTime" BU_SG_REL_ IC SG_ 2432659343 PresVal_ClockPeriod 3000;
BA_REL_ "GenSigTimeoutTime" BU_SG_REL_ IC SG_ 2432659343 PresVal_AvailGearsLowerRatio 180;
BA_REL_ "GenSigFirstTimeoutTime" BU_SG_REL_ IC SG_ 2432659343 PresVal_AvailGearsLowerRatio 3000;
BA_REL_ "GenSigTimeoutTime" BU_SG_REL_ IC SG_ 2432659343 PresVal_ClockMinutes 180;
BA_REL_ "GenSigFirstTimeoutTime" BU_SG_REL_ IC SG_ 2432659343 PresVal_ClockMinutes 3000;
BA_REL_ "GenSigTimeoutTime" BU_SG_REL_ IC SG_ 2432659343 PresVal_AirPressure 180;
BA_REL_ "GenSigFirstTimeoutTime" BU_SG_REL_ IC SG_ 2432659343 PresVal_AirPressure 3000;
BA_REL_ "GenSigTimeoutTime" BU_SG_REL_ IC SG_ 2432659343 PresVal_AmbientAirTemperature 180;
BA_REL_ "GenSigFirstTimeoutTime" BU_SG_REL_ IC SG_ 2432659343 PresVal_AmbientAirTemperature 3000;
BA_REL_ "GenSigTimeoutTime" BU_SG_REL_ IC SG_ 2432659343 PresVal_AvailGearsHigherRatio 180;
BA_REL_ "GenSigFirstTimeoutTime" BU_SG_REL_ IC SG_ 2432659343 PresVal_AvailGearsHigherRatio 3000;
BA_REL_ "GenSigTimeoutTime" BU_SG_REL_ IC SG_ 2432651183 PresVal_OdometerUnit 180;
BA_REL_ "GenSigFirstTimeoutTime" BU_SG_REL_ IC SG_ 2432651183 PresVal_OdometerUnit 3000;
BA_REL_ "GenSigTimeoutTime" BU_SG_REL_ IC SG_ 2432651183 ZoningBandsActiveBlueLEDRange2 180;
BA_REL_ "GenSigFirstTimeoutTime" BU_SG_REL_ IC SG_ 2432651183 ZoningBandsActiveBlueLEDRange2 3000;
BA_REL_ "GenSigTimeoutTime" BU_SG_REL_ IC SG_ 2432651183 ZoningBandsActiveBlueLEDRange1 180;
BA_REL_ "GenSigFirstTimeoutTime" BU_SG_REL_ IC SG_ 2432651183 ZoningBandsActiveBlueLEDRange1 3000;
BA_REL_ "GenSigTimeoutTime" BU_SG_REL_ IC SG_ 2432651183 PresVal_LowFuelLevelWrn_stat 180;
BA_REL_ "GenSigFirstTimeoutTime" BU_SG_REL_ IC SG_ 2432651183 PresVal_LowFuelLevelWrn_stat 3000;
BA_REL_ "GenSigTimeoutTime" BU_SG_REL_ IC SG_ 2432651183 LCDFormattedVehSpdBlink_cmd 180;
BA_REL_ "GenSigFirstTimeoutTime" BU_SG_REL_ IC SG_ 2432651183 LCDFormattedVehSpdBlink_cmd 3000;
BA_REL_ "GenSigTimeoutTime" BU_SG_REL_ IC SG_ 2432651183 PresVal_ACCReducedMode 180;
BA_REL_ "GenSigFirstTimeoutTime" BU_SG_REL_ IC SG_ 2432651183 PresVal_ACCReducedMode 3000;
BA_REL_ "GenSigTimeoutTime" BU_SG_REL_ IC SG_ 2432651183 PresVal_FuelLevel 180;
BA_REL_ "GenSigFirstTimeoutTime" BU_SG_REL_ IC SG_ 2432651183 PresVal_FuelLevel 3000;
BA_REL_ "GenSigTimeoutTime" BU_SG_REL_ IC SG_ 2432651183 PresVal_AuxiliaryBrakesActivat 180;
BA_REL_ "GenSigFirstTimeoutTime" BU_SG_REL_ IC SG_ 2432651183 PresVal_AuxiliaryBrakesActivat 3000;
BA_REL_ "GenSigTimeoutTime" BU_SG_REL_ IC SG_ 2432651183 PresVal_AmbientAirTempUnit 180;
BA_REL_ "GenSigFirstTimeoutTime" BU_SG_REL_ IC SG_ 2432651183 PresVal_AmbientAirTempUnit 3000;
BA_REL_ "GenSigTimeoutTime" BU_SG_REL_ IC SG_ 2432651183 PresVal_TargetDetected 180;
BA_REL_ "GenSigFirstTimeoutTime" BU_SG_REL_ IC SG_ 2432651183 PresVal_TargetDetected 3000;
BA_REL_ "GenSigTimeoutTime" BU_SG_REL_ IC SG_ 2432651183 SeatBeltReminderAlert_cmd 180;
BA_REL_ "GenSigFirstTimeoutTime" BU_SG_REL_ IC SG_ 2432651183 SeatBeltReminderAlert_cmd 3000;
BA_REL_ "GenSigTimeoutTime" BU_SG_REL_ IC SG_ 2432651183 PresVal_CrossCountryStatus 180;
BA_REL_ "GenSigFirstTimeoutTime" BU_SG_REL_ IC SG_ 2432651183 PresVal_CrossCountryStatus 3000;
BA_REL_ "GenSigTimeoutTime" BU_SG_REL_ IC SG_ 2432651183 PresVal_TripmeterChoice 180;
BA_REL_ "GenSigFirstTimeoutTime" BU_SG_REL_ IC SG_ 2432651183 PresVal_TripmeterChoice 3000;
BA_REL_ "GenSigTimeoutTime" BU_SG_REL_ IC SG_ 2432651183 ZoningBandsActiveGreenLEDRng2 180;
BA_REL_ "GenSigFirstTimeoutTime" BU_SG_REL_ IC SG_ 2432651183 ZoningBandsActiveGreenLEDRng2 3000;
BA_REL_ "GenSigTimeoutTime" BU_SG_REL_ SIDHigh SG_ 2432651183 SIDPresentationMode 180;
BA_REL_ "GenSigFirstTimeoutTime" BU_SG_REL_ SIDHigh SG_ 2432651183 SIDPresentationMode 3000;
BA_REL_ "GenSigTimeoutTime" BU_SG_REL_ IC SG_ 2432651183 VehicleSpeedLCDSpeedUnitCmd 180;
BA_REL_ "GenSigFirstTimeoutTime" BU_SG_REL_ IC SG_ 2432651183 VehicleSpeedLCDSpeedUnitCmd 3000;
BA_REL_ "GenSigTimeoutTime" BU_SG_REL_ IC SG_ 2432651183 PresVal_CatalystTankLevelLow 180;
BA_REL_ "GenSigFirstTimeoutTime" BU_SG_REL_ IC SG_ 2432651183 PresVal_CatalystTankLevelLow 3000;
BA_REL_ "GenSigTimeoutTime" BU_SG_REL_ IC SG_ 2432651183 PresVal_ACCStatus 180;
BA_REL_ "GenSigFirstTimeoutTime" BU_SG_REL_ IC SG_ 2432651183 PresVal_ACCStatus 3000;
BA_REL_ "GenSigTimeoutTime" BU_SG_REL_ IC SG_ 2432651183 PresVal_AuxiliaryBrakesPos 180;
BA_REL_ "GenSigFirstTimeoutTime" BU_SG_REL_ IC SG_ 2432651183 PresVal_AuxiliaryBrakesPos 3000;
BA_REL_ "GenSigTimeoutTime" BU_SG_REL_ IC SG_ 2432651183 PresVal_EngSpdCtrlStatus 180;
BA_REL_ "GenSigFirstTimeoutTime" BU_SG_REL_ IC SG_ 2432651183 PresVal_EngSpdCtrlStatus 3000;
BA_REL_ "GenSigTimeoutTime" BU_SG_REL_ IC SG_ 2432651183 ZoningBandsActiveRedLEDRange1 180;
BA_REL_ "GenSigFirstTimeoutTime" BU_SG_REL_ IC SG_ 2432651183 ZoningBandsActiveRedLEDRange1 3000;
BA_REL_ "GenSigTimeoutTime" BU_SG_REL_ IC SG_ 2432651183 PresVal_LowAmbientTempWarning 180;
BA_REL_ "GenSigFirstTimeoutTime" BU_SG_REL_ IC SG_ 2432651183 PresVal_LowAmbientTempWarning 3000;
BA_REL_ "GenSigTimeoutTime" BU_SG_REL_ IC SG_ 2432651183 ZoningBandsActiveGreenLEDRng1 180;
BA_REL_ "GenSigFirstTimeoutTime" BU_SG_REL_ IC SG_ 2432651183 ZoningBandsActiveGreenLEDRng1 3000;
BA_REL_ "GenSigTimeoutTime" BU_SG_REL_ IC SG_ 2432634863 DippedBeamAlert_cmd 60;
BA_REL_ "GenSigFirstTimeoutTime" BU_SG_REL_ IC SG_ 2432634863 DippedBeamAlert_cmd 3000;
BA_REL_ "GenSigTimeoutTime" BU_SG_REL_ IC SG_ 2432634863 VehicleMode 500;
BA_REL_ "GenSigFirstTimeoutTime" BU_SG_REL_ IC SG_ 2432634863 VehicleMode 3000;
BA_REL_ "GenSigTimeoutTime" BU_SG_REL_ SIDHigh SG_ 2432634863 VehicleMode 500;
BA_REL_ "GenSigFirstTimeoutTime" BU_SG_REL_ SIDHigh SG_ 2432634863 VehicleMode 3000;
BA_REL_ "GenSigTimeoutTime" BU_SG_REL_ IC SG_ 2432634863 LiftAxle1Alert_cmd 60;
BA_REL_ "GenSigFirstTimeoutTime" BU_SG_REL_ IC SG_ 2432634863 LiftAxle1Alert_cmd 3000;
BA_REL_ "GenSigTimeoutTime" BU_SG_REL_ IC SG_ 2432634863 DirIndicatorRtTrailerAlert_cmd 60;
BA_REL_ "GenSigFirstTimeoutTime" BU_SG_REL_ IC SG_ 2432634863 DirIndicatorRtTrailerAlert_cmd 3000;
BA_REL_ "GenSigTimeoutTime" BU_SG_REL_ IC SG_ 2432634863 FogLightFrontAlert_cmd 60;
BA_REL_ "GenSigFirstTimeoutTime" BU_SG_REL_ IC SG_ 2432634863 FogLightFrontAlert_cmd 3000;
BA_REL_ "GenSigTimeoutTime" BU_SG_REL_ IC SG_ 2432634863 LiftAxle2Alert_cmd 60;
BA_REL_ "GenSigFirstTimeoutTime" BU_SG_REL_ IC SG_ 2432634863 LiftAxle2Alert_cmd 3000;
BA_REL_ "GenSigTimeoutTime" BU_SG_REL_ IC SG_ 2432634863 ExtraSpotLampsAlert_cmd 60;
BA_REL_ "GenSigFirstTimeoutTime" BU_SG_REL_ IC SG_ 2432634863 ExtraSpotLampsAlert_cmd 3000;
BA_REL_ "GenSigTimeoutTime" BU_SG_REL_ IC SG_ 2432634863 AdBlueLevelLowAlert_cmd 60;
BA_REL_ "GenSigFirstTimeoutTime" BU_SG_REL_ IC SG_ 2432634863 AdBlueLevelLowAlert_cmd 3000;
BA_REL_ "GenSigTimeoutTime" BU_SG_REL_ IC SG_ 2432634863 DirIndicatorLtTrailerAlert_cmd 60;
BA_REL_ "GenSigFirstTimeoutTime" BU_SG_REL_ IC SG_ 2432634863 DirIndicatorLtTrailerAlert_cmd 3000;
BA_REL_ "GenSigTimeoutTime" BU_SG_REL_ IC SG_ 2432634863 EngineMalFunctionAlert_cmd 60;
BA_REL_ "GenSigFirstTimeoutTime" BU_SG_REL_ IC SG_ 2432634863 EngineMalFunctionAlert_cmd 3000;
BA_REL_ "GenSigTimeoutTime" BU_SG_REL_ IC SG_ 2432634863 FuelLevelLowAlert_cmd 60;
BA_REL_ "GenSigFirstTimeoutTime" BU_SG_REL_ IC SG_ 2432634863 FuelLevelLowAlert_cmd 3000;
BA_REL_ "GenSigTimeoutTime" BU_SG_REL_ IC SG_ 2432634863 PosLightAlert_cmd 60;
BA_REL_ "GenSigFirstTimeoutTime" BU_SG_REL_ IC SG_ 2432634863 PosLightAlert_cmd 3000;
BA_REL_ "GenSigTimeoutTime" BU_SG_REL_ IC SG_ 2432634863 MainBeamAlert_cmd 60;
BA_REL_ "GenSigFirstTimeoutTime" BU_SG_REL_ IC SG_ 2432634863 MainBeamAlert_cmd 3000;
BA_REL_ "GenSigTimeoutTime" BU_SG_REL_ IC SG_ 2432634863 DirIndicatorRightAlert_cmd 60;
BA_REL_ "GenSigFirstTimeoutTime" BU_SG_REL_ IC SG_ 2432634863 DirIndicatorRightAlert_cmd 3000;
BA_REL_ "GenSigTimeoutTime" BU_SG_REL_ IC SG_ 2432634863 ParkBrakeAlert_cmd 60;
BA_REL_ "GenSigFirstTimeoutTime" BU_SG_REL_ IC SG_ 2432634863 ParkBrakeAlert_cmd 3000;
BA_REL_ "GenSigTimeoutTime" BU_SG_REL_ IC SG_ 2432634863 FogLightRearAlert_cmd 60;
BA_REL_ "GenSigFirstTimeoutTime" BU_SG_REL_ IC SG_ 2432634863 FogLightRearAlert_cmd 3000;
BA_REL_ "GenSigTimeoutTime" BU_SG_REL_ IC SG_ 2432634863 DirIndicatorLeftAlert_cmd 60;
BA_REL_ "GenSigFirstTimeoutTime" BU_SG_REL_ IC SG_ 2432634863 DirIndicatorLeftAlert_cmd 3000;
BA_REL_ "GenSigTimeoutTime" BU_SG_REL_ IC SG_ 2432634863 CheckAlert_cmd 60;
BA_REL_ "GenSigFirstTimeoutTime" BU_SG_REL_ IC SG_ 2432634863 CheckAlert_cmd 3000;
BA_REL_ "GenSigTimeoutTime" BU_SG_REL_ IC SG_ 2432634863 StopAlert_cmd 60;
BA_REL_ "GenSigFirstTimeoutTime" BU_SG_REL_ IC SG_ 2432634863 StopAlert_cmd 3000;
BA_REL_ "GenSigTimeoutTime" BU_SG_REL_ HMIIOM SG_ 2567045123 DiagFaultStat_SIDH_DtcIdB 6000;
BA_REL_ "GenSigFirstTimeoutTime" BU_SG_REL_ HMIIOM SG_ 2567045123 DiagFaultStat_SIDH_DtcIdB 24000;
BA_REL_ "GenSigTimeoutTime" BU_SG_REL_ HMIIOM SG_ 2567045123 DiagFaultStat_SIDH_FailTB 6000;
BA_REL_ "GenSigFirstTimeoutTime" BU_SG_REL_ HMIIOM SG_ 2567045123 DiagFaultStat_SIDH_FailTB 24000;
BA_REL_ "GenSigTimeoutTime" BU_SG_REL_ HMIIOM SG_ 2567045123 DiagFaultStat_SIDH_DtcIdA 6000;
BA_REL_ "GenSigFirstTimeoutTime" BU_SG_REL_ HMIIOM SG_ 2567045123 DiagFaultStat_SIDH_DtcIdA 24000;
BA_REL_ "GenSigTimeoutTime" BU_SG_REL_ HMIIOM SG_ 2567045123 DiagFaultStat_SIDH_FailTA 6000;
BA_REL_ "GenSigFirstTimeoutTime" BU_SG_REL_ HMIIOM SG_ 2567045123 DiagFaultStat_SIDH_FailTA 24000;
BA_REL_ "GenSigTimeoutTime" BU_SG_REL_ HMIIOM SG_ 2567045123 DiagFaultStat_SIDH_EcuAdr 6000;
BA_REL_ "GenSigFirstTimeoutTime" BU_SG_REL_ HMIIOM SG_ 2567045123 DiagFaultStat_SIDH_EcuAdr 24000;
BA_REL_ "GenSigTimeoutTime" BU_SG_REL_ HMIIOM SG_ 2567045121 DiagFaultStat_IC_DtcIdA 6000;
BA_REL_ "GenSigFirstTimeoutTime" BU_SG_REL_ HMIIOM SG_ 2567045121 DiagFaultStat_IC_DtcIdA 24000;
BA_REL_ "GenSigTimeoutTime" BU_SG_REL_ HMIIOM SG_ 2567045121 DiagFaultStat_IC_FailTA 6000;
BA_REL_ "GenSigFirstTimeoutTime" BU_SG_REL_ HMIIOM SG_ 2567045121 DiagFaultStat_IC_FailTA 24000;
BA_REL_ "GenSigTimeoutTime" BU_SG_REL_ HMIIOM SG_ 2567045121 DiagFaultStat_IC_EcuAdr 6000;
BA_REL_ "GenSigFirstTimeoutTime" BU_SG_REL_ HMIIOM SG_ 2567045121 DiagFaultStat_IC_EcuAdr 24000;
BA_REL_ "GenSigTimeoutTime" BU_SG_REL_ HMIIOM SG_ 2567045121 DiagFaultStat_IC_FailTB 6000;
BA_REL_ "GenSigFirstTimeoutTime" BU_SG_REL_ HMIIOM SG_ 2567045121 DiagFaultStat_IC_FailTB 24000;
BA_REL_ "GenSigTimeoutTime" BU_SG_REL_ HMIIOM SG_ 2567045121 DiagFaultStat_IC_DtcIdB 6000;
BA_REL_ "GenSigFirstTimeoutTime" BU_SG_REL_ HMIIOM SG_ 2567045121 DiagFaultStat_IC_DtcIdB 24000;
VAL_ 2432692031 SIDOnOff_ButtonStatus 3 "PushButtonStatus_NotAvailable" 2 "PushButtonStatus_Error" 1 "PushButtonStatus_Pushed" 0 "PushButtonStatus_Neutral" ;
VAL_ 2432692031 SIDMute_ButtonStatus 3 "PushButtonStatus_NotAvailable" 2 "PushButtonStatus_Error" 1 "PushButtonStatus_Pushed" 0 "PushButtonStatus_Neutral" ;
VAL_ 2432692031 SIDSourceSelect_ButtonStatus 3 "PushButtonStatus_NotAvailable" 2 "PushButtonStatus_Error" 1 "PushButtonStatus_Pushed" 0 "PushButtonStatus_Neutral" ;
VAL_ 2432692031 SIDDayNight_ButtonStatus 3 "PushButtonStatus_NotAvailable" 2 "PushButtonStatus_Error" 1 "PushButtonStatus_Pushed" 0 "PushButtonStatus_Neutral" ;
VAL_ 2432691983 ClusterSSStat_General 1 "SystemSoundGeneral_DegradedFunction" 0 "SystemSoundGeneral_Normal" ;
VAL_ 2432691983 ClusterSSStat_PlayStat 1 "SystemSoundPlayStat_Playing" 0 "SystemSoundPlayStat_Stopped" ;
VAL_ 2432683823 DirIndTelltale_stat 3 "DeactivateActivate_NotAvailable" 2 "DeactivateActivate_Error" 1 "DeactivateActivate_Activate" 0 "DeactivateActivate_Deactivate" ;
VAL_ 2432683823 Tripmetershift_rqst 3 "TripMeter_NotAvailable" 2 "TripMeter_Error" 1 "TripMeter_Tripcounter2" 0 "TripMeter_Tripcounter1" ;
VAL_ 2432683823 TripmeterReset_rqst 7 "TripmeterReset_rqst_NotAvailable" 6 "TripmeterReset_rqst_ErrorIndicator" 5 "TripmeterReset_rqst_SpareValue_02" 4 "TripmeterReset_rqst_SpareValue_01" 3 "TripmeterReset_rqst_SpareValue" 2 "TripmeterReset_rqst_Inactive" 1 "TripmeterReset_rqst_Tripcounter2Reset" 0 "TripmeterReset_rqst_Tripcounter1Reset" ;
VAL_ 2432675807 LEDIntensity 31 "BacklightCmd_NotAvailable" 30 "BacklightCmd_Error" 16 "BacklightCmd_BacklightLevel16" 15 "BacklightCmd_BacklightLevel15" 14 "BacklightCmd_BacklightLevel14" 13 "BacklightCmd_BacklightLevel13" 12 "BacklightCmd_BacklightLevel12" 11 "BacklightCmd_BacklightLevel11" 10 "BacklightCmd_BacklightLevel10" 9 "BacklightCmd_BacklightLevel9" 8 "BacklightCmd_BacklightLevel8" 7 "BacklightCmd_BacklightLevel7" 6 "BacklightCmd_BacklightLevel6" 5 "BacklightCmd_BacklightLevel5" 4 "BacklightCmd_BacklightLevel4" 3 "BacklightCmd_BacklightLevel3" 2 "BacklightCmd_BacklightLevel2" 1 "BacklightCmd_BacklightLevel1" 0 "BacklightCmd_BacklightOff" ;
VAL_ 2432675807 SelectedLanguage_stat 63 "Language_NotAvailable" 62 "Language_Error" 61 "Language_Spare_26" 60 "Language_Spare_25" 59 "Language_Spare_24" 58 "Language_Spare_23" 57 "Language_Spare_22" 56 "Language_Spare_21" 55 "Language_Spare_20" 54 "Language_Spare_19" 53 "Language_Spare_18" 52 "Language_Spare_17" 51 "Language_Spare_16" 50 "Language_Spare_15" 49 "Language_Spare_14" 48 "Language_Spare_13" 47 "Language_Spare_12" 46 "Language_Spare_11" 45 "Language_Spare_10" 44 "Language_Spare_09" 43 "Language_Spare_08" 42 "Language_Spare_07" 41 "Language_Spare_06" 40 "Language_Spare_05" 39 "Language_Spare_04" 38 "Language_Spare_03" 37 "Language_Spare_02" 36 "Language_Spare_01" 35 "Language_Croatian" 34 "Language_Numeric" 33 "Language_Japanese" 32 "Language_Korean" 31 "Language_Chinese" 30 "Language_Thai" 29 "Language_Arabic" 28 "Language_Farsi" 27 "Language_Hebrew" 26 "Language_Turkish" 25 "Language_Hungarian" 24 "Language_Slovak" 23 "Language_Czech" 22 "Language_Slovenian" 21 "Language_Serbian" 20 "Language_Greek" 19 "Language_Bulgarian" 18 "Language_Italian" 17 "Language_Dutch" 16 "Language_Rumanian" 15 "Language_BrazilianPortugese" 14 "Language_Portugese" 13 "Language_Spanish" 12 "Language_French" 11 "Language_German" 10 "Language_Polish" 9 "Language_Lituanian" 8 "Language_Latvian" 7 "Language_Estonian" 6 "Language_Russian" 5 "Language_Finish" 4 "Language_Icelandic" 3 "Language_Norwegian" 2 "Language_Danish" 1 "Language_Swedish" 0 "Language_English" ;
VAL_ 2432675807 TelltaleIntensity 31 "BacklightCmd_NotAvailable" 30 "BacklightCmd_Error" 16 "BacklightCmd_BacklightLevel16" 15 "BacklightCmd_BacklightLevel15" 14 "BacklightCmd_BacklightLevel14" 13 "BacklightCmd_BacklightLevel13" 12 "BacklightCmd_BacklightLevel12" 11 "BacklightCmd_BacklightLevel11" 10 "BacklightCmd_BacklightLevel10" 9 "BacklightCmd_BacklightLevel9" 8 "BacklightCmd_BacklightLevel8" 7 "BacklightCmd_BacklightLevel7" 6 "BacklightCmd_BacklightLevel6" 5 "BacklightCmd_BacklightLevel5" 4 "BacklightCmd_BacklightLevel4" 3 "BacklightCmd_BacklightLevel3" 2 "BacklightCmd_BacklightLevel2" 1 "BacklightCmd_BacklightLevel1" 0 "BacklightCmd_BacklightOff" ;
VAL_ 2432675807 BacklightCmd 31 "BacklightCmd_NotAvailable" 30 "BacklightCmd_Error" 16 "BacklightCmd_BacklightLevel16" 15 "BacklightCmd_BacklightLevel15" 14 "BacklightCmd_BacklightLevel14" 13 "BacklightCmd_BacklightLevel13" 12 "BacklightCmd_BacklightLevel12" 11 "BacklightCmd_BacklightLevel11" 10 "BacklightCmd_BacklightLevel10" 9 "BacklightCmd_BacklightLevel9" 8 "BacklightCmd_BacklightLevel8" 7 "BacklightCmd_BacklightLevel7" 6 "BacklightCmd_BacklightLevel6" 5 "BacklightCmd_BacklightLevel5" 4 "BacklightCmd_BacklightLevel4" 3 "BacklightCmd_BacklightLevel3" 2 "BacklightCmd_BacklightLevel2" 1 "BacklightCmd_BacklightLevel1" 0 "BacklightCmd_BacklightOff" ;
VAL_ 2432675807 SIDOnOff 3 "OffOn_NotAvailable" 2 "OffOn_Error" 1 "OffOn_On" 0 "OffOn_Off" ;
VAL_ 2449453039 InstrTestSymbolsCmd 3 "StopStartTest_NotAvailable" 2 "StopStartTest_Error" 1 "StopStartTest_StartTheTest" 0 "StopStartTest_StopTheTest" ;
VAL_ 2449453039 InstrTestGaugesCmd 3 "StopStartTest_NotAvailable" 2 "StopStartTest_Error" 1 "StopStartTest_StartTheTest" 0 "StopStartTest_StopTheTest" ;
VAL_ 2449453039 InstrTestDisplaysCmd 3 "StopStartTest_NotAvailable" 2 "StopStartTest_Error" 1 "StopStartTest_StartTheTest" 0 "StopStartTest_StopTheTest" ;
VAL_ 2449453039 InstrTestSpeakerCmd 7 "InstrTestSpeakerCmd_NotAvailable" 6 "InstrTestSpeakerCmd_PlaySoundInSubwoofer" 5 "InstrTestSpeakerCmd_PlaySoundInRearLeftAudioSpeaker" 4 "InstrTestSpeakerCmd_PlaySoundInRearRightAudioSpeaker" 3 "InstrTestSpeakerCmd_PlaySoundInFrontRightAudioSpeaker" 2 "InstrTestSpeakerCmd_PlaySoundInFrontLeftAudioSpeaker" 1 "InstrTestSpeakerCmd_PlaySoundInClusterSpeaker" 0 "InstrTestSpeakerCmd_StopPlaySound" ;
VAL_ 2432675791 EnginePreheatAlert_cmd 7 "Telltale_cmd_NotAvailable" 6 "Telltale_cmd_ErrorIndication" 5 "Telltale_cmd_Spare_02" 4 "Telltale_cmd_Spare_01" 3 "Telltale_cmd_Spare" 2 "Telltale_cmd_Flashing" 1 "Telltale_cmd_OnSteady" 0 "Telltale_cmd_Off" ;
VAL_ 2432675791 DifferentialLockWheelAlert_cmd 7 "Telltale_cmd_NotAvailable" 6 "Telltale_cmd_ErrorIndication" 5 "Telltale_cmd_Spare_02" 4 "Telltale_cmd_Spare_01" 3 "Telltale_cmd_Spare" 2 "Telltale_cmd_Flashing" 1 "Telltale_cmd_OnSteady" 0 "Telltale_cmd_Off" ;
VAL_ 2432675791 AutotestCmd 1 "AutotestCmd_AutotestOngoing" 0 "AutotestCmd_NoAutotest" ;
VAL_ 2432675791 SpeedometerPSDViewSpeedUnit 3 "SpeedUnit_NotAvailable" 2 "SpeedUnit_Error" 1 "SpeedUnit_MilesPerHour" 0 "SpeedUnit_KilometersPerHour" ;
VAL_ 2432675791 TripmeterResetCmd2 3 "GUIEventCmd_NotAvailable" 2 "GUIEventCmd_Error" 1 "GUIEventCmd_Activated" 0 "GUIEventCmd_Neutral" ;
VAL_ 2432675791 TripmeterResetCmd1 3 "GUIEventCmd_NotAvailable" 2 "GUIEventCmd_Error" 1 "GUIEventCmd_Activated" 0 "GUIEventCmd_Neutral" ;
VAL_ 2432675791 ASR_cmd 7 "Telltale_cmd_NotAvailable" 6 "Telltale_cmd_ErrorIndication" 5 "Telltale_cmd_Spare_02" 4 "Telltale_cmd_Spare_01" 3 "Telltale_cmd_Spare" 2 "Telltale_cmd_Flashing" 1 "Telltale_cmd_OnSteady" 0 "Telltale_cmd_Off" ;
VAL_ 2432675791 DiffLockInteraxleAlert_cmd 7 "Telltale_cmd_NotAvailable" 6 "Telltale_cmd_ErrorIndication" 5 "Telltale_cmd_Spare_02" 4 "Telltale_cmd_Spare_01" 3 "Telltale_cmd_Spare" 2 "Telltale_cmd_Flashing" 1 "Telltale_cmd_OnSteady" 0 "Telltale_cmd_Off" ;
VAL_ 2432675759 PresVal_ASLSpeedBlinkCmd 3 "OffOn_NotAvailable" 2 "OffOn_Error" 1 "OffOn_On" 0 "OffOn_Off" ;
VAL_ 2432675759 PresVal_GearLeverModeBlink 3 "ModeBlink_NotAvailable" 2 "ModeBlink_Error" 1 "ModeBlink_Blink" 0 "ModeBlink_SteadyLight" ;
VAL_ 2432675759 PresValReqTimeGap 7 "PresValReqTimeGap_NotAvailable" 6 "PresValReqTimeGap_Error" 5 "PresValReqTimeGap_Spare_02" 4 "PresValReqTimeGap_Spare_01" 3 "PresValReqTimeGap_Spare" 2 "PresValReqTimeGap_TimeGap3" 1 "PresValReqTimeGap_TimeGap2" 0 "PresValReqTimeGap_TimeGap1" ;
VAL_ 2432675759 PresVal_CCEnabledStatus 3 "OffOn_NotAvailable" 2 "OffOn_Error" 1 "OffOn_On" 0 "OffOn_Off" ;
VAL_ 2432675759 PresVal_ASLActiveStatus 3 "OffOn_NotAvailable" 2 "OffOn_Error" 1 "OffOn_On" 0 "OffOn_Off" ;
VAL_ 2432675759 PresVal_CCSpeedInactive 3 "OffOn_NotAvailable" 2 "OffOn_Error" 1 "OffOn_On" 0 "OffOn_Off" ;
VAL_ 2432675759 PresVal_CoolantTempHigh 3 "InactiveActive_NotAvailable" 2 "InactiveActive_Error" 1 "InactiveActive_Active" 0 "InactiveActive_Inactive" ;
VAL_ 2432675759 PresVal_CCActiveStatus 3 "OffOn_NotAvailable" 2 "OffOn_Error" 1 "OffOn_On" 0 "OffOn_Off" ;
VAL_ 2432675759 PresVal_CCSpeedBlinkCmd 3 "OffOn_NotAvailable" 2 "OffOn_Error" 1 "OffOn_On" 0 "OffOn_Off" ;
VAL_ 2432675759 PresVal_GearLeverModeFrame 3 "PresVal_GearLeverModeFrame_NotAvailable" 2 "PresVal_GearLeverModeFrame_Error" 1 "PresVal_GearLeverModeFrame_FrameLightOn" 0 "PresVal_GearLeverModeFrame_FrameLightOff" ;
VAL_ 2432659343 PresVal_ClockPeriod 7 "PresVal_ClockPeriod_NotAvailable" 6 "PresVal_ClockPeriod_Error" 2 "PresVal_ClockPeriod_24Hour" 1 "PresVal_ClockPeriod_Pm" 0 "PresVal_ClockPeriod_Am" ;
VAL_ 2432651183 PresVal_OdometerUnit 3 "DistanceUnit_NotAvailable" 2 "DistanceUnit_Error" 1 "DistanceUnit_Miles" 0 "DistanceUnit_Kilometers" ;
VAL_ 2432651183 ZoningBandsActiveBlueLEDRange2 7 "ZoningBandsActiveLEDRange_NotAvailable" 6 "ZoningBandsActiveLEDRange_Error" 5 "ZoningBandsActiveLEDRange_Spare_02" 4 "ZoningBandsActiveLEDRange_Spare_01" 3 "ZoningBandsActiveLEDRange_Spare" 2 "ZoningBandsActiveLEDRange_Flashing" 1 "ZoningBandsActiveLEDRange_On" 0 "ZoningBandsActiveLEDRange_Off" ;
VAL_ 2432651183 ZoningBandsActiveBlueLEDRange1 7 "ZoningBandsActiveLEDRange_NotAvailable" 6 "ZoningBandsActiveLEDRange_Error" 5 "ZoningBandsActiveLEDRange_Spare_02" 4 "ZoningBandsActiveLEDRange_Spare_01" 3 "ZoningBandsActiveLEDRange_Spare" 2 "ZoningBandsActiveLEDRange_Flashing" 1 "ZoningBandsActiveLEDRange_On" 0 "ZoningBandsActiveLEDRange_Off" ;
VAL_ 2432651183 PresVal_LowFuelLevelWrn_stat 3 "OffOn_NotAvailable" 2 "OffOn_Error" 1 "OffOn_On" 0 "OffOn_Off" ;
VAL_ 2432651183 LCDFormattedVehSpdBlink_cmd 3 "OffOn_NotAvailable" 2 "OffOn_Error" 1 "OffOn_On" 0 "OffOn_Off" ;
VAL_ 2432651183 PresVal_ACCReducedMode 3 "PresVal_ACCReducedMode_NotAvailable" 2 "PresVal_ACCReducedMode_Error" 1 "PresVal_ACCReducedMode_ACCInReducedMode" 0 "PresVal_ACCReducedMode_ACCNotInReducedMode" ;
VAL_ 2432651183 PresVal_AuxiliaryBrakesActivat 3 "OffOn_NotAvailable" 2 "OffOn_Error" 1 "OffOn_On" 0 "OffOn_Off" ;
VAL_ 2432651183 PresVal_AmbientAirTempUnit 3 "PresVal_AmbientAirTempUnit_NotAvailable" 2 "PresVal_AmbientAirTempUnit_Error" 1 "PresVal_AmbientAirTempUnit_Fahrenheit" 0 "PresVal_AmbientAirTempUnit_Celsius" ;
VAL_ 2432651183 PresVal_TargetDetected 3 "NotDetected_NotAvaliable" 2 "NotDetected_Error" 1 "NotDetected_Detected" 0 "NotDetected_NotDetected" ;
VAL_ 2432651183 SeatBeltReminderAlert_cmd 7 "Telltale_cmd_NotAvailable" 6 "Telltale_cmd_ErrorIndication" 5 "Telltale_cmd_Spare_02" 4 "Telltale_cmd_Spare_01" 3 "Telltale_cmd_Spare" 2 "Telltale_cmd_Flashing" 1 "Telltale_cmd_OnSteady" 0 "Telltale_cmd_Off" ;
VAL_ 2432651183 PresVal_CrossCountryStatus 3 "OffOn_NotAvailable" 2 "OffOn_Error" 1 "OffOn_On" 0 "OffOn_Off" ;
VAL_ 2432651183 PresVal_TripmeterChoice 3 "TripMeter_NotAvailable" 2 "TripMeter_Error" 1 "TripMeter_Tripcounter2" 0 "TripMeter_Tripcounter1" ;
VAL_ 2432651183 ZoningBandsActiveGreenLEDRng2 7 "ZoningBandsActiveLEDRange_NotAvailable" 6 "ZoningBandsActiveLEDRange_Error" 5 "ZoningBandsActiveLEDRange_Spare_02" 4 "ZoningBandsActiveLEDRange_Spare_01" 3 "ZoningBandsActiveLEDRange_Spare" 2 "ZoningBandsActiveLEDRange_Flashing" 1 "ZoningBandsActiveLEDRange_On" 0 "ZoningBandsActiveLEDRange_Off" ;
VAL_ 2432651183 SIDPresentationMode 15 "SIDPresentationMode_NotAvailable" 14 "SIDPresentationMode_Error" 13 "SIDPresentationMode_Spare_09" 12 "SIDPresentationMode_Spare_08" 11 "SIDPresentationMode_Spare_07" 10 "SIDPresentationMode_Spare_06" 9 "SIDPresentationMode_Spare_05" 8 "SIDPresentationMode_Spare_04" 7 "SIDPresentationMode_Spare_03" 6 "SIDPresentationMode_Spare_02" 5 "SIDPresentationMode_Spare_01" 4 "SIDPresentationMode_UnmutePage" 3 "SIDPresentationMode_MutePage" 2 "SIDPresentationMode_ApplicationNotAvailablePage" 1 "SIDPresentationMode_WaitPage" 0 "SIDPresentationMode_LVDSNormalMode" ;
VAL_ 2432651183 VehicleSpeedLCDSpeedUnitCmd 3 "SpeedUnit_NotAvailable" 2 "SpeedUnit_Error" 1 "SpeedUnit_MilesPerHour" 0 "SpeedUnit_KilometersPerHour" ;
VAL_ 2432651183 PresVal_CatalystTankLevelLow 3 "PresVal_CatalystTankLevelLow_NotAvailable" 2 "PresVal_CatalystTankLevelLow_Error" 1 "PresVal_CatalystTankLevelLow_TankLevelLow" 0 "PresVal_CatalystTankLevelLow_TankLevelNotLow" ;
VAL_ 2432651183 PresVal_ACCStatus 3 "OffOn_NotAvailable" 2 "OffOn_Error" 1 "OffOn_On" 0 "OffOn_Off" ;
VAL_ 2432651183 PresVal_AuxiliaryBrakesPos 7 "PresVal_AuxiliaryBrakesPos_NotAvailable" 6 "PresVal_AuxiliaryBrakesPos_ErrorIndicator" 5 "PresVal_AuxiliaryBrakesPos_SpareValue" 4 "PresVal_AuxiliaryBrakesPos_PositionA" 3 "PresVal_AuxiliaryBrakesPos_Position3" 2 "PresVal_AuxiliaryBrakesPos_Position2" 1 "PresVal_AuxiliaryBrakesPos_Position1" 0 "PresVal_AuxiliaryBrakesPos_Off" ;
VAL_ 2432651183 PresVal_EngSpdCtrlStatus 3 "OffOn_NotAvailable" 2 "OffOn_Error" 1 "OffOn_On" 0 "OffOn_Off" ;
VAL_ 2432651183 ZoningBandsActiveRedLEDRange1 7 "ZoningBandsActiveLEDRange_NotAvailable" 6 "ZoningBandsActiveLEDRange_Error" 5 "ZoningBandsActiveLEDRange_Spare_02" 4 "ZoningBandsActiveLEDRange_Spare_01" 3 "ZoningBandsActiveLEDRange_Spare" 2 "ZoningBandsActiveLEDRange_Flashing" 1 "ZoningBandsActiveLEDRange_On" 0 "ZoningBandsActiveLEDRange_Off" ;
VAL_ 2432651183 PresVal_LowAmbientTempWarning 3 "FalseTrue_NotAvaiable" 2 "FalseTrue_Error" 1 "FalseTrue_True" 0 "FalseTrue_False" ;
VAL_ 2432651183 ZoningBandsActiveGreenLEDRng1 7 "ZoningBandsActiveLEDRange_NotAvailable" 6 "ZoningBandsActiveLEDRange_Error" 5 "ZoningBandsActiveLEDRange_Spare_02" 4 "ZoningBandsActiveLEDRange_Spare_01" 3 "ZoningBandsActiveLEDRange_Spare" 2 "ZoningBandsActiveLEDRange_Flashing" 1 "ZoningBandsActiveLEDRange_On" 0 "ZoningBandsActiveLEDRange_Off" ;
VAL_ 2432643023 ClusterSSReq_Balance 3 "SystemSoundBalance_Spare" 2 "SystemSoundBalance_Right" 1 "SystemSoundBalance_Left" 0 "SystemSoundBalance_Both" ;
VAL_ 2432643023 ClusterSSReq_State 1 "SystemSoundState_Play" 0 "SystemSoundState_Stop" ;
VAL_ 2432643023 ClusterSSReq_Mixed 1 "SystemSoundMixed_MixedWithBackgroungSound" 0 "SystemSoundMixed_BackgroundSoundMuted" ;
VAL_ 2432634863 DippedBeamAlert_cmd 7 "Telltale_cmd_NotAvailable" 6 "Telltale_cmd_ErrorIndication" 5 "Telltale_cmd_Spare_02" 4 "Telltale_cmd_Spare_01" 3 "Telltale_cmd_Spare" 2 "Telltale_cmd_Flashing" 1 "Telltale_cmd_OnSteady" 0 "Telltale_cmd_Off" ;
VAL_ 2432634863 VehicleMode 15 "VehicleMode_NotAvailable" 14 "VehicleMode_Error" 13 "VehicleMode_Spare_7" 12 "VehicleMode_Spare_6" 11 "VehicleMode_Spare_5" 10 "VehicleMode_Spare_4" 9 "VehicleMode_Spare_3" 8 "VehicleMode_Spare_2" 7 "VehicleMode_Spare_1" 6 "VehicleMode_Running" 5 "VehicleMode_Cranking" 4 "VehicleMode_PreRunning" 3 "VehicleMode_Accessory" 2 "VehicleMode_Living" 1 "VehicleMode_Parked" 0 "VehicleMode_Hibernate" ;
VAL_ 2432634863 LiftAxle1Alert_cmd 7 "Telltale_cmd_NotAvailable" 6 "Telltale_cmd_ErrorIndication" 5 "Telltale_cmd_Spare_02" 4 "Telltale_cmd_Spare_01" 3 "Telltale_cmd_Spare" 2 "Telltale_cmd_Flashing" 1 "Telltale_cmd_OnSteady" 0 "Telltale_cmd_Off" ;
VAL_ 2432634863 DirIndicatorRtTrailerAlert_cmd 7 "Telltale_cmd_NotAvailable" 6 "Telltale_cmd_ErrorIndication" 5 "Telltale_cmd_Spare_02" 4 "Telltale_cmd_Spare_01" 3 "Telltale_cmd_Spare" 2 "Telltale_cmd_Flashing" 1 "Telltale_cmd_OnSteady" 0 "Telltale_cmd_Off" ;
VAL_ 2432634863 FogLightFrontAlert_cmd 7 "Telltale_cmd_NotAvailable" 6 "Telltale_cmd_ErrorIndication" 5 "Telltale_cmd_Spare_02" 4 "Telltale_cmd_Spare_01" 3 "Telltale_cmd_Spare" 2 "Telltale_cmd_Flashing" 1 "Telltale_cmd_OnSteady" 0 "Telltale_cmd_Off" ;
VAL_ 2432634863 LiftAxle2Alert_cmd 7 "Telltale_cmd_NotAvailable" 6 "Telltale_cmd_ErrorIndication" 5 "Telltale_cmd_Spare_02" 4 "Telltale_cmd_Spare_01" 3 "Telltale_cmd_Spare" 2 "Telltale_cmd_Flashing" 1 "Telltale_cmd_OnSteady" 0 "Telltale_cmd_Off" ;
VAL_ 2432634863 ExtraSpotLampsAlert_cmd 7 "Telltale_cmd_NotAvailable" 6 "Telltale_cmd_ErrorIndication" 5 "Telltale_cmd_Spare_02" 4 "Telltale_cmd_Spare_01" 3 "Telltale_cmd_Spare" 2 "Telltale_cmd_Flashing" 1 "Telltale_cmd_OnSteady" 0 "Telltale_cmd_Off" ;
VAL_ 2432634863 AdBlueLevelLowAlert_cmd 7 "Telltale_cmd_NotAvailable" 6 "Telltale_cmd_ErrorIndication" 5 "Telltale_cmd_Spare_02" 4 "Telltale_cmd_Spare_01" 3 "Telltale_cmd_Spare" 2 "Telltale_cmd_Flashing" 1 "Telltale_cmd_OnSteady" 0 "Telltale_cmd_Off" ;
VAL_ 2432634863 DirIndicatorLtTrailerAlert_cmd 7 "Telltale_cmd_NotAvailable" 6 "Telltale_cmd_ErrorIndication" 5 "Telltale_cmd_Spare_02" 4 "Telltale_cmd_Spare_01" 3 "Telltale_cmd_Spare" 2 "Telltale_cmd_Flashing" 1 "Telltale_cmd_OnSteady" 0 "Telltale_cmd_Off" ;
VAL_ 2432634863 EngineMalFunctionAlert_cmd 7 "Telltale_cmd_NotAvailable" 6 "Telltale_cmd_ErrorIndication" 5 "Telltale_cmd_Spare_02" 4 "Telltale_cmd_Spare_01" 3 "Telltale_cmd_Spare" 2 "Telltale_cmd_Flashing" 1 "Telltale_cmd_OnSteady" 0 "Telltale_cmd_Off" ;
VAL_ 2432634863 FuelLevelLowAlert_cmd 7 "Telltale_cmd_NotAvailable" 6 "Telltale_cmd_ErrorIndication" 5 "Telltale_cmd_Spare_02" 4 "Telltale_cmd_Spare_01" 3 "Telltale_cmd_Spare" 2 "Telltale_cmd_Flashing" 1 "Telltale_cmd_OnSteady" 0 "Telltale_cmd_Off" ;
VAL_ 2432634863 PosLightAlert_cmd 7 "Telltale_cmd_NotAvailable" 6 "Telltale_cmd_ErrorIndication" 5 "Telltale_cmd_Spare_02" 4 "Telltale_cmd_Spare_01" 3 "Telltale_cmd_Spare" 2 "Telltale_cmd_Flashing" 1 "Telltale_cmd_OnSteady" 0 "Telltale_cmd_Off" ;
VAL_ 2432634863 MainBeamAlert_cmd 7 "Telltale_cmd_NotAvailable" 6 "Telltale_cmd_ErrorIndication" 5 "Telltale_cmd_Spare_02" 4 "Telltale_cmd_Spare_01" 3 "Telltale_cmd_Spare" 2 "Telltale_cmd_Flashing" 1 "Telltale_cmd_OnSteady" 0 "Telltale_cmd_Off" ;
VAL_ 2432634863 DirIndicatorRightAlert_cmd 7 "Telltale_cmd_NotAvailable" 6 "Telltale_cmd_ErrorIndication" 5 "Telltale_cmd_Spare_02" 4 "Telltale_cmd_Spare_01" 3 "Telltale_cmd_Spare" 2 "Telltale_cmd_Flashing" 1 "Telltale_cmd_OnSteady" 0 "Telltale_cmd_Off" ;
VAL_ 2432634863 ParkBrakeAlert_cmd 7 "Telltale_cmd_NotAvailable" 6 "Telltale_cmd_ErrorIndication" 5 "Telltale_cmd_Spare_02" 4 "Telltale_cmd_Spare_01" 3 "Telltale_cmd_Spare" 2 "Telltale_cmd_Flashing" 1 "Telltale_cmd_OnSteady" 0 "Telltale_cmd_Off" ;
VAL_ 2432634863 FogLightRearAlert_cmd 7 "Telltale_cmd_NotAvailable" 6 "Telltale_cmd_ErrorIndication" 5 "Telltale_cmd_Spare_02" 4 "Telltale_cmd_Spare_01" 3 "Telltale_cmd_Spare" 2 "Telltale_cmd_Flashing" 1 "Telltale_cmd_OnSteady" 0 "Telltale_cmd_Off" ;
VAL_ 2432634863 DirIndicatorLeftAlert_cmd 7 "Telltale_cmd_NotAvailable" 6 "Telltale_cmd_ErrorIndication" 5 "Telltale_cmd_Spare_02" 4 "Telltale_cmd_Spare_01" 3 "Telltale_cmd_Spare" 2 "Telltale_cmd_Flashing" 1 "Telltale_cmd_OnSteady" 0 "Telltale_cmd_Off" ;
VAL_ 2432634863 CheckAlert_cmd 7 "Telltale_cmd_NotAvailable" 6 "Telltale_cmd_ErrorIndication" 5 "Telltale_cmd_Spare_02" 4 "Telltale_cmd_Spare_01" 3 "Telltale_cmd_Spare" 2 "Telltale_cmd_Flashing" 1 "Telltale_cmd_OnSteady" 0 "Telltale_cmd_Off" ;
VAL_ 2432634863 StopAlert_cmd 7 "Telltale_cmd_NotAvailable" 6 "Telltale_cmd_ErrorIndication" 5 "Telltale_cmd_Spare_02" 4 "Telltale_cmd_Spare_01" 3 "Telltale_cmd_Spare" 2 "Telltale_cmd_Flashing" 1 "Telltale_cmd_OnSteady" 0 "Telltale_cmd_Off" ;
SIG_GROUP_ 2432692031 SIDTouchScreenCoordinates_sg 1 : SIDTouchScreenCoordinates_Y SIDTouchScreenCoordinates_X;
SIG_GROUP_ 2432691983 ClusterSSStat_sg 1 : ClusterSSStat_General ClusterSSStat_Id ClusterSSStat_PlayStat;
SIG_GROUP_ 2432643023 ClusterSSReq_sg 1 : ClusterSSReq_Volume ClusterSSReq_Repetition ClusterSSReq_Balance ClusterSSReq_Id ClusterSSReq_State ClusterSSReq_Mixed ClusterSSReq_Time;
SIG_GROUP_ 2567045123 DiagFaultStat_SIDH_sg 1 : DiagFaultStat_SIDH_DtcIdB DiagFaultStat_SIDH_FailTB DiagFaultStat_SIDH_DtcIdA DiagFaultStat_SIDH_FailTA DiagFaultStat_SIDH_EcuAdr;
SIG_GROUP_ 2567045121 DiagFaultStat_IC_sg 1 : DiagFaultStat_IC_DtcIdA DiagFaultStat_IC_FailTA DiagFaultStat_IC_EcuAdr DiagFaultStat_IC_FailTB DiagFaultStat_IC_DtcIdB;
